VERSION ""

NS_ :

BS_:

BU_: SBZA_R_LS SBZA_L_LS VIS2_LS SDM_LS PEPS_LS UPA_LS PTM_LS MSM_LS HFP_LS EOCM_F_LS ECC_LS DCAC_LS CGM_LS BSM_LS BCM_LS AOS_LS

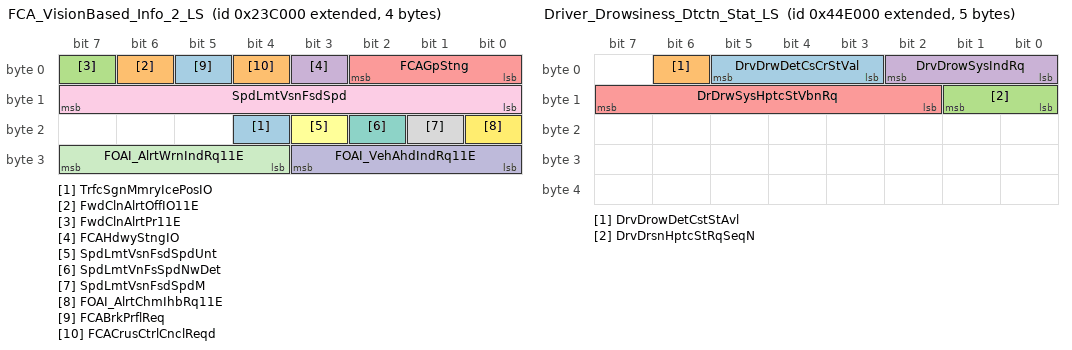
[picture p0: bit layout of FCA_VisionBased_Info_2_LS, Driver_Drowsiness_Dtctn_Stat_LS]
BO_ 2149826560 FCA_VisionBased_Info_2_LS: 4 VIS2_LS
 SG_ TrfcSgnMmryIcePosIO : 20|1@0+ (1,0) [0|1] ""  CGM_LS
 SG_ FwdClnAlrtOffIO11E : 6|1@0+ (1,0) [0|1] ""  CGM_LS
 SG_ FwdClnAlrtPr11E : 7|1@0+ (1,0) [0|1] ""  CGM_LS
 SG_ FCAHdwyStngIO : 3|1@0+ (1,0) [0|1] ""  CGM_LS
 SG_ FCAGpStng : 2|3@0+ (1,0) [0|7] ""  CGM_LS
 SG_ SpdLmtVsnFsdSpdUnt : 19|1@0+ (1,0) [0|1] ""  CGM_LS,BCM_LS
 SG_ SpdLmtVnFsSpdNwDet : 18|1@0+ (1,0) [0|1] ""  CGM_LS,BCM_LS
 SG_ SpdLmtVsnFsdSpdM : 17|1@0+ (1,0) [0|1] ""  CGM_LS,BCM_LS
 SG_ SpdLmtVsnFsdSpd : 15|8@0+ (1,0) [0|255] ""  CGM_LS,BCM_LS
 SG_ FOAI_VehAhdIndRq11E : 27|4@0+ (1,0) [0|15] ""  CGM_LS,BCM_LS
 SG_ FOAI_AlrtWrnIndRq11E : 31|4@0+ (1,0) [0|15] ""  CGM_LS,BCM_LS
 SG_ FOAI_AlrtChmIhbRq11E : 16|1@0+ (1,0) [0|1] ""  CGM_LS,BCM_LS
 SG_ FCABrkPrflReq : 5|1@0+ (1,0) [0|1] ""  CGM_LS,BCM_LS
 SG_ FCACrusCtrlCnclReqd : 4|1@0+ (1,0) [0|1] ""  CGM_LS,BCM_LS

BO_ 2151997440 Driver_Drowsiness_Dtctn_Stat_LS: 5 VIS2_LS
 SG_ DrvDrwDetCsCrStVal : 5|3@0+ (1,0) [0|7] ""  CGM_LS
 SG_ DrvDrowDetCstStAvl : 6|1@0+ (1,0) [0|1] ""  CGM_LS
 SG_ DrvDrsnHptcStRqSeqN : 9|2@0+ (1,0) [0|3] ""  MSM_LS,CGM_LS
 SG_ DrvDrowSysIndRq : 2|3@0+ (1,0) [0|7] ""  CGM_LS,BCM_LS
 SG_ DrDrwSysHptcStVbnRq : 15|6@0+ (1,0) [0|63] ""  MSM_LS,CGM_LS,BCM_LS

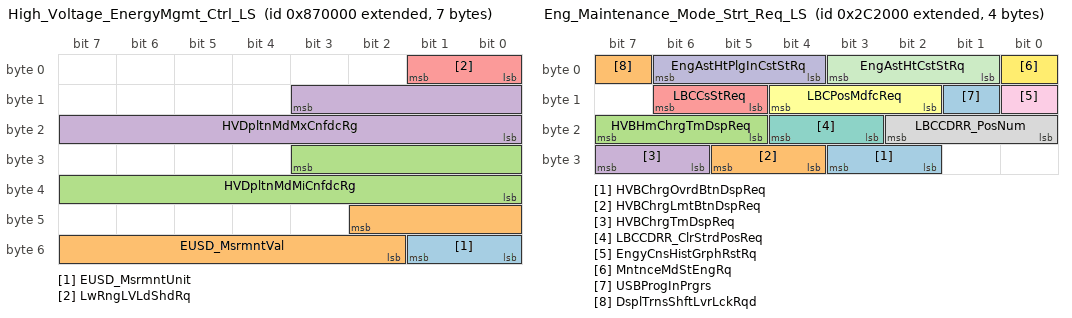
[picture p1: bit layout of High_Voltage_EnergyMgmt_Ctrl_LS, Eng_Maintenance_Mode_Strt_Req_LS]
BO_ 2156331008 High_Voltage_EnergyMgmt_Ctrl_LS: 7 BSM_LS
 SG_ EUSD_MsrmntUnit : 49|2@0+ (1,0) [0|3] ""  CGM_LS
 SG_ EUSD_MsrmntVal : 42|9@0+ (1,0) [0|511] ""  CGM_LS
 SG_ HVDpltnMdMiCnfdcRg : 27|12@0+ (0.1,0) [0|409.5] "km"  CGM_LS
 SG_ HVDpltnMdMxCnfdcRg : 11|12@0+ (0.1,0) [0|409.5] "km"  CGM_LS
 SG_ LwRngLVLdShdRq : 1|2@0+ (1,0) [0|3] ""  CGM_LS,BCM_LS

BO_ 2150375424 Eng_Maintenance_Mode_Strt_Req_LS: 4 CGM_LS
 SG_ HVBChrgOvrdBtnDspReq : 27|2@0+ (1,0) [0|3] "" Vector__XXX
 SG_ HVBChrgLmtBtnDspReq : 29|2@0+ (1,0) [0|3] "" Vector__XXX
 SG_ HVBHmChrgTmDspReq : 23|3@0+ (1,0) [0|7] "" Vector__XXX
 SG_ HVBChrgTmDspReq : 31|2@0+ (1,0) [0|3] "" Vector__XXX
 SG_ LBCCsStReq : 14|2@0+ (1,0) [0|3] ""  BSM_LS
 SG_ LBCPosMdfcReq : 12|3@0+ (1,0) [0|7] ""  BSM_LS
 SG_ LBCCDRR_ClrStrdPosReq : 20|2@0+ (1,0) [0|3] ""  BSM_LS
 SG_ LBCCDRR_PosNum : 18|3@0+ (1,0) [0|7] ""  BSM_LS
 SG_ EngyCnsHistGrphRstRq : 8|1@0+ (1,0) [0|1] ""  BSM_LS
 SG_ EngAstHtPlgInCstStRq : 6|3@0+ (1,0) [0|7] ""  BSM_LS
 SG_ EngAstHtCstStRq : 3|3@0+ (1,0) [0|7] ""  BSM_LS
 SG_ MntnceMdStEngRq : 0|1@0+ (1,0) [0|1] ""  BSM_LS
 SG_ USBProgInPrgrs : 9|1@0+ (1,0) [0|1] ""  BCM_LS
 SG_ DsplTrnsShftLvrLckRqd : 7|1@0+ (1,0) [0|1] ""  BCM_LS

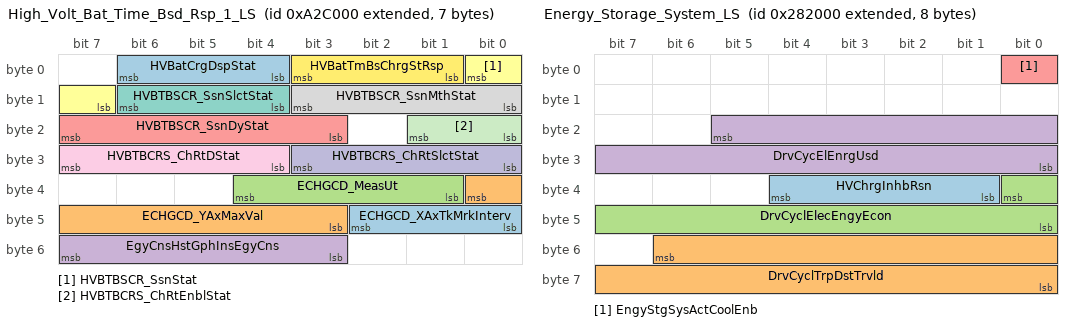
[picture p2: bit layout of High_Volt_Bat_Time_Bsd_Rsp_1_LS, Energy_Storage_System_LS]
BO_ 2158149632 High_Volt_Bat_Time_Bsd_Rsp_1_LS: 7 BSM_LS
 SG_ ECHGCD_XAxTkMrkInterv : 42|3@0+ (1,0) [0|7] ""  CGM_LS
 SG_ ECHGCD_YAxMaxVal : 32|6@0+ (4,0) [0|252] ""  CGM_LS
 SG_ ECHGCD_MeasUt : 36|4@0+ (1,0) [0|15] ""  CGM_LS
 SG_ EgyCnsHstGphInsEgyCns : 55|5@0+ (1,0) [0|31] ""  CGM_LS
 SG_ HVBTBSCR_SsnDyStat : 23|5@0+ (1,0) [0|31] "day"  CGM_LS
 SG_ HVBTBSCR_SsnStat : 0|2@0+ (1,0) [0|3] ""  CGM_LS
 SG_ HVBTBSCR_SsnSlctStat : 14|3@0+ (1,0) [0|7] ""  CGM_LS
 SG_ HVBTBSCR_SsnMthStat : 11|4@0+ (1,0) [0|15] ""  CGM_LS
 SG_ HVBTBCRS_ChRtDStat : 31|4@0+ (1,0) [0|15] ""  CGM_LS
 SG_ HVBTBCRS_ChRtSlctStat : 27|4@0+ (1,0) [0|15] ""  CGM_LS
 SG_ HVBTBCRS_ChRtEnblStat : 17|2@0+ (1,0) [0|3] ""  CGM_LS
 SG_ HVBatTmBsChrgStRsp : 3|3@0+ (1,0) [0|7] ""  CGM_LS,BCM_LS
 SG_ HVBatCrgDspStat : 6|3@0+ (1,0) [0|7] ""  CGM_LS,BCM_LS

BO_ 2150113280 Energy_Storage_System_LS: 8 BSM_LS
 SG_ HVChrgInhbRsn : 36|4@0+ (1,0) [0|15] ""  CGM_LS
 SG_ DrvCyclTrpDstTrvld : 54|15@0+ (0.1,0) [0|3276.7] "km"  CGM_LS
 SG_ DrvCyclElecEngyEcon : 32|9@0+ (0.1,0) [0|51.1] ""  CGM_LS
 SG_ DrvCycElEnrgUsd : 21|14@0+ (0.36,0) [0|5897.88] "MJ"  CGM_LS
 SG_ EngyStgSysActCoolEnb : 0|1@0+ (1,0) [0|1] ""  ECC_LS,CGM_LS,BCM_LS

BO_ 2150547456 HMI_Hybrid_Vehicle_Status_LS: 8 BSM_LS
 SG_ HVDpltnMdCnfdcTrndg : 47|8@0- (0.787402,0) [-100.787456|100.000054] "%"  CGM_LS
 SG_ OffBrdHVCVehPwrLvl : 55|2@0+ (1,0) [0|3] ""  CGM_LS
 SG_ OffBrdHVCVehPwrDrtd : 26|1@0+ (1,0) [0|1] ""  CGM_LS
 SG_ OffBrdHVCVehCplrLkd : 16|1@0+ (1,0) [0|1] ""  CGM_LS
 SG_ OffBrdHVBlkChrgCmp : 37|1@0+ (1,0) [0|1] ""  CGM_LS
 SG_ OBHVBCCT_MinofHr : 61|6@0+ (1,0) [0|63] ""  CGM_LS
 SG_ OBHVBCCT_HrofDay : 50|5@0+ (1,0) [0|31] ""  CGM_LS
 SG_ OBHVBCCT_DayofWk : 53|3@0+ (1,0) [0|7] ""  CGM_LS
 SG_ ElecPrplsnMtrOvrSpdIO : 38|1@0+ (1,0) [0|1] ""  CGM_LS
 SG_ HVBatOutOfEnrgyInd : 36|3@0+ (1,0) [0|7] ""  CGM_LS
 SG_ CntrsOpnUndrTmpIO : 7|1@0+ (1,0) [0|1] ""  CGM_LS
 SG_ HVBatCntctrsOpnIO : 39|1@0+ (1,0) [0|1] ""  CGM_LS
 SG_ GrnAudQueReq : 4|1@0+ (1,0) [0|1] ""  CGM_LS
 SG_ SvcHybChrgSysIO : 5|1@0+ (1,0) [0|1] ""  CGM_LS
 SG_ HVChrgrSysStat : 29|3@0+ (1,0) [0|7] ""  CGM_LS
 SG_ HVChrgrCplrStat : 31|2@0+ (1,0) [0|3] ""  ECC_LS,CGM_LS
 SG_ HVBatLimDTmpInd : 25|2@0+ (1,0) [0|3] ""  CGM_LS
 SG_ VehChrgMdSt : 3|3@0+ (1,0) [0|7] ""  CGM_LS
 SG_ HVBatChrgCrdConnIO : 6|1@0+ (1,0) [0|1] ""  CGM_LS,BCM_LS
 SG_ HVDpltnMdRng : 0|16@0+ (0.015625,0) [0|1023.984375] "km"  CGM_LS,BCM_LS
 SG_ ChgrSysAdblIndReq : 33|2@0+ (1,0) [0|3] ""  CGM_LS,BCM_LS

BO_ 2149728256 Charging_Sys_Trans_Shift_Lock_LS: 5 BSM_LS
 SG_ EngAstHtPlgInCsStAvl : 31|1@0+ (1,0) [0|1] ""  CGM_LS
 SG_ EngAstHtPlgInCsCrStVl : 30|3@0+ (1,0) [0|7] ""  CGM_LS
 SG_ EngAstHtCsStAvl : 27|1@0+ (1,0) [0|1] ""  CGM_LS
 SG_ EngAstHtCsCrStVal : 26|3@0+ (1,0) [0|7] ""  ECC_LS,CGM_LS
 SG_ HghVltgPropState : 7|3@0+ (1,0) [0|7] ""  CGM_LS
 SG_ ChrgPrtDrStat : 2|2@0+ (1,0) [0|3] ""  CGM_LS
 SG_ ChgCdTfAlCzStAvbl : 11|1@0+ (1,0) [0|1] ""  CGM_LS
 SG_ ChgCdTfAlCzCrStVal : 10|3@0+ (1,0) [0|7] ""  CGM_LS
 SG_ ChgPwLsAlCzStAvbl : 15|1@0+ (1,0) [0|1] ""  CGM_LS
 SG_ ChgPwLsAlCzCrStVal : 14|3@0+ (1,0) [0|7] ""  CGM_LS
 SG_ ChgSysAudInCsStAvl : 19|1@0+ (1,0) [0|1] ""  CGM_LS
 SG_ ChgSyAudInCsCrStVa : 18|3@0+ (1,0) [0|7] ""  CGM_LS
 SG_ PrtyChrgStPnt : 38|7@0+ (1,0) [0|127] ""  CGM_LS,BCM_LS
 SG_ PrtyChrgActIO : 3|1@0+ (1,0) [0|1] ""  CGM_LS,BCM_LS
 SG_ PrtyChrgAct : 4|1@0+ (1,0) [0|1] ""  CGM_LS,BCM_LS
 SG_ HVChrgPwrLvl : 22|3@0+ (1,0) [0|7] ""  CGM_LS,BCM_LS
 SG_ ChrgSysTrnsShftLckRq : 0|1@0+ (1,0) [0|1] ""  CGM_LS,BCM_LS

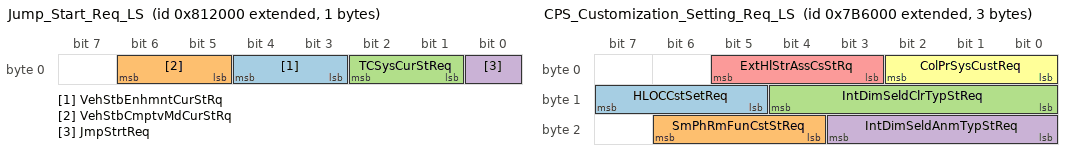
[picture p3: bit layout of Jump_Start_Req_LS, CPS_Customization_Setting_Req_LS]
BO_ 2155945984 Jump_Start_Req_LS: 1 CGM_LS
 SG_ VehStbEnhmntCurStRq : 4|2@0+ (1,0) [0|3] ""  BCM_LS
 SG_ VehStbCmptvMdCurStRq : 6|2@0+ (1,0) [0|3] ""  BCM_LS
 SG_ TCSysCurStReq : 2|2@0+ (1,0) [0|3] ""  BCM_LS
 SG_ JmpStrtReq : 0|1@0+ (1,0) [0|1] ""  BCM_LS

BO_ 2155585536 MSB_Customization_Setting_Req_LS: 1 CGM_LS
 SG_ StBltTgtCSRq : 2|3@0+ (1,0) [0|7] ""  BCM_LS

BO_ 2155569152 CPS_Customization_Setting_Req_LS: 3 CGM_LS
 SG_ HLOCCstSetReq : 15|3@0+ (1,0) [0|7] ""  PTM_LS
 SG_ SmPhRmFunCstStReq : 22|3@0+ (1,0) [0|7] ""  BCM_LS
 SG_ IntDimSeldClrTypStReq : 12|5@0+ (1,0) [0|31] ""  BCM_LS
 SG_ IntDimSeldAnmTypStReq : 19|4@0+ (1,0) [0|15] ""  BCM_LS
 SG_ ExtHlStrAssCsStRq : 5|3@0+ (1,0) [0|7] ""  BCM_LS
 SG_ ColPrSysCustReq : 2|3@0+ (1,0) [0|7] ""  BCM_LS

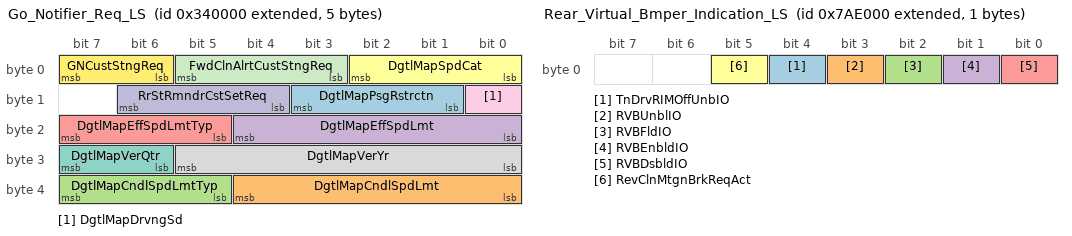
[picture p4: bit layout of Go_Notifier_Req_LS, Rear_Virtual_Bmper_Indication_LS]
BO_ 2150891520 Go_Notifier_Req_LS: 5 CGM_LS
 SG_ DgtlMapPsgRstrctn : 11|3@0+ (1,0) [0|7] ""  VIS2_LS
 SG_ DgtlMapCndlSpdLmt : 36|5@0+ (1,0) [0|31] ""  VIS2_LS
 SG_ DgtlMapCndlSpdLmtTyp : 39|3@0+ (1,0) [0|7] ""  VIS2_LS
 SG_ DgtlMapEffSpdLmt : 20|5@0+ (1,0) [0|31] ""  VIS2_LS
 SG_ DgtlMapEffSpdLmtTyp : 23|3@0+ (1,0) [0|7] ""  VIS2_LS
 SG_ DgtlMapSpdCat : 2|3@0+ (1,0) [0|7] ""  VIS2_LS
 SG_ DgtlMapVerQtr : 31|2@0+ (1,0) [0|3] ""  VIS2_LS
 SG_ DgtlMapVerYr : 29|6@0+ (1,0) [0|63] ""  VIS2_LS
 SG_ DgtlMapDrvngSd : 8|1@0+ (1,0) [0|1] ""  VIS2_LS
 SG_ RrStRmndrCstSetReq : 14|3@0+ (1,0) [0|7] ""  BCM_LS
 SG_ FwdClnAlrtCustStngReq : 5|3@0+ (1,0) [0|7] ""  BCM_LS
 SG_ GNCustStngReq : 7|2@0+ (1,0) [0|3] ""  BCM_LS

BO_ 2155536384 Rear_Virtual_Bmper_Indication_LS: 1 EOCM_F_LS
 SG_ TnDrvRIMOffUnbIO : 4|1@0+ (1,0) [0|1] ""  CGM_LS
 SG_ RVBUnblIO : 3|1@0+ (1,0) [0|1] ""  CGM_LS
 SG_ RVBFldIO : 2|1@0+ (1,0) [0|1] ""  CGM_LS
 SG_ RVBEnbldIO : 1|1@0+ (1,0) [0|1] ""  CGM_LS
 SG_ RVBDsbldIO : 0|1@0+ (1,0) [0|1] ""  SBZA_R_LS,SBZA_L_LS,CGM_LS
 SG_ RevClnMtgnBrkReqAct : 5|1@0+ (1,0) [0|1] ""  CGM_LS,BCM_LS

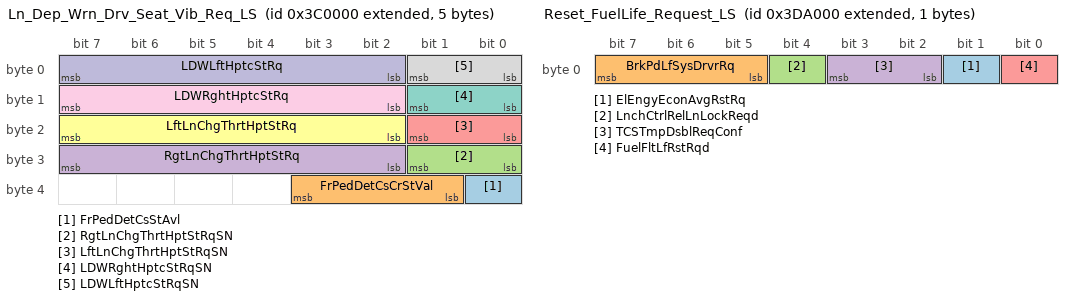
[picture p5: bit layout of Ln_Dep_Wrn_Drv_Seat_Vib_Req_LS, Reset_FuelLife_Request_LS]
BO_ 2151415808 Ln_Dep_Wrn_Drv_Seat_Vib_Req_LS: 5 EOCM_F_LS
 SG_ FrPedDetCsStAvl : 32|1@0+ (1,0) [0|1] ""  MSM_LS,CGM_LS
 SG_ FrPedDetCsCrStVal : 35|3@0+ (1,0) [0|7] ""  MSM_LS,CGM_LS
 SG_ RgtLnChgThrtHptStRqSN : 25|2@0+ (1,0) [0|3] ""  MSM_LS,CGM_LS
 SG_ RgtLnChgThrtHptStRq : 31|6@0+ (1,0) [0|63] "Pulse"  MSM_LS,CGM_LS
 SG_ LftLnChgThrtHptStRqSN : 17|2@0+ (1,0) [0|3] ""  MSM_LS,CGM_LS
 SG_ LftLnChgThrtHptStRq : 23|6@0+ (1,0) [0|63] "Pulse"  MSM_LS,CGM_LS
 SG_ LDWRghtHptcStRqSN : 9|2@0+ (1,0) [0|3] ""  MSM_LS,CGM_LS
 SG_ LDWLftHptcStRqSN : 1|2@0+ (1,0) [0|3] ""  MSM_LS,CGM_LS
 SG_ LDWRghtHptcStRq : 15|6@0+ (1,0) [0|63] ""  MSM_LS,CGM_LS,BCM_LS
 SG_ LDWLftHptcStRq : 7|6@0+ (1,0) [0|63] ""  MSM_LS,CGM_LS,BCM_LS

BO_ 2151522304 Reset_FuelLife_Request_LS: 1 CGM_LS
 SG_ ElEngyEconAvgRstRq : 1|1@0+ (1,0) [0|1] ""  BSM_LS
 SG_ BrkPdLfSysDrvrRq : 7|3@0+ (1,0) [0|7] ""  BCM_LS
 SG_ LnchCtrlRelLnLockReqd : 4|1@0+ (1,0) [0|1] ""  BCM_LS
 SG_ TCSTmpDsblReqConf : 3|2@0+ (1,0) [0|3] ""  BCM_LS
 SG_ FuelFltLfRstRqd : 0|1@0+ (1,0) [0|1] ""  BCM_LS

BO_ 2154979328 Front_Seat_Heat_Cool_Req_LS: 1 MSM_LS
 SG_ FrntStVoltBstModReq : 0|1@0+ (1,0) [0|1] ""  CGM_LS,BCM_LS

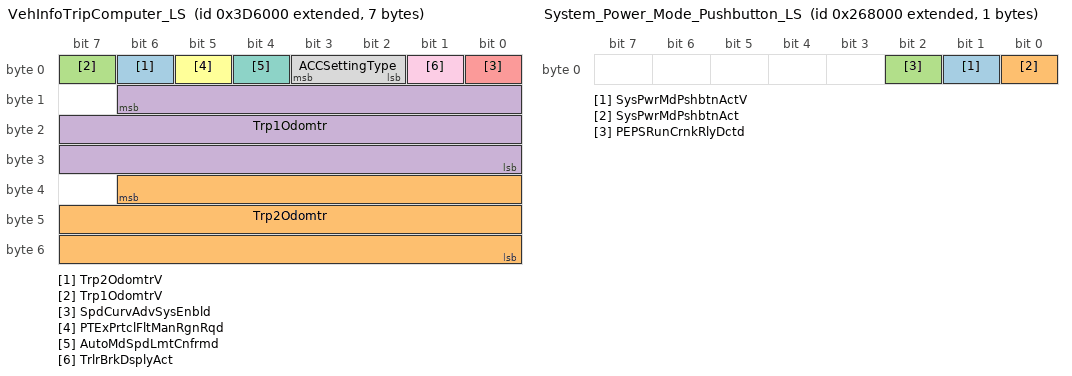
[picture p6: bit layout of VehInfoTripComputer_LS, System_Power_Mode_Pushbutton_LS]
BO_ 2151505920 VehInfoTripComputer_LS: 7 CGM_LS
 SG_ Trp2OdomtrV : 6|1@0+ (1,0) [0|1] "" Vector__XXX
 SG_ Trp2Odomtr : 38|23@0+ (0.015625,0) [0|131071.984375] "km" Vector__XXX
 SG_ Trp1OdomtrV : 7|1@0+ (1,0) [0|1] "" Vector__XXX
 SG_ Trp1Odomtr : 14|23@0+ (0.015625,0) [0|131071.984375] "km" Vector__XXX
 SG_ SpdCurvAdvSysEnbld : 0|1@0+ (1,0) [0|1] "" Vector__XXX
 SG_ PTExPrtclFltManRgnRqd : 5|1@0+ (1,0) [0|1] ""  BCM_LS
 SG_ AutoMdSpdLmtCnfrmd : 4|1@0+ (1,0) [0|1] ""  BCM_LS
 SG_ ACCSettingType : 3|2@0+ (1,0) [0|3] ""  VIS2_LS,BCM_LS
 SG_ TrlrBrkDsplyAct : 1|1@0+ (1,0) [0|1] ""  BCM_LS

BO_ 2155552768 Exterior_Lock_Switch_Req_LS: 1 PEPS_LS
 SG_ PsvEntCmftWndRq : 1|2@0+ (1,0) [0|3] ""  CGM_LS,BCM_LS

BO_ 2150006784 System_Power_Mode_Pushbutton_LS: 1 PEPS_LS
 SG_ SysPwrMdPshbtnActV : 1|1@0+ (1,0) [0|1] ""  CGM_LS,BCM_LS
 SG_ SysPwrMdPshbtnAct : 0|1@0+ (1,0) [0|1] ""  CGM_LS,BCM_LS
 SG_ PEPSRunCrnkRlyDctd : 2|1@0+ (1,0) [0|1] ""  CGM_LS,BCM_LS

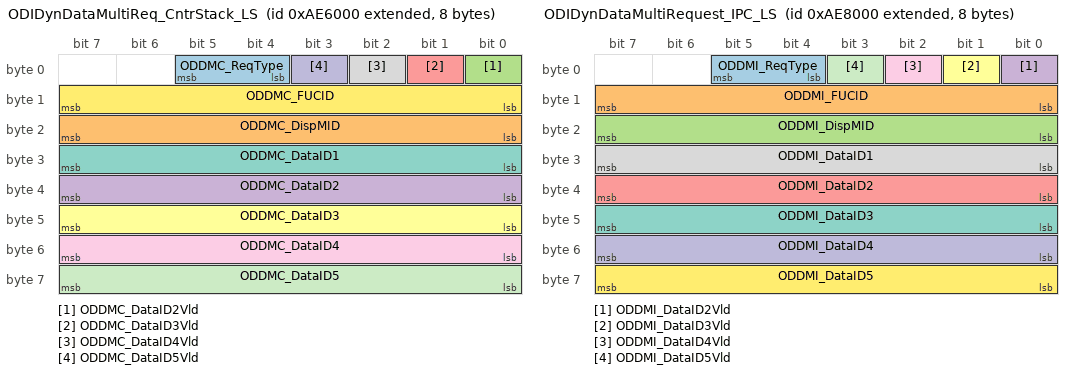
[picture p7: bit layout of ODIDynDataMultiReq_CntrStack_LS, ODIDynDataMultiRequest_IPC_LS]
BO_ 2158911488 ODIDynDataMultiReq_CntrStack_LS: 8 CGM_LS
 SG_ ODDMC_ReqType : 5|2@0+ (1,0) [0|3] ""  SBZA_L_LS,UPA_LS,VIS2_LS,MSM_LS,EOCM_F_LS,ECC_LS,BCM_LS
 SG_ ODDMC_DispMID : 23|8@0+ (1,0) [0|255] ""  SBZA_L_LS,UPA_LS,VIS2_LS,MSM_LS,EOCM_F_LS,ECC_LS,BCM_LS
 SG_ ODDMC_DataID2Vld : 0|1@0+ (1,0) [0|1] ""  SBZA_L_LS,UPA_LS,VIS2_LS,MSM_LS,EOCM_F_LS,ECC_LS,BCM_LS
 SG_ ODDMC_DataID2 : 39|8@0+ (1,0) [0|255] ""  SBZA_L_LS,UPA_LS,VIS2_LS,MSM_LS,EOCM_F_LS,ECC_LS,BCM_LS
 SG_ ODDMC_DataID3Vld : 1|1@0+ (1,0) [0|1] ""  SBZA_L_LS,UPA_LS,VIS2_LS,MSM_LS,EOCM_F_LS,ECC_LS,BCM_LS
 SG_ ODDMC_DataID3 : 47|8@0+ (1,0) [0|255] ""  SBZA_L_LS,UPA_LS,VIS2_LS,MSM_LS,EOCM_F_LS,ECC_LS,BCM_LS
 SG_ ODDMC_DataID1 : 31|8@0+ (1,0) [0|255] ""  SBZA_L_LS,UPA_LS,VIS2_LS,MSM_LS,EOCM_F_LS,ECC_LS,BCM_LS
 SG_ ODDMC_DataID4Vld : 2|1@0+ (1,0) [0|1] ""  SBZA_L_LS,UPA_LS,VIS2_LS,MSM_LS,EOCM_F_LS,ECC_LS,BCM_LS
 SG_ ODDMC_DataID4 : 55|8@0+ (1,0) [0|255] ""  SBZA_L_LS,UPA_LS,VIS2_LS,MSM_LS,EOCM_F_LS,ECC_LS,BCM_LS
 SG_ ODDMC_DataID5Vld : 3|1@0+ (1,0) [0|1] ""  SBZA_L_LS,UPA_LS,VIS2_LS,MSM_LS,EOCM_F_LS,ECC_LS,BCM_LS
 SG_ ODDMC_DataID5 : 63|8@0+ (1,0) [0|255] ""  SBZA_L_LS,UPA_LS,VIS2_LS,MSM_LS,EOCM_F_LS,ECC_LS,BCM_LS
 SG_ ODDMC_FUCID : 15|8@0+ (1,0) [0|255] ""  SBZA_L_LS,UPA_LS,VIS2_LS,MSM_LS,EOCM_F_LS,ECC_LS,BCM_LS

BO_ 2158919680 ODIDynDataMultiRequest_IPC_LS: 8 CGM_LS
 SG_ ODDMI_ReqType : 5|2@0+ (1,0) [0|3] ""  SBZA_L_LS,UPA_LS,VIS2_LS,MSM_LS,EOCM_F_LS,ECC_LS,BCM_LS
 SG_ ODDMI_FUCID : 15|8@0+ (1,0) [0|255] ""  SBZA_L_LS,UPA_LS,VIS2_LS,MSM_LS,EOCM_F_LS,ECC_LS,BCM_LS
 SG_ ODDMI_DispMID : 23|8@0+ (1,0) [0|255] ""  SBZA_L_LS,UPA_LS,VIS2_LS,MSM_LS,EOCM_F_LS,ECC_LS,BCM_LS
 SG_ ODDMI_DataID2Vld : 0|1@0+ (1,0) [0|1] ""  SBZA_L_LS,UPA_LS,VIS2_LS,MSM_LS,EOCM_F_LS,ECC_LS,BCM_LS
 SG_ ODDMI_DataID2 : 39|8@0+ (1,0) [0|255] ""  SBZA_L_LS,UPA_LS,VIS2_LS,MSM_LS,EOCM_F_LS,ECC_LS,BCM_LS
 SG_ ODDMI_DataID3Vld : 1|1@0+ (1,0) [0|1] ""  SBZA_L_LS,UPA_LS,VIS2_LS,MSM_LS,EOCM_F_LS,ECC_LS,BCM_LS
 SG_ ODDMI_DataID3 : 47|8@0+ (1,0) [0|255] ""  SBZA_L_LS,UPA_LS,VIS2_LS,MSM_LS,EOCM_F_LS,ECC_LS,BCM_LS
 SG_ ODDMI_DataID1 : 31|8@0+ (1,0) [0|255] ""  SBZA_L_LS,UPA_LS,VIS2_LS,MSM_LS,EOCM_F_LS,ECC_LS,BCM_LS
 SG_ ODDMI_DataID4Vld : 2|1@0+ (1,0) [0|1] ""  SBZA_L_LS,UPA_LS,VIS2_LS,MSM_LS,EOCM_F_LS,ECC_LS,BCM_LS
 SG_ ODDMI_DataID4 : 55|8@0+ (1,0) [0|255] ""  SBZA_L_LS,UPA_LS,VIS2_LS,MSM_LS,EOCM_F_LS,ECC_LS,BCM_LS
 SG_ ODDMI_DataID5Vld : 3|1@0+ (1,0) [0|1] ""  SBZA_L_LS,UPA_LS,VIS2_LS,MSM_LS,EOCM_F_LS,ECC_LS,BCM_LS
 SG_ ODDMI_DataID5 : 63|8@0+ (1,0) [0|255] ""  SBZA_L_LS,UPA_LS,VIS2_LS,MSM_LS,EOCM_F_LS,ECC_LS,BCM_LS

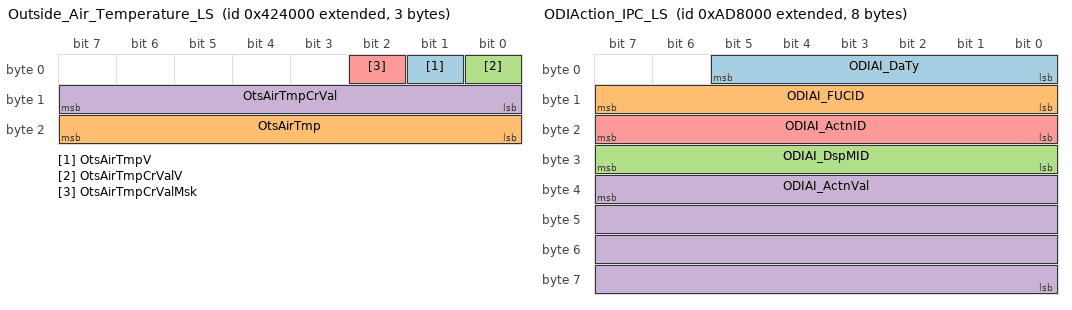
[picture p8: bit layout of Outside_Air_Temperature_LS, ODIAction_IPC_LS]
BO_ 2151825408 Outside_Air_Temperature_LS: 3 BCM_LS
 SG_ OtsAirTmpV : 1|1@0+ (1,0) [0|1] ""  UPA_LS,HFP_LS,EOCM_F_LS,ECC_LS,CGM_LS,BCM_LS
 SG_ OtsAirTmp : 23|8@0+ (0.5,-40) [-40|87.5] "deg C"  UPA_LS,HFP_LS,EOCM_F_LS,ECC_LS,CGM_LS,BCM_LS
 SG_ OtsAirTmpCrValV : 0|1@0+ (1,0) [0|1] ""  UPA_LS,PTM_LS,VIS2_LS,SDM_LS,EOCM_F_LS,ECC_LS,CGM_LS,BCM_LS
 SG_ OtsAirTmpCrVal : 15|8@0+ (0.5,-40) [-40|87.5] "deg C"  UPA_LS,PTM_LS,VIS2_LS,SDM_LS,EOCM_F_LS,ECC_LS,CGM_LS,BCM_LS
 SG_ OtsAirTmpCrValMsk : 2|1@0+ (1,0) [0|1] ""  UPA_LS,PTM_LS,VIS2_LS,SDM_LS,EOCM_F_LS,ECC_LS,CGM_LS,BCM_LS

BO_ 2149711872 ACC_YawRate_Information_LS: 8 BCM_LS
 SG_ SetSpdLmtRchd : 54|2@0+ (1,0) [0|3] ""  CGM_LS
 SG_ FOAI_VehAhdIndRq : 63|4@0+ (1,0) [0|15] ""  CGM_LS
 SG_ FOAI_AlrtWrnIndRq : 59|4@0+ (1,0) [0|15] ""  CGM_LS
 SG_ FOAI_AlrtChmIhbRq : 48|1@0+ (1,0) [0|1] ""  CGM_LS
 SG_ FwdClnAlrtOffIO : 39|1@0+ (1,0) [0|1] ""  CGM_LS
 SG_ FwdClnAlrtPr : 23|1@0+ (1,0) [0|1] ""  CGM_LS
 SG_ ACCHdwyStg : 22|3@0+ (1,0) [0|7] ""  CGM_LS
 SG_ ACCDrvrSeltdSpd : 3|12@0+ (0.0625,0) [0|255.9375] "km / h"  CGM_LS
 SG_ AdapCrsCntVDA : 4|1@0+ (1,0) [0|1] ""  CGM_LS
 SG_ SpdLmtrSpdWrngEnbld : 37|1@0+ (1,0) [0|1] ""  CGM_LS
 SG_ CrsCntlDrSelSpdAct : 7|1@0+ (1,0) [0|1] ""  CGM_LS
 SG_ SpdLmtrSpdWrngAct : 38|1@0+ (1,0) [0|1] ""  CGM_LS
 SG_ CrsSpdLmtrDrvSelSpd : 19|12@0+ (0.0625,0) [0|255.9375] "km / h"  CGM_LS
 SG_ AutoMdSpdLmtStat : 50|2@0+ (1,0) [0|3] ""  VIS2_LS,CGM_LS
 SG_ ACCAutoSetSpdStat : 52|2@0+ (1,0) [0|3] ""  VIS2_LS,CGM_LS
 SG_ VehDynYawRateV : 36|1@0+ (1,0) [0|1] ""  SBZA_R_LS,SBZA_L_LS,UPA_LS,CGM_LS
 SG_ VehDynYawRate : 35|12@0- (0.0625,0) [-128|127.9375] "deg/sec"  SBZA_R_LS,SBZA_L_LS,UPA_LS,CGM_LS
 SG_ ACCAct370 : 6|1@0+ (1,0) [0|1] ""  VIS2_LS,CGM_LS

BO_ 2162982912 VIN_Digits_10_to_17: 8 BCM_LS
 SG_ VehIdNmDig10_17 : 7|64@0+ (1,0) [0|1] ""  SBZA_R_LS,SBZA_L_LS,UPA_LS,VIS2_LS,SDM_LS,EOCM_F_LS,ECC_LS,CGM_LS

BO_ 2162966528 VIN_Digits_2_to_9: 8 BCM_LS
 SG_ VehIdNmDig2_9 : 7|64@0+ (1,0) [0|1] ""  SBZA_R_LS,SBZA_L_LS,UPA_LS,VIS2_LS,SDM_LS,EOCM_F_LS,ECC_LS,CGM_LS

BO_ 601 USDT_Req_to_UPA_APA_LS: 8 CGM_LS
 SG_ DgnInf : 7|64@0+ (1,0) [0|1.84467440737096E+019] ""  UPA_LS

BO_ 2158854144 ODIAction_IPC_LS: 8 CGM_LS
 SG_ ODIAI_DaTy : 5|6@0+ (1,0) [0|63] ""  UPA_LS,VIS2_LS,MSM_LS,EOCM_F_LS,SBZA_L_LS,ECC_LS,BCM_LS
 SG_ ODIAI_FUCID : 15|8@0+ (1,0) [0|255] ""  UPA_LS,VIS2_LS,MSM_LS,EOCM_F_LS,ECC_LS,SBZA_L_LS,BCM_LS
 SG_ ODIAI_DspMID : 31|8@0+ (1,0) [0|255] ""  UPA_LS,VIS2_LS,MSM_LS,EOCM_F_LS,ECC_LS,SBZA_L_LS,BCM_LS
 SG_ ODIAI_ActnVal : 39|32@0+ (1,0) [0|4294967295] ""  UPA_LS,VIS2_LS,MSM_LS,EOCM_F_LS,ECC_LS,SBZA_L_LS,BCM_LS
 SG_ ODIAI_ActnID : 23|8@0+ (1,0) [0|255] ""  UPA_LS,VIS2_LS,MSM_LS,EOCM_F_LS,ECC_LS,SBZA_L_LS,BCM_LS

BO_ 2149629952 Lighting_Status_LS: 5 BCM_LS
 SG_ RtTrnLmpOn : 34|1@0+ (1,0) [0|1] ""  CGM_LS
 SG_ LftTrnLmpOn : 35|1@0+ (1,0) [0|1] ""  CGM_LS
 SG_ FrFogLmpsAct : 7|1@0+ (1,0) [0|1] ""  VIS2_LS,EOCM_F_LS,CGM_LS
 SG_ HiBmReqd : 20|1@0+ (1,0) [0|1] ""  VIS2_LS,EOCM_F_LS,CGM_LS
 SG_ PrkLtRightOn : 22|1@0+ (1,0) [0|1] ""  CGM_LS
 SG_ PrkLtLeftOn : 8|1@0+ (1,0) [0|1] ""  CGM_LS
 SG_ PrkLtRightIO : 4|1@0+ (1,0) [0|1] ""  CGM_LS
 SG_ MainLghtSw : 31|2@0+ (1,0) [0|3] "N/A"  EOCM_F_LS,CGM_LS,VIS2_LS
 SG_ PrkLtLeftIO : 3|1@0+ (1,0) [0|1] ""  CGM_LS
 SG_ HiBmIO : 13|1@0+ (1,0) [0|1] ""  CGM_LS,VIS2_LS
 SG_ FrFgLtIO : 9|1@0+ (1,0) [0|1] ""  CGM_LS,VIS2_LS
 SG_ AutoLtsInactIO : 10|1@0+ (1,0) [0|1] ""  CGM_LS
 SG_ AutoLtsActIO : 11|1@0+ (1,0) [0|1] ""  CGM_LS
 SG_ RevLmpAtv : 17|1@0+ (1,0) [0|1] "N/A"  CGM_LS,VIS2_LS
 SG_ HdlmpBmSelectStat : 33|2@0+ (1,0) [0|3] ""  EOCM_F_LS,CGM_LS,VIS2_LS
 SG_ SrvlnceMdAct : 23|1@0+ (1,0) [0|1] ""  EOCM_F_LS,CGM_LS,VIS2_LS
 SG_ RrFgLtIO : 12|1@0+ (1,0) [0|1] ""  CGM_LS
 SG_ PrkLtIO : 14|1@0+ (1,0) [0|1] ""  CGM_LS
 SG_ RrFogLmpsAct : 19|1@0+ (1,0) [0|1] ""  EOCM_F_LS,CGM_LS,VIS2_LS
 SG_ PrkngLtsAct : 18|1@0+ (1,0) [0|1] ""  CGM_LS
 SG_ BrkLtsAtv : 15|1@0+ (1,0) [0|1] ""  CGM_LS
 SG_ AutoBmSlctAllwd : 21|1@0+ (1,0) [0|1] ""  EOCM_F_LS,CGM_LS,VIS2_LS
 SG_ FlToPsSwAtv : 16|1@0+ (1,0) [0|1] ""  EOCM_F_LS,CGM_LS,VIS2_LS
 SG_ DRLAct : 1|1@0+ (1,0) [0|1] ""  CGM_LS
 SG_ TrnSwAct : 6|2@0+ (1,0) [0|3] ""  SBZA_R_LS,UPA_LS,VIS2_LS,CGM_LS,SBZA_L_LS
 SG_ HazSwAtv : 2|1@0+ (1,0) [0|1] ""  CGM_LS
 SG_ LftTrnLmpAtv : 29|2@0+ (1,0) [0|3] ""  SBZA_R_LS,UPA_LS,EOCM_F_LS,CGM_LS,SBZA_L_LS
 SG_ RtTrnLmpAtv : 25|2@0+ (1,0) [0|3] ""  SBZA_R_LS,UPA_LS,EOCM_F_LS,CGM_LS,SBZA_L_LS
 SG_ OtsdAmbtLtLvlStatV : 0|1@0+ (1,0) [0|1] ""  SBZA_R_LS,UPA_LS,EOCM_F_LS,CGM_LS,SBZA_L_LS,VIS2_LS
 SG_ OtsdAmbtLtLvlStat : 27|2@0+ (1,0) [0|3] ""  SBZA_R_LS,UPA_LS,EOCM_F_LS,CGM_LS,SBZA_L_LS,VIS2_LS

BO_ 2155028480 Lane_Change_Threat_LS: 2 UPA_LS
 SG_ RtLnChngThrtAprchSpd : 15|8@0- (1,0) [-128|127] "km/h"  CGM_LS,BCM_LS
 SG_ RgtLnChgThrt : 0|1@0+ (1,0) [0|1] ""  VIS2_LS,EOCM_F_LS,CGM_LS,BCM_LS

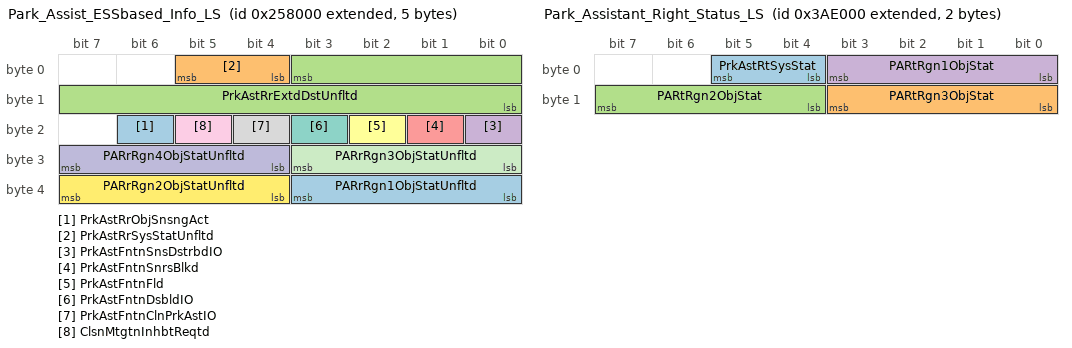
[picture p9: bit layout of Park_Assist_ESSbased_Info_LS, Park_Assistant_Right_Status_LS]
BO_ 2149941248 Park_Assist_ESSbased_Info_LS: 5 UPA_LS
 SG_ PrkAstRrObjSnsngAct : 22|1@0+ (1,0) [0|1] ""  EOCM_F_LS,CGM_LS
 SG_ PrkAstRrSysStatUnfltd : 5|2@0+ (1,0) [0|3] ""  EOCM_F_LS,CGM_LS
 SG_ PrkAstRrExtdDstUnfltd : 3|12@0+ (0.01,0) [0|40.95] "m"  EOCM_F_LS,CGM_LS
 SG_ PrkAstFntnSnsDstrbdIO : 16|1@0+ (1,0) [0|1] ""  SBZA_R_LS,SBZA_L_LS,EOCM_F_LS,CGM_LS
 SG_ PrkAstFntnSnrsBlkd : 17|1@0+ (1,0) [0|1] ""  SBZA_R_LS,SBZA_L_LS,EOCM_F_LS,CGM_LS
 SG_ PrkAstFntnFld : 18|1@0+ (1,0) [0|1] ""  SBZA_R_LS,SBZA_L_LS,EOCM_F_LS,CGM_LS
 SG_ PrkAstFntnDsbldIO : 19|1@0+ (1,0) [0|1] ""  SBZA_R_LS,SBZA_L_LS,EOCM_F_LS,CGM_LS
 SG_ PrkAstFntnClnPrkAstIO : 20|1@0+ (1,0) [0|1] ""  SBZA_R_LS,SBZA_L_LS,EOCM_F_LS,CGM_LS
 SG_ ClsnMtgtnInhbtReqtd : 21|1@0+ (1,0) [0|1] ""  EOCM_F_LS,CGM_LS
 SG_ PARrRgn4ObjStatUnfltd : 31|4@0+ (1,0) [0|15] ""  EOCM_F_LS,CGM_LS
 SG_ PARrRgn3ObjStatUnfltd : 27|4@0+ (1,0) [0|15] ""  EOCM_F_LS,CGM_LS
 SG_ PARrRgn2ObjStatUnfltd : 39|4@0+ (1,0) [0|15] ""  EOCM_F_LS,CGM_LS
 SG_ PARrRgn1ObjStatUnfltd : 35|4@0+ (1,0) [0|15] ""  EOCM_F_LS,CGM_LS

BO_ 2151342080 Park_Assistant_Right_Status_LS: 2 UPA_LS
 SG_ PrkAstRtSysStat : 5|2@0+ (1,0) [0|3] ""  CGM_LS
 SG_ PARtRgn3ObjStat : 11|4@0+ (1,0) [0|15] ""  CGM_LS
 SG_ PARtRgn2ObjStat : 15|4@0+ (1,0) [0|15] ""  CGM_LS
 SG_ PARtRgn1ObjStat : 3|4@0+ (1,0) [0|15] ""  CGM_LS

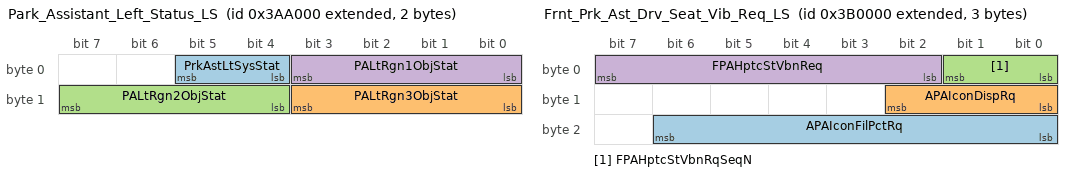
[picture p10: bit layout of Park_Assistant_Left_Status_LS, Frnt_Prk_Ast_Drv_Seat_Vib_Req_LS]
BO_ 2151325696 Park_Assistant_Left_Status_LS: 2 UPA_LS
 SG_ PrkAstLtSysStat : 5|2@0+ (1,0) [0|3] ""  CGM_LS
 SG_ PALtRgn3ObjStat : 11|4@0+ (1,0) [0|15] ""  CGM_LS
 SG_ PALtRgn2ObjStat : 15|4@0+ (1,0) [0|15] ""  CGM_LS
 SG_ PALtRgn1ObjStat : 3|4@0+ (1,0) [0|15] ""  CGM_LS

BO_ 2151350272 Frnt_Prk_Ast_Drv_Seat_Vib_Req_LS: 3 UPA_LS
 SG_ APAIconFilPctRq : 22|7@0+ (1,0) [0|127] ""  CGM_LS
 SG_ APAIconDispRq : 10|3@0+ (1,0) [0|7] ""  CGM_LS
 SG_ FPAHptcStVbnRqSeqN : 1|2@0+ (1,0) [0|3] ""  MSM_LS,CGM_LS
 SG_ FPAHptcStVbnReq : 7|6@0+ (1,0) [0|63] ""  MSM_LS,CGM_LS

BO_ 2151333888 Rear_Prk_Ast_Drv_Seat_Vib_Req_LS: 1 EOCM_F_LS
 SG_ RPAHptcStVbRqSeqN : 1|2@0+ (1,0) [0|3] ""  MSM_LS,CGM_LS
 SG_ RPAHptcStVbnReq : 7|6@0+ (1,0) [0|63] ""  MSM_LS,CGM_LS

BO_ 2158796800 ODIIndication_LS: 8 BCM_LS
 SG_ ODII_ODIInd55 : 57|1@0+ (1,0) [0|1] ""  CGM_LS
 SG_ ODII_ODIInd54 : 58|1@0+ (1,0) [0|1] ""  CGM_LS
 SG_ ODII_ODIInd53 : 59|1@0+ (1,0) [0|1] ""  CGM_LS
 SG_ ODII_ODIInd52 : 60|1@0+ (1,0) [0|1] ""  CGM_LS
 SG_ ODII_ODIInd51 : 61|1@0+ (1,0) [0|1] ""  CGM_LS
 SG_ ODII_ODIInd50 : 62|1@0+ (1,0) [0|1] ""  CGM_LS
 SG_ ODII_ODIInd27 : 37|1@0+ (1,0) [0|1] ""  CGM_LS
 SG_ ODII_ODIInd26 : 38|1@0+ (1,0) [0|1] ""  CGM_LS
 SG_ ODII_ODIInd25 : 39|1@0+ (1,0) [0|1] ""  CGM_LS
 SG_ ODII_ODIInd24 : 24|1@0+ (1,0) [0|1] ""  CGM_LS
 SG_ ODII_ODIInd23 : 25|1@0+ (1,0) [0|1] ""  CGM_LS
 SG_ ODII_ODIInd22 : 26|1@0+ (1,0) [0|1] ""  CGM_LS
 SG_ ODII_ODIInd21 : 27|1@0+ (1,0) [0|1] ""  CGM_LS
 SG_ ODII_ODIInd20 : 28|1@0+ (1,0) [0|1] ""  CGM_LS
 SG_ ODII_ODIInd19 : 29|1@0+ (1,0) [0|1] ""  CGM_LS
 SG_ ODII_ODIInd18 : 30|1@0+ (1,0) [0|1] ""  CGM_LS
 SG_ ODII_ODIInd17 : 31|1@0+ (1,0) [0|1] ""  CGM_LS
 SG_ ODII_ODIInd16 : 16|1@0+ (1,0) [0|1] ""  CGM_LS
 SG_ ODII_ODIInd15 : 17|1@0+ (1,0) [0|1] ""  CGM_LS
 SG_ ODII_ODIInd14 : 18|1@0+ (1,0) [0|1] ""  CGM_LS
 SG_ ODII_ODIInd13 : 19|1@0+ (1,0) [0|1] ""  CGM_LS
 SG_ ODII_ODIInd12 : 20|1@0+ (1,0) [0|1] ""  CGM_LS
 SG_ ODII_ODIInd11 : 21|1@0+ (1,0) [0|1] ""  CGM_LS
 SG_ ODII_ODIInd10 : 22|1@0+ (1,0) [0|1] ""  CGM_LS
 SG_ ODII_ODIInd9 : 23|1@0+ (1,0) [0|1] ""  CGM_LS
 SG_ ODII_ODIInd8 : 8|1@0+ (1,0) [0|1] ""  CGM_LS
 SG_ ODII_ODIInd7 : 9|1@0+ (1,0) [0|1] ""  CGM_LS
 SG_ ODII_ODIInd6 : 10|1@0+ (1,0) [0|1] ""  CGM_LS
 SG_ ODII_ODIInd5 : 11|1@0+ (1,0) [0|1] ""  CGM_LS
 SG_ ODII_ODIInd4 : 12|1@0+ (1,0) [0|1] ""  CGM_LS
 SG_ ODII_ODIInd3 : 13|1@0+ (1,0) [0|1] ""  CGM_LS
 SG_ ODII_ODIInd2 : 14|1@0+ (1,0) [0|1] ""  CGM_LS
 SG_ ODII_ODIInd1 : 15|1@0+ (1,0) [0|1] ""  CGM_LS
 SG_ ODII_ODIInd56 : 56|1@0+ (1,0) [0|1] ""  CGM_LS
 SG_ ODII_ODIInd49 : 63|1@0+ (1,0) [0|1] ""  CGM_LS
 SG_ ODII_ODIInd48 : 48|1@0+ (1,0) [0|1] ""  CGM_LS
 SG_ ODII_ODIInd47 : 49|1@0+ (1,0) [0|1] ""  CGM_LS
 SG_ ODII_ODIInd46 : 50|1@0+ (1,0) [0|1] ""  CGM_LS
 SG_ ODII_ODIInd45 : 51|1@0+ (1,0) [0|1] ""  CGM_LS
 SG_ ODII_ODIInd44 : 52|1@0+ (1,0) [0|1] ""  CGM_LS
 SG_ ODII_ODIInd43 : 53|1@0+ (1,0) [0|1] ""  CGM_LS
 SG_ ODII_ODIInd42 : 54|1@0+ (1,0) [0|1] ""  CGM_LS
 SG_ ODII_ODIInd41 : 55|1@0+ (1,0) [0|1] ""  CGM_LS
 SG_ ODII_ODIInd40 : 40|1@0+ (1,0) [0|1] ""  CGM_LS
 SG_ ODII_ODIInd39 : 41|1@0+ (1,0) [0|1] ""  CGM_LS
 SG_ ODII_ODIInd38 : 42|1@0+ (1,0) [0|1] ""  CGM_LS
 SG_ ODII_ODIInd37 : 43|1@0+ (1,0) [0|1] ""  CGM_LS
 SG_ ODII_ODIInd36 : 44|1@0+ (1,0) [0|1] ""  CGM_LS
 SG_ ODII_ODIInd35 : 45|1@0+ (1,0) [0|1] ""  CGM_LS
 SG_ ODII_ODIInd34 : 46|1@0+ (1,0) [0|1] ""  CGM_LS
 SG_ ODII_ODIInd33 : 47|1@0+ (1,0) [0|1] ""  CGM_LS
 SG_ ODII_ODIInd32 : 32|1@0+ (1,0) [0|1] ""  CGM_LS
 SG_ ODII_ODIInd31 : 33|1@0+ (1,0) [0|1] ""  CGM_LS
 SG_ ODII_ODIInd30 : 34|1@0+ (1,0) [0|1] ""  CGM_LS
 SG_ ODII_ODIInd29 : 35|1@0+ (1,0) [0|1] ""  CGM_LS
 SG_ ODII_ODIInd28 : 36|1@0+ (1,0) [0|1] ""  CGM_LS
 SG_ ODII_FUCID : 7|8@0+ (1,0) [0|255] ""  CGM_LS

BO_TX_BU_ 2151825408 : CGM_LS,BCM_LS;
BO_TX_BU_ 2155028480 : SBZA_R_LS,SBZA_L_LS,UPA_LS;
BO_TX_BU_ 2151333888 : UPA_LS,EOCM_F_LS;
BO_TX_BU_ 2158796800 : SBZA_L_LS,UPA_LS,VIS2_LS,MSM_LS,EOCM_F_LS,ECC_LS,BCM_LS;
CM_ SG_ 2158911488 ODDMC_ReqType "ODI - Type of Request";
CM_ SG_ 2158911488 ODDMC_DispMID "ODI - ID that identifies the display requesting the data.  See detailed requirements in ODI GMLAN Protocol.";
CM_ SG_ 2158911488 ODDMC_DataID2Vld "ODI -DataIDTwo is being requested as a valid ID.";
CM_ SG_ 2158911488 ODDMC_DataID2 "ODI - ID for the second requested data parameter as defined in the FUDatabase";
CM_ SG_ 2158911488 ODDMC_DataID3Vld "ODI -DataIDThree is being requested as a valid ID.";
CM_ SG_ 2158911488 ODDMC_DataID3 "ODI - ID for the third requested data parameter as defined in the FUDatabase";
CM_ SG_ 2158911488 ODDMC_DataID1 "ODI - ID for the first requested data parameter as defined in the FUDatabase";
CM_ SG_ 2158911488 ODDMC_DataID4Vld "ODI -DataIDFour is being requested as a valid ID.";
CM_ SG_ 2158911488 ODDMC_DataID4 "ODI - ID for the fourth requested data parameter as defined in the FUDatabase";
CM_ SG_ 2158911488 ODDMC_DataID5Vld "ODI -DataIDFive is being requested as a valid ID.";
CM_ SG_ 2158911488 ODDMC_DataID5 "ODI - ID for the fifth requested data parameter as defined in the FUDatabase";
CM_ SG_ 2158911488 ODDMC_FUCID "ODI - Primary ID of Functional Unit in FU Database";
CM_ SG_ 2158919680 ODDMI_ReqType "ODI - Type of Request";
CM_ SG_ 2158919680 ODDMI_FUCID "ODI - Primary ID of Functional Unit in FU Database";
CM_ SG_ 2158919680 ODDMI_DispMID "ODI - ID that identifies the display requesting the data.  See detailed requirements in ODI GMLAN Protocol.";
CM_ SG_ 2158919680 ODDMI_DataID2Vld "ODI -DataIDTwo is being requested as a valid ID.";
CM_ SG_ 2158919680 ODDMI_DataID2 "ODI - ID for the second requested data parameter as defined in the FUDatabase";
CM_ SG_ 2158919680 ODDMI_DataID3Vld "ODI -DataIDThree is being requested as a valid ID.";
CM_ SG_ 2158919680 ODDMI_DataID3 "ODI - ID for the third requested data parameter as defined in the FUDatabase";
CM_ SG_ 2158919680 ODDMI_DataID1 "ODI - ID for the first requested data parameter as defined in the FUDatabase";
CM_ SG_ 2158919680 ODDMI_DataID4Vld "ODI -DataIDFour is being requested as a valid ID.";
CM_ SG_ 2158919680 ODDMI_DataID4 "ODI - ID for the fourth requested data parameter as defined in the FUDatabase";
CM_ SG_ 2158919680 ODDMI_DataID5Vld "ODI -DataIDFive is being requested as a valid ID.";
CM_ SG_ 2158919680 ODDMI_DataID5 "ODI - ID for the fifth requested data parameter as defined in the FUDatabase";
CM_ SG_ 2149711872 ACCHdwyStg "Headway is the  time which results from dividing the following distance (or gap) between vehicles by the vehicle speed.  This setting allows the driver to choose a Headway Setting without actually knowing the value of this time.";
CM_ SG_ 2162982912 VehIdNmDig10_17 "Desc: 8 ASCII Characters";
CM_ SG_ 2162966528 VehIdNmDig2_9 "Desc: 8 ASCII Characters";
CM_ SG_ 2158854144 ODIAI_FUCID "ODI - Primary ID of Functional Unit in FU Database";
CM_ SG_ 2158854144 ODIAI_DspMID "ODI - ID that identifies the display requesting the data.  See detailed requirements in ODI GMLAN Protocol.";
CM_ SG_ 2158854144 ODIAI_ActnVal "ODI-Integer value for Actions with values.
FUDatabase definition of Action includes ActionDataType that defines whether or not Action has a value. 
For Actions without a value, this field is always sent as 0.";
CM_ SG_ 2158854144 ODIAI_ActnID "ODI-ActionId within the FUClass";
CM_ SG_ 2149629952 MainLghtSw "Operator selection for the main lighting switch";
CM_ SG_ 2149629952 RevLmpAtv "Indicates if backup lamps are active - Changed name to Reversing Lamps Active";
CM_ SG_ 2158796800 ODII_FUCID "ODI - Primary ID of Functional Unit in FU Database";
BA_DEF_ SG_  "VNSigDiagnostic" ENUM  "No","Yes","DLCLS","DLCHS","DLCCE","DLCFO";
BA_DEF_ SG_  "VNSigUnused_4" ENUM  "No","Yes","DLCLS","DLCHS","DLCCE","DLCFO";
BA_DEF_ SG_  "VNSigIntermediate" ENUM  "No","Yes","DLCLS","DLCHS","DLCCE","DLCFO";
BA_DEF_ SG_  "VNSigParkedVehicle" ENUM  "No","Yes","DLCLS","DLCHS","DLCCE","DLCFO";
BA_DEF_ SG_  "VNSigRemoteDiagnostics" ENUM  "No","Yes","DLCLS","DLCHS","DLCCE","DLCFO";
BA_DEF_ SG_  "GenSigSendOnInit" ENUM  "Not Initialized","Application","Handler","DLCLS","DLCHS","DLCCE","DLCFO";
BA_DEF_ SG_  "GenSigSendType" ENUM  "not used","not used","not used","not used","not used","not used","not used","NoSigSendType","not used","not used","OnAnyChange","OnChangeIfActive","OnDelta","DLCLS","DLCHS","DLCCE","DLCFO";
BA_DEF_ SG_  "GenSigInactiveValue" INT 0 0;
BA_DEF_ SG_  "GenSigDeltaValue" INT 0 0;
BA_DEF_ SG_  "VNSigAllNodes" ENUM  "No","Yes","DLCLS","DLCHS","DLCCE","DLCFO";
BA_DEF_ SG_  "SignalType" STRING ;
BA_DEF_ SG_  "PacketOrder" INT 0 65535;
BA_DEF_ SG_  "SignalLongName" STRING ;
BA_DEF_ SG_  "GenSigStartValue" INT 0 65535;
BA_DEF_ SG_  "TxSignalSendOnInit" ENUM  "Not Initialized","Application","Handler";
BA_DEF_ BO_  "GenMsgILSupport" ENUM  "No","Yes","DLCLS","DLCHS","DLCCE","DLCFO";
BA_DEF_ BO_  "TpApplType" STRING ;
BA_DEF_ BO_  "Prio" INT 0 7;
BA_DEF_ BO_  "MessageSubnet" ENUM  "LS","MS","HS","CE","PE","HV","FO","S1","HE","LE","HE2","DLCLS","DLCHS","DLCCE","DLCFO","vector_leerstring";
BA_DEF_ BO_  "DiagState" ENUM  "No","Yes";
BA_DEF_ BO_  "GenMsgIlSupport" ENUM  "No","Yes";
BA_DEF_ BO_  "GenMsgStartDelayTime" INT 0 100000;
BA_DEF_ BO_  "GenMsgDelayTime" INT 0 100000;
BA_DEF_ BO_  "GenMsgCycleTime" INT 0 100000;
BA_DEF_ BO_  "GenMsgSendType" ENUM  "cyclicX","spontanX","cyclicIfActiveX","spontanWithDelay","cyclicAndSpontanX","cyclicAndSpontanWithDelay","spontanWithRepitition","cyclicIfActiveAndSpontanWD";
BA_DEF_ BO_  "DiagResponse" ENUM  "No","Yes";
BA_DEF_ BO_  "DiagRequest" ENUM  "No","Yes";
BA_DEF_ BO_  "NmMessage" ENUM  "No","Yes";
BA_DEF_REL_ BU_SG_REL_  "GenSigSuprvResp" ENUM  "None","Notify App","Substitute Default","DLCLS","DLCHS","DLCCE","DLCFO";
BA_DEF_REL_ BU_SG_REL_  "GenSigSuprvRespSubValue" INT 0 65535;
BA_DEF_REL_ BU_SG_REL_  "GenSigRxStartValue" STRING ;
BA_DEF_REL_ BU_SG_REL_  "GenSigVDAFailResp" ENUM  "No","Yes","DLCLS","DLCHS","DLCCE","DLCFO";
BA_DEF_REL_ BU_SG_REL_  "GenSigVDAFailComment" STRING ;
BA_DEF_REL_ BU_SG_REL_  "GenSigVBitRespComment" STRING ;
BA_DEF_REL_ BU_SG_REL_  "GenSigVBitResp" ENUM  "No","Yes","DLCLS","DLCHS","DLCCE","DLCFO";
BA_DEF_REL_ BU_SG_REL_  "GenSigSuprvRespComment" STRING ;
BA_DEF_REL_ BU_SG_REL_  "GenSigTimeoutTime" INT 0 5000;
BA_DEF_DEF_  "VNSigDiagnostic" "No";
BA_DEF_DEF_  "VNSigUnused_4" "No";
BA_DEF_DEF_  "VNSigIntermediate" "No";
BA_DEF_DEF_  "VNSigParkedVehicle" "No";
BA_DEF_DEF_  "VNSigRemoteDiagnostics" "No";
BA_DEF_DEF_  "GenSigSendOnInit" "Not Initialized";
BA_DEF_DEF_  "GenSigSendType" "NoSigSendType";
BA_DEF_DEF_  "GenSigInactiveValue" 0;
BA_DEF_DEF_  "GenSigDeltaValue" 0;
BA_DEF_DEF_  "VNSigAllNodes" "No";
BA_DEF_DEF_  "SignalType" "";
BA_DEF_DEF_  "PacketOrder" 0;
BA_DEF_DEF_  "SignalLongName" "";
BA_DEF_DEF_  "GenSigStartValue" 0;
BA_DEF_DEF_  "TxSignalSendOnInit" "Not Initialized";
BA_DEF_DEF_  "GenMsgILSupport" "Yes";
BA_DEF_DEF_  "TpApplType" "";
BA_DEF_DEF_  "Prio" 0;
BA_DEF_DEF_  "MessageSubnet" "LS";
BA_DEF_DEF_  "DiagState" "No";
BA_DEF_DEF_  "GenMsgIlSupport" "Yes";
BA_DEF_DEF_  "GenMsgStartDelayTime" 0;
BA_DEF_DEF_  "GenMsgDelayTime" 0;
BA_DEF_DEF_  "GenMsgCycleTime" 0;
BA_DEF_DEF_  "GenMsgSendType" "spontanX";
BA_DEF_DEF_  "DiagResponse" "No";
BA_DEF_DEF_  "DiagRequest" "No";
BA_DEF_DEF_  "NmMessage" "No";
BA_DEF_DEF_REL_ "GenSigSuprvResp" "None";
BA_DEF_DEF_REL_ "GenSigSuprvRespSubValue" 0;
BA_DEF_DEF_REL_ "GenSigRxStartValue" "";
BA_DEF_DEF_REL_ "GenSigVDAFailResp" "No";
BA_DEF_DEF_REL_ "GenSigVDAFailComment" "";
BA_DEF_DEF_REL_ "GenSigVBitRespComment" "";
BA_DEF_DEF_REL_ "GenSigVBitResp" "No";
BA_DEF_DEF_REL_ "GenSigSuprvRespComment" "";
BA_DEF_DEF_REL_ "GenSigTimeoutTime" 0;
BA_ "Prio" BO_ 2149826560 4;
BA_ "GenMsgDelayTime" BO_ 2149826560 100;
BA_ "Prio" BO_ 2151997440 4;
BA_ "GenMsgDelayTime" BO_ 2151997440 100;
BA_ "Prio" BO_ 2156331008 4;
BA_ "GenMsgDelayTime" BO_ 2156331008 100;
BA_ "Prio" BO_ 2150375424 4;
BA_ "GenMsgDelayTime" BO_ 2150375424 100;
BA_ "Prio" BO_ 2158149632 4;
BA_ "GenMsgDelayTime" BO_ 2158149632 100;
BA_ "Prio" BO_ 2150113280 4;
BA_ "GenMsgDelayTime" BO_ 2150113280 100;
BA_ "Prio" BO_ 2150547456 4;
BA_ "GenMsgDelayTime" BO_ 2150547456 100;
BA_ "Prio" BO_ 2149728256 4;
BA_ "GenMsgDelayTime" BO_ 2149728256 100;
BA_ "Prio" BO_ 2155945984 4;
BA_ "GenMsgDelayTime" BO_ 2155945984 100;
BA_ "Prio" BO_ 2155585536 4;
BA_ "GenMsgDelayTime" BO_ 2155585536 100;
BA_ "Prio" BO_ 2155569152 4;
BA_ "GenMsgDelayTime" BO_ 2155569152 100;
BA_ "Prio" BO_ 2150891520 4;
BA_ "GenMsgDelayTime" BO_ 2150891520 100;
BA_ "Prio" BO_ 2155536384 4;
BA_ "GenMsgDelayTime" BO_ 2155536384 100;
BA_ "Prio" BO_ 2151415808 4;
BA_ "GenMsgDelayTime" BO_ 2151415808 100;
BA_ "Prio" BO_ 2151522304 4;
BA_ "GenMsgDelayTime" BO_ 2151522304 100;
BA_ "Prio" BO_ 2154979328 4;
BA_ "GenMsgDelayTime" BO_ 2154979328 100;
BA_ "Prio" BO_ 2151505920 4;
BA_ "GenMsgDelayTime" BO_ 2151505920 100;
BA_ "GenMsgCycleTime" BO_ 2151505920 1000;
BA_ "GenMsgSendType" BO_ 2151505920 0;
BA_ "Prio" BO_ 2155552768 4;
BA_ "GenMsgDelayTime" BO_ 2155552768 100;
BA_ "Prio" BO_ 2150006784 4;
BA_ "GenMsgDelayTime" BO_ 2150006784 100;
BA_ "Prio" BO_ 2158911488 4;
BA_ "GenMsgDelayTime" BO_ 2158911488 20;
BA_ "Prio" BO_ 2158919680 4;
BA_ "GenMsgDelayTime" BO_ 2158919680 20;
BA_ "Prio" BO_ 2151825408 4;
BA_ "GenMsgDelayTime" BO_ 2151825408 100;
BA_ "Prio" BO_ 2149711872 4;
BA_ "GenMsgStartDelayTime" BO_ 2149711872 120;
BA_ "GenMsgCycleTime" BO_ 2149711872 100;
BA_ "GenMsgSendType" BO_ 2149711872 0;
BA_ "Prio" BO_ 2162982912 4;
BA_ "GenMsgStartDelayTime" BO_ 2162982912 200;
BA_ "GenMsgCycleTime" BO_ 2162982912 5000;
BA_ "GenMsgSendType" BO_ 2162982912 0;
BA_ "Prio" BO_ 2162966528 4;
BA_ "GenMsgStartDelayTime" BO_ 2162966528 190;
BA_ "GenMsgCycleTime" BO_ 2162966528 5000;
BA_ "GenMsgSendType" BO_ 2162966528 0;
BA_ "DiagRequest" BO_ 601 1;
BA_ "Prio" BO_ 2158854144 4;
BA_ "GenMsgDelayTime" BO_ 2158854144 20;
BA_ "Prio" BO_ 2149629952 4;
BA_ "GenMsgDelayTime" BO_ 2149629952 30;
BA_ "Prio" BO_ 2155028480 4;
BA_ "GenMsgDelayTime" BO_ 2155028480 100;
BA_ "Prio" BO_ 2149941248 4;
BA_ "GenMsgDelayTime" BO_ 2149941248 30;
BA_ "Prio" BO_ 2151342080 4;
BA_ "GenMsgDelayTime" BO_ 2151342080 100;
BA_ "Prio" BO_ 2151325696 4;
BA_ "GenMsgDelayTime" BO_ 2151325696 100;
BA_ "Prio" BO_ 2151350272 4;
BA_ "GenMsgDelayTime" BO_ 2151350272 100;
BA_ "Prio" BO_ 2151333888 4;
BA_ "GenMsgDelayTime" BO_ 2151333888 100;
BA_ "Prio" BO_ 2158796800 4;
BA_ "GenMsgDelayTime" BO_ 2158796800 100;
BA_ "GenSigSendType" SG_ 2149826560 TrfcSgnMmryIcePosIO 10;
BA_ "VNSigAllNodes" SG_ 2149826560 TrfcSgnMmryIcePosIO 1;
BA_ "SignalType" SG_ 2149826560 TrfcSgnMmryIcePosIO "BLN";
BA_ "SignalLongName" SG_ 2149826560 TrfcSgnMmryIcePosIO "Traffic Sign Memory Ice Possible Indication On";
BA_ "GenSigSendType" SG_ 2149826560 FwdClnAlrtOffIO11E 10;
BA_ "VNSigAllNodes" SG_ 2149826560 FwdClnAlrtOffIO11E 1;
BA_ "SignalType" SG_ 2149826560 FwdClnAlrtOffIO11E "BLN";
BA_ "SignalLongName" SG_ 2149826560 FwdClnAlrtOffIO11E "Forward Collision Alert Off Indication On";
BA_ "GenSigSendOnInit" SG_ 2149826560 FwdClnAlrtPr11E 1;
BA_ "GenSigSendType" SG_ 2149826560 FwdClnAlrtPr11E 10;
BA_ "VNSigAllNodes" SG_ 2149826560 FwdClnAlrtPr11E 1;
BA_ "SignalType" SG_ 2149826560 FwdClnAlrtPr11E "BLN";
BA_ "SignalLongName" SG_ 2149826560 FwdClnAlrtPr11E "Forward Collision Alert Present";
BA_ "GenSigSendType" SG_ 2149826560 FCAHdwyStngIO 10;
BA_ "VNSigAllNodes" SG_ 2149826560 FCAHdwyStngIO 1;
BA_ "SignalType" SG_ 2149826560 FCAHdwyStngIO "BLN";
BA_ "SignalLongName" SG_ 2149826560 FCAHdwyStngIO "Forward Collision Alert Headway Setting Indication On";
BA_ "GenSigSendType" SG_ 2149826560 FCAGpStng 10;
BA_ "VNSigAllNodes" SG_ 2149826560 FCAGpStng 1;
BA_ "SignalType" SG_ 2149826560 FCAGpStng "ENM";
BA_ "SignalLongName" SG_ 2149826560 FCAGpStng "Forward Collision Alert Gap Setting";
BA_ "GenSigSendType" SG_ 2149826560 SpdLmtVsnFsdSpdUnt 10;
BA_ "VNSigAllNodes" SG_ 2149826560 SpdLmtVsnFsdSpdUnt 1;
BA_ "SignalType" SG_ 2149826560 SpdLmtVsnFsdSpdUnt "ENM";
BA_ "SignalLongName" SG_ 2149826560 SpdLmtVsnFsdSpdUnt "Speed Limit Vision Fused Speed Unit";
BA_ "GenSigSendType" SG_ 2149826560 SpdLmtVnFsSpdNwDet 10;
BA_ "VNSigAllNodes" SG_ 2149826560 SpdLmtVnFsSpdNwDet 1;
BA_ "SignalType" SG_ 2149826560 SpdLmtVnFsSpdNwDet "BLN";
BA_ "SignalLongName" SG_ 2149826560 SpdLmtVnFsSpdNwDet "Speed Limit Vision Fused Speed New Detected";
BA_ "GenSigSendType" SG_ 2149826560 SpdLmtVsnFsdSpdM 10;
BA_ "VNSigAllNodes" SG_ 2149826560 SpdLmtVsnFsdSpdM 1;
BA_ "SignalType" SG_ 2149826560 SpdLmtVsnFsdSpdM "ENM";
BA_ "SignalLongName" SG_ 2149826560 SpdLmtVsnFsdSpdM "Speed Limit Vision Fused Speed Mask";
BA_ "GenSigSendType" SG_ 2149826560 SpdLmtVsnFsdSpd 12;
BA_ "GenSigDeltaValue" SG_ 2149826560 SpdLmtVsnFsdSpd 1;
BA_ "VNSigAllNodes" SG_ 2149826560 SpdLmtVsnFsdSpd 1;
BA_ "SignalType" SG_ 2149826560 SpdLmtVsnFsdSpd "UNM";
BA_ "SignalLongName" SG_ 2149826560 SpdLmtVsnFsdSpd "Speed Limit Vision Fused Speed";
BA_ "GenSigSendType" SG_ 2149826560 FOAI_VehAhdIndRq11E 10;
BA_ "VNSigAllNodes" SG_ 2149826560 FOAI_VehAhdIndRq11E 1;
BA_ "SignalType" SG_ 2149826560 FOAI_VehAhdIndRq11E "ENM";
BA_ "PacketOrder" SG_ 2149826560 FOAI_VehAhdIndRq11E 3;
BA_ "SignalLongName" SG_ 2149826560 FOAI_VehAhdIndRq11E "Forward Object Alert Indications : Vehicle Ahead Indication Request";
BA_ "GenSigSendType" SG_ 2149826560 FOAI_AlrtWrnIndRq11E 10;
BA_ "VNSigAllNodes" SG_ 2149826560 FOAI_AlrtWrnIndRq11E 1;
BA_ "SignalType" SG_ 2149826560 FOAI_AlrtWrnIndRq11E "ENM";
BA_ "PacketOrder" SG_ 2149826560 FOAI_AlrtWrnIndRq11E 2;
BA_ "SignalLongName" SG_ 2149826560 FOAI_AlrtWrnIndRq11E "Forward Object Alert Indications : Alert Warning Indication Request";
BA_ "GenSigSendType" SG_ 2149826560 FOAI_AlrtChmIhbRq11E 10;
BA_ "VNSigAllNodes" SG_ 2149826560 FOAI_AlrtChmIhbRq11E 1;
BA_ "SignalType" SG_ 2149826560 FOAI_AlrtChmIhbRq11E "ENM";
BA_ "PacketOrder" SG_ 2149826560 FOAI_AlrtChmIhbRq11E 1;
BA_ "SignalLongName" SG_ 2149826560 FOAI_AlrtChmIhbRq11E "Forward Object Alert Indications : Alert Warning Chime Inhibit Request";
BA_ "GenSigSendType" SG_ 2149826560 FCABrkPrflReq 10;
BA_ "VNSigAllNodes" SG_ 2149826560 FCABrkPrflReq 1;
BA_ "SignalType" SG_ 2149826560 FCABrkPrflReq "BLN";
BA_ "SignalLongName" SG_ 2149826560 FCABrkPrflReq "Forward Collision Alert Brake Prefill Request";
BA_ "GenSigSendType" SG_ 2149826560 FCACrusCtrlCnclReqd 10;
BA_ "VNSigAllNodes" SG_ 2149826560 FCACrusCtrlCnclReqd 1;
BA_ "SignalType" SG_ 2149826560 FCACrusCtrlCnclReqd "BLN";
BA_ "SignalLongName" SG_ 2149826560 FCACrusCtrlCnclReqd "Forward Collision Alert Cruise Control Cancel Requested";
BA_ "GenSigSendOnInit" SG_ 2151997440 DrvDrwDetCsCrStVal 2;
BA_ "GenSigSendType" SG_ 2151997440 DrvDrwDetCsCrStVal 10;
BA_ "VNSigAllNodes" SG_ 2151997440 DrvDrwDetCsCrStVal 1;
BA_ "SignalType" SG_ 2151997440 DrvDrwDetCsCrStVal "ENM";
BA_ "SignalLongName" SG_ 2151997440 DrvDrwDetCsCrStVal "Driver Drowsiness Detection Customization Current Setting Value";
BA_ "GenSigSendOnInit" SG_ 2151997440 DrvDrowDetCstStAvl 2;
BA_ "GenSigSendType" SG_ 2151997440 DrvDrowDetCstStAvl 10;
BA_ "VNSigAllNodes" SG_ 2151997440 DrvDrowDetCstStAvl 1;
BA_ "SignalType" SG_ 2151997440 DrvDrowDetCstStAvl "BLN";
BA_ "SignalLongName" SG_ 2151997440 DrvDrowDetCstStAvl "Driver Drowsiness Detection Customization Setting Available";
BA_ "GenSigSendType" SG_ 2151997440 DrvDrsnHptcStRqSeqN 12;
BA_ "GenSigDeltaValue" SG_ 2151997440 DrvDrsnHptcStRqSeqN 1;
BA_ "VNSigAllNodes" SG_ 2151997440 DrvDrsnHptcStRqSeqN 1;
BA_ "SignalType" SG_ 2151997440 DrvDrsnHptcStRqSeqN "UNM";
BA_ "SignalLongName" SG_ 2151997440 DrvDrsnHptcStRqSeqN "Driver Drowsiness System Haptic Seat Vibration Request Sequence Number";
BA_ "GenSigSendType" SG_ 2151997440 DrvDrowSysIndRq 10;
BA_ "VNSigAllNodes" SG_ 2151997440 DrvDrowSysIndRq 1;
BA_ "SignalType" SG_ 2151997440 DrvDrowSysIndRq "ENM";
BA_ "SignalLongName" SG_ 2151997440 DrvDrowSysIndRq "Driver Drowsiness System Indication Request";
BA_ "GenSigSendType" SG_ 2151997440 DrDrwSysHptcStVbnRq 12;
BA_ "GenSigDeltaValue" SG_ 2151997440 DrDrwSysHptcStVbnRq 1;
BA_ "VNSigAllNodes" SG_ 2151997440 DrDrwSysHptcStVbnRq 1;
BA_ "SignalType" SG_ 2151997440 DrDrwSysHptcStVbnRq "UNM";
BA_ "SignalLongName" SG_ 2151997440 DrDrwSysHptcStVbnRq "Driver Drowsiness System Haptic Seat Vibration Request";
BA_ "GenSigSendOnInit" SG_ 2156331008 EUSD_MsrmntUnit 1;
BA_ "GenSigSendType" SG_ 2156331008 EUSD_MsrmntUnit 10;
BA_ "VNSigAllNodes" SG_ 2156331008 EUSD_MsrmntUnit 1;
BA_ "SignalType" SG_ 2156331008 EUSD_MsrmntUnit "ENM";
BA_ "PacketOrder" SG_ 2156331008 EUSD_MsrmntUnit 2;
BA_ "SignalLongName" SG_ 2156331008 EUSD_MsrmntUnit "Energy Usage Score Display : Measurement Unit";
BA_ "GenSigSendOnInit" SG_ 2156331008 EUSD_MsrmntVal 1;
BA_ "GenSigSendType" SG_ 2156331008 EUSD_MsrmntVal 12;
BA_ "GenSigDeltaValue" SG_ 2156331008 EUSD_MsrmntVal 1;
BA_ "VNSigAllNodes" SG_ 2156331008 EUSD_MsrmntVal 1;
BA_ "SignalType" SG_ 2156331008 EUSD_MsrmntVal "UNM";
BA_ "PacketOrder" SG_ 2156331008 EUSD_MsrmntVal 1;
BA_ "SignalLongName" SG_ 2156331008 EUSD_MsrmntVal "Energy Usage Score Display : Measurement Value";
BA_ "GenSigSendOnInit" SG_ 2156331008 HVDpltnMdMiCnfdcRg 1;
BA_ "GenSigSendType" SG_ 2156331008 HVDpltnMdMiCnfdcRg 12;
BA_ "GenSigDeltaValue" SG_ 2156331008 HVDpltnMdMiCnfdcRg 1;
BA_ "VNSigAllNodes" SG_ 2156331008 HVDpltnMdMiCnfdcRg 1;
BA_ "SignalType" SG_ 2156331008 HVDpltnMdMiCnfdcRg "UNM";
BA_ "SignalLongName" SG_ 2156331008 HVDpltnMdMiCnfdcRg "High Voltage Depletion Mode Minimum Confidence Range";
BA_ "GenSigSendOnInit" SG_ 2156331008 HVDpltnMdMxCnfdcRg 1;
BA_ "GenSigSendType" SG_ 2156331008 HVDpltnMdMxCnfdcRg 12;
BA_ "GenSigDeltaValue" SG_ 2156331008 HVDpltnMdMxCnfdcRg 1;
BA_ "VNSigAllNodes" SG_ 2156331008 HVDpltnMdMxCnfdcRg 1;
BA_ "SignalType" SG_ 2156331008 HVDpltnMdMxCnfdcRg "UNM";
BA_ "SignalLongName" SG_ 2156331008 HVDpltnMdMxCnfdcRg "High Voltage Depletion Mode Maximum Confidence Range";
BA_ "GenSigSendType" SG_ 2156331008 LwRngLVLdShdRq 10;
BA_ "VNSigAllNodes" SG_ 2156331008 LwRngLVLdShdRq 1;
BA_ "SignalType" SG_ 2156331008 LwRngLVLdShdRq "ENM";
BA_ "SignalLongName" SG_ 2156331008 LwRngLVLdShdRq "Low Range Low Voltage Load Shedding Request";
BA_ "GenSigSendType" SG_ 2150375424 HVBChrgOvrdBtnDspReq 10;
BA_ "VNSigAllNodes" SG_ 2150375424 HVBChrgOvrdBtnDspReq 1;
BA_ "SignalType" SG_ 2150375424 HVBChrgOvrdBtnDspReq "ENM";
BA_ "SignalLongName" SG_ 2150375424 HVBChrgOvrdBtnDspReq "High Voltage Battery Charge Override Button Display Request";
BA_ "GenSigSendType" SG_ 2150375424 HVBChrgLmtBtnDspReq 10;
BA_ "VNSigAllNodes" SG_ 2150375424 HVBChrgLmtBtnDspReq 1;
BA_ "SignalType" SG_ 2150375424 HVBChrgLmtBtnDspReq "ENM";
BA_ "SignalLongName" SG_ 2150375424 HVBChrgLmtBtnDspReq "High Voltage Battery Charge Limit Button Display Request";
BA_ "GenSigSendType" SG_ 2150375424 HVBHmChrgTmDspReq 10;
BA_ "VNSigAllNodes" SG_ 2150375424 HVBHmChrgTmDspReq 1;
BA_ "SignalType" SG_ 2150375424 HVBHmChrgTmDspReq "ENM";
BA_ "SignalLongName" SG_ 2150375424 HVBHmChrgTmDspReq "High Voltage Battery Home Charge Time Display Request";
BA_ "GenSigSendType" SG_ 2150375424 HVBChrgTmDspReq 10;
BA_ "VNSigAllNodes" SG_ 2150375424 HVBChrgTmDspReq 1;
BA_ "SignalType" SG_ 2150375424 HVBChrgTmDspReq "ENM";
BA_ "SignalLongName" SG_ 2150375424 HVBChrgTmDspReq "High Voltage Battery Charge Time Display Request";
BA_ "GenSigSendType" SG_ 2150375424 LBCCsStReq 10;
BA_ "VNSigAllNodes" SG_ 2150375424 LBCCsStReq 1;
BA_ "SignalType" SG_ 2150375424 LBCCsStReq "ENM";
BA_ "SignalLongName" SG_ 2150375424 LBCCsStReq "Location Based Charging Customization Setting Request";
BA_ "GenSigSendType" SG_ 2150375424 LBCPosMdfcReq 10;
BA_ "VNSigAllNodes" SG_ 2150375424 LBCPosMdfcReq 1;
BA_ "SignalType" SG_ 2150375424 LBCPosMdfcReq "ENM";
BA_ "SignalLongName" SG_ 2150375424 LBCPosMdfcReq "Location Based Charging Position Modification Request";
BA_ "GenSigSendType" SG_ 2150375424 LBCCDRR_ClrStrdPosReq 10;
BA_ "VNSigAllNodes" SG_ 2150375424 LBCCDRR_ClrStrdPosReq 1;
BA_ "SignalType" SG_ 2150375424 LBCCDRR_ClrStrdPosReq "ENM";
BA_ "PacketOrder" SG_ 2150375424 LBCCDRR_ClrStrdPosReq 1;
BA_ "SignalLongName" SG_ 2150375424 LBCCDRR_ClrStrdPosReq "Location Based Charging Customer Data Reset Request : Clear Stored Position Request";
BA_ "GenSigSendType" SG_ 2150375424 LBCCDRR_PosNum 10;
BA_ "VNSigAllNodes" SG_ 2150375424 LBCCDRR_PosNum 1;
BA_ "SignalType" SG_ 2150375424 LBCCDRR_PosNum "ENM";
BA_ "PacketOrder" SG_ 2150375424 LBCCDRR_PosNum 2;
BA_ "SignalLongName" SG_ 2150375424 LBCCDRR_PosNum "Location Based Charging Customer Data Reset Request : Position Number";
BA_ "GenSigSendType" SG_ 2150375424 EngyCnsHistGrphRstRq 10;
BA_ "VNSigAllNodes" SG_ 2150375424 EngyCnsHistGrphRstRq 1;
BA_ "SignalType" SG_ 2150375424 EngyCnsHistGrphRstRq "BLN";
BA_ "SignalLongName" SG_ 2150375424 EngyCnsHistGrphRstRq "Energy Consumption History Graph Reset Requested";
BA_ "GenSigSendType" SG_ 2150375424 EngAstHtPlgInCstStRq 10;
BA_ "VNSigAllNodes" SG_ 2150375424 EngAstHtPlgInCstStRq 1;
BA_ "SignalType" SG_ 2150375424 EngAstHtPlgInCstStRq "ENM";
BA_ "SignalLongName" SG_ 2150375424 EngAstHtPlgInCstStRq "Engine Assisted Heating Plugged-In Customization Setting Request";
BA_ "GenSigSendType" SG_ 2150375424 EngAstHtCstStRq 10;
BA_ "VNSigAllNodes" SG_ 2150375424 EngAstHtCstStRq 1;
BA_ "SignalType" SG_ 2150375424 EngAstHtCstStRq "ENM";
BA_ "SignalLongName" SG_ 2150375424 EngAstHtCstStRq "Engine Assisted Heating Customization Setting Request";
BA_ "GenSigSendOnInit" SG_ 2150375424 MntnceMdStEngRq 2;
BA_ "GenSigSendType" SG_ 2150375424 MntnceMdStEngRq 10;
BA_ "VNSigAllNodes" SG_ 2150375424 MntnceMdStEngRq 1;
BA_ "SignalType" SG_ 2150375424 MntnceMdStEngRq "BLN";
BA_ "SignalLongName" SG_ 2150375424 MntnceMdStEngRq "Maintenance Mode Start Engine Request";
BA_ "GenSigSendType" SG_ 2150375424 USBProgInPrgrs 10;
BA_ "VNSigAllNodes" SG_ 2150375424 USBProgInPrgrs 1;
BA_ "SignalType" SG_ 2150375424 USBProgInPrgrs "BLN";
BA_ "SignalLongName" SG_ 2150375424 USBProgInPrgrs "USB Programming In Progress";
BA_ "GenSigSendType" SG_ 2150375424 DsplTrnsShftLvrLckRqd 10;
BA_ "VNSigAllNodes" SG_ 2150375424 DsplTrnsShftLvrLckRqd 1;
BA_ "SignalType" SG_ 2150375424 DsplTrnsShftLvrLckRqd "BLN";
BA_ "SignalLongName" SG_ 2150375424 DsplTrnsShftLvrLckRqd "Displays Transmission Shift Lever Lock Requested";
BA_ "GenSigSendOnInit" SG_ 2158149632 ECHGCD_XAxTkMrkInterv 1;
BA_ "GenSigSendType" SG_ 2158149632 ECHGCD_XAxTkMrkInterv 10;
BA_ "VNSigAllNodes" SG_ 2158149632 ECHGCD_XAxTkMrkInterv 1;
BA_ "SignalType" SG_ 2158149632 ECHGCD_XAxTkMrkInterv "ENM";
BA_ "PacketOrder" SG_ 2158149632 ECHGCD_XAxTkMrkInterv 3;
BA_ "SignalLongName" SG_ 2158149632 ECHGCD_XAxTkMrkInterv "Energy Consumption History Graph Configuration Data : X Axis Tick Mark Interval";
BA_ "GenSigSendOnInit" SG_ 2158149632 ECHGCD_YAxMaxVal 1;
BA_ "GenSigSendType" SG_ 2158149632 ECHGCD_YAxMaxVal 12;
BA_ "GenSigDeltaValue" SG_ 2158149632 ECHGCD_YAxMaxVal 1;
BA_ "VNSigAllNodes" SG_ 2158149632 ECHGCD_YAxMaxVal 1;
BA_ "SignalType" SG_ 2158149632 ECHGCD_YAxMaxVal "UNM";
BA_ "PacketOrder" SG_ 2158149632 ECHGCD_YAxMaxVal 2;
BA_ "SignalLongName" SG_ 2158149632 ECHGCD_YAxMaxVal "Energy Consumption History Graph Configuration Data : Y Axis Maximum Value";
BA_ "GenSigSendOnInit" SG_ 2158149632 ECHGCD_MeasUt 1;
BA_ "GenSigSendType" SG_ 2158149632 ECHGCD_MeasUt 10;
BA_ "VNSigAllNodes" SG_ 2158149632 ECHGCD_MeasUt 1;
BA_ "SignalType" SG_ 2158149632 ECHGCD_MeasUt "ENM";
BA_ "PacketOrder" SG_ 2158149632 ECHGCD_MeasUt 1;
BA_ "SignalLongName" SG_ 2158149632 ECHGCD_MeasUt "Energy Consumption History Graph Configuration Data : Measurement Unit";
BA_ "GenSigSendOnInit" SG_ 2158149632 EgyCnsHstGphInsEgyCns 1;
BA_ "GenSigSendType" SG_ 2158149632 EgyCnsHstGphInsEgyCns 12;
BA_ "GenSigDeltaValue" SG_ 2158149632 EgyCnsHstGphInsEgyCns 1;
BA_ "VNSigAllNodes" SG_ 2158149632 EgyCnsHstGphInsEgyCns 1;
BA_ "SignalType" SG_ 2158149632 EgyCnsHstGphInsEgyCns "UNM";
BA_ "SignalLongName" SG_ 2158149632 EgyCnsHstGphInsEgyCns "Energy Consumption History Graph Instantaneous Energy Consumption";
BA_ "GenSigSendOnInit" SG_ 2158149632 HVBTBSCR_SsnDyStat 1;
BA_ "GenSigSendType" SG_ 2158149632 HVBTBSCR_SsnDyStat 12;
BA_ "GenSigDeltaValue" SG_ 2158149632 HVBTBSCR_SsnDyStat 1;
BA_ "VNSigAllNodes" SG_ 2158149632 HVBTBSCR_SsnDyStat 1;
BA_ "SignalType" SG_ 2158149632 HVBTBSCR_SsnDyStat "UNM";
BA_ "PacketOrder" SG_ 2158149632 HVBTBSCR_SsnDyStat 4;
BA_ "SignalLongName" SG_ 2158149632 HVBTBSCR_SsnDyStat "High Voltage Battery Time Based Season Charging Response : Season Day Status";
BA_ "GenSigSendOnInit" SG_ 2158149632 HVBTBSCR_SsnStat 1;
BA_ "GenSigSendType" SG_ 2158149632 HVBTBSCR_SsnStat 10;
BA_ "VNSigAllNodes" SG_ 2158149632 HVBTBSCR_SsnStat 1;
BA_ "SignalType" SG_ 2158149632 HVBTBSCR_SsnStat "ENM";
BA_ "PacketOrder" SG_ 2158149632 HVBTBSCR_SsnStat 1;
BA_ "SignalLongName" SG_ 2158149632 HVBTBSCR_SsnStat "High Voltage Battery Time Based Season Charging Response : Season Status";
BA_ "GenSigSendOnInit" SG_ 2158149632 HVBTBSCR_SsnSlctStat 1;
BA_ "GenSigSendType" SG_ 2158149632 HVBTBSCR_SsnSlctStat 10;
BA_ "VNSigAllNodes" SG_ 2158149632 HVBTBSCR_SsnSlctStat 1;
BA_ "SignalType" SG_ 2158149632 HVBTBSCR_SsnSlctStat "ENM";
BA_ "PacketOrder" SG_ 2158149632 HVBTBSCR_SsnSlctStat 2;
BA_ "SignalLongName" SG_ 2158149632 HVBTBSCR_SsnSlctStat "High Voltage Battery Time Based Season Charging Response : Season Selected Status";
BA_ "GenSigSendOnInit" SG_ 2158149632 HVBTBSCR_SsnMthStat 1;
BA_ "GenSigSendType" SG_ 2158149632 HVBTBSCR_SsnMthStat 10;
BA_ "VNSigAllNodes" SG_ 2158149632 HVBTBSCR_SsnMthStat 1;
BA_ "SignalType" SG_ 2158149632 HVBTBSCR_SsnMthStat "ENM";
BA_ "PacketOrder" SG_ 2158149632 HVBTBSCR_SsnMthStat 3;
BA_ "SignalLongName" SG_ 2158149632 HVBTBSCR_SsnMthStat "High Voltage Battery Time Based Season Charging Response : Season Month Status";
BA_ "GenSigSendOnInit" SG_ 2158149632 HVBTBCRS_ChRtDStat 1;
BA_ "GenSigSendType" SG_ 2158149632 HVBTBCRS_ChRtDStat 10;
BA_ "VNSigAllNodes" SG_ 2158149632 HVBTBCRS_ChRtDStat 1;
BA_ "SignalType" SG_ 2158149632 HVBTBCRS_ChRtDStat "ENM";
BA_ "PacketOrder" SG_ 2158149632 HVBTBCRS_ChRtDStat 2;
BA_ "SignalLongName" SG_ 2158149632 HVBTBCRS_ChRtDStat "High Voltage Battery Time Based Charge Rate Response : Charge Rate Day Status";
BA_ "GenSigSendOnInit" SG_ 2158149632 HVBTBCRS_ChRtSlctStat 1;
BA_ "GenSigSendType" SG_ 2158149632 HVBTBCRS_ChRtSlctStat 10;
BA_ "VNSigAllNodes" SG_ 2158149632 HVBTBCRS_ChRtSlctStat 1;
BA_ "SignalType" SG_ 2158149632 HVBTBCRS_ChRtSlctStat "ENM";
BA_ "PacketOrder" SG_ 2158149632 HVBTBCRS_ChRtSlctStat 3;
BA_ "SignalLongName" SG_ 2158149632 HVBTBCRS_ChRtSlctStat "High Voltage Battery Time Based Charge Rate Response : Charge Rate Selected Status";
BA_ "GenSigSendOnInit" SG_ 2158149632 HVBTBCRS_ChRtEnblStat 1;
BA_ "GenSigSendType" SG_ 2158149632 HVBTBCRS_ChRtEnblStat 10;
BA_ "VNSigAllNodes" SG_ 2158149632 HVBTBCRS_ChRtEnblStat 1;
BA_ "SignalType" SG_ 2158149632 HVBTBCRS_ChRtEnblStat "ENM";
BA_ "PacketOrder" SG_ 2158149632 HVBTBCRS_ChRtEnblStat 1;
BA_ "SignalLongName" SG_ 2158149632 HVBTBCRS_ChRtEnblStat "High Voltage Battery Time Based Charge Rate Response : Charge Rate Enable Status";
BA_ "GenSigSendOnInit" SG_ 2158149632 HVBatTmBsChrgStRsp 1;
BA_ "GenSigSendType" SG_ 2158149632 HVBatTmBsChrgStRsp 10;
BA_ "VNSigAllNodes" SG_ 2158149632 HVBatTmBsChrgStRsp 1;
BA_ "SignalType" SG_ 2158149632 HVBatTmBsChrgStRsp "ENM";
BA_ "SignalLongName" SG_ 2158149632 HVBatTmBsChrgStRsp "High Voltage Battery Time Based Charging Status Response";
BA_ "GenSigSendType" SG_ 2158149632 HVBatCrgDspStat 10;
BA_ "VNSigAllNodes" SG_ 2158149632 HVBatCrgDspStat 1;
BA_ "SignalType" SG_ 2158149632 HVBatCrgDspStat "ENM";
BA_ "SignalLongName" SG_ 2158149632 HVBatCrgDspStat "High Voltage Battery Charge Display Status";
BA_ "GenSigSendType" SG_ 2150113280 HVChrgInhbRsn 10;
BA_ "VNSigAllNodes" SG_ 2150113280 HVChrgInhbRsn 1;
BA_ "SignalType" SG_ 2150113280 HVChrgInhbRsn "ENM";
BA_ "SignalLongName" SG_ 2150113280 HVChrgInhbRsn "High Voltage Charging Inhibit Reason";
BA_ "GenSigSendType" SG_ 2150113280 DrvCyclTrpDstTrvld 12;
BA_ "GenSigDeltaValue" SG_ 2150113280 DrvCyclTrpDstTrvld 1;
BA_ "VNSigAllNodes" SG_ 2150113280 DrvCyclTrpDstTrvld 1;
BA_ "SignalType" SG_ 2150113280 DrvCyclTrpDstTrvld "UNM";
BA_ "SignalLongName" SG_ 2150113280 DrvCyclTrpDstTrvld "Drive Cycle Trip Distance Traveled";
BA_ "GenSigSendType" SG_ 2150113280 DrvCyclElecEngyEcon 12;
BA_ "GenSigDeltaValue" SG_ 2150113280 DrvCyclElecEngyEcon 1;
BA_ "VNSigAllNodes" SG_ 2150113280 DrvCyclElecEngyEcon 1;
BA_ "SignalType" SG_ 2150113280 DrvCyclElecEngyEcon "UNM";
BA_ "SignalLongName" SG_ 2150113280 DrvCyclElecEngyEcon "Drive Cycle Electrical Energy Economy";
BA_ "GenSigSendOnInit" SG_ 2150113280 DrvCycElEnrgUsd 1;
BA_ "GenSigSendType" SG_ 2150113280 DrvCycElEnrgUsd 12;
BA_ "GenSigDeltaValue" SG_ 2150113280 DrvCycElEnrgUsd 1;
BA_ "VNSigAllNodes" SG_ 2150113280 DrvCycElEnrgUsd 1;
BA_ "SignalType" SG_ 2150113280 DrvCycElEnrgUsd "UNM";
BA_ "SignalLongName" SG_ 2150113280 DrvCycElEnrgUsd "Drive Cycle Electrical Energy Used";
BA_ "GenSigSendOnInit" SG_ 2150113280 EngyStgSysActCoolEnb 1;
BA_ "GenSigSendType" SG_ 2150113280 EngyStgSysActCoolEnb 10;
BA_ "VNSigAllNodes" SG_ 2150113280 EngyStgSysActCoolEnb 1;
BA_ "SignalType" SG_ 2150113280 EngyStgSysActCoolEnb "BLN";
BA_ "SignalLongName" SG_ 2150113280 EngyStgSysActCoolEnb "Energy Storage System Active Cooling Enabled";
BA_ "GenSigSendType" SG_ 2150547456 HVDpltnMdCnfdcTrndg 12;
BA_ "GenSigDeltaValue" SG_ 2150547456 HVDpltnMdCnfdcTrndg 1;
BA_ "VNSigAllNodes" SG_ 2150547456 HVDpltnMdCnfdcTrndg 1;
BA_ "SignalType" SG_ 2150547456 HVDpltnMdCnfdcTrndg "SNM";
BA_ "SignalLongName" SG_ 2150547456 HVDpltnMdCnfdcTrndg "High Voltage Depletion Mode Confidence Trending";
BA_ "GenSigSendOnInit" SG_ 2150547456 OffBrdHVCVehPwrLvl 1;
BA_ "GenSigSendType" SG_ 2150547456 OffBrdHVCVehPwrLvl 10;
BA_ "VNSigAllNodes" SG_ 2150547456 OffBrdHVCVehPwrLvl 1;
BA_ "SignalType" SG_ 2150547456 OffBrdHVCVehPwrLvl "ENM";
BA_ "SignalLongName" SG_ 2150547456 OffBrdHVCVehPwrLvl "Off Board High Voltage Charging Vehicle Power Level";
BA_ "GenSigSendOnInit" SG_ 2150547456 OffBrdHVCVehPwrDrtd 1;
BA_ "GenSigSendType" SG_ 2150547456 OffBrdHVCVehPwrDrtd 10;
BA_ "VNSigAllNodes" SG_ 2150547456 OffBrdHVCVehPwrDrtd 1;
BA_ "SignalType" SG_ 2150547456 OffBrdHVCVehPwrDrtd "BLN";
BA_ "SignalLongName" SG_ 2150547456 OffBrdHVCVehPwrDrtd "Off Board High Voltage Charging Vehicle Power Derated";
BA_ "GenSigSendOnInit" SG_ 2150547456 OffBrdHVCVehCplrLkd 1;
BA_ "GenSigSendType" SG_ 2150547456 OffBrdHVCVehCplrLkd 10;
BA_ "VNSigAllNodes" SG_ 2150547456 OffBrdHVCVehCplrLkd 1;
BA_ "SignalType" SG_ 2150547456 OffBrdHVCVehCplrLkd "BLN";
BA_ "SignalLongName" SG_ 2150547456 OffBrdHVCVehCplrLkd "Off Board High Voltage Charging Vehicle Coupler Locked";
BA_ "GenSigSendType" SG_ 2150547456 OffBrdHVBlkChrgCmp 10;
BA_ "VNSigAllNodes" SG_ 2150547456 OffBrdHVBlkChrgCmp 1;
BA_ "SignalType" SG_ 2150547456 OffBrdHVBlkChrgCmp "BLN";
BA_ "SignalLongName" SG_ 2150547456 OffBrdHVBlkChrgCmp "Off Board High Voltage Bulk Charging Complete";
BA_ "GenSigSendOnInit" SG_ 2150547456 OBHVBCCT_MinofHr 1;
BA_ "GenSigSendType" SG_ 2150547456 OBHVBCCT_MinofHr 12;
BA_ "GenSigDeltaValue" SG_ 2150547456 OBHVBCCT_MinofHr 1;
BA_ "VNSigAllNodes" SG_ 2150547456 OBHVBCCT_MinofHr 1;
BA_ "SignalType" SG_ 2150547456 OBHVBCCT_MinofHr "UNM";
BA_ "PacketOrder" SG_ 2150547456 OBHVBCCT_MinofHr 3;
BA_ "SignalLongName" SG_ 2150547456 OBHVBCCT_MinofHr "Off Board High Voltage Bulk Charging Complete Time : Minute of Hour";
BA_ "GenSigSendOnInit" SG_ 2150547456 OBHVBCCT_HrofDay 1;
BA_ "GenSigSendType" SG_ 2150547456 OBHVBCCT_HrofDay 12;
BA_ "GenSigDeltaValue" SG_ 2150547456 OBHVBCCT_HrofDay 1;
BA_ "VNSigAllNodes" SG_ 2150547456 OBHVBCCT_HrofDay 1;
BA_ "SignalType" SG_ 2150547456 OBHVBCCT_HrofDay "UNM";
BA_ "PacketOrder" SG_ 2150547456 OBHVBCCT_HrofDay 2;
BA_ "SignalLongName" SG_ 2150547456 OBHVBCCT_HrofDay "Off Board High Voltage Bulk Charging Complete Time : Hour of Day";
BA_ "GenSigSendOnInit" SG_ 2150547456 OBHVBCCT_DayofWk 1;
BA_ "GenSigSendType" SG_ 2150547456 OBHVBCCT_DayofWk 12;
BA_ "GenSigDeltaValue" SG_ 2150547456 OBHVBCCT_DayofWk 1;
BA_ "VNSigAllNodes" SG_ 2150547456 OBHVBCCT_DayofWk 1;
BA_ "SignalType" SG_ 2150547456 OBHVBCCT_DayofWk "UNM";
BA_ "PacketOrder" SG_ 2150547456 OBHVBCCT_DayofWk 1;
BA_ "SignalLongName" SG_ 2150547456 OBHVBCCT_DayofWk "Off Board High Voltage Bulk Charging Complete Time : Day of Week";
BA_ "GenSigSendType" SG_ 2150547456 ElecPrplsnMtrOvrSpdIO 10;
BA_ "VNSigAllNodes" SG_ 2150547456 ElecPrplsnMtrOvrSpdIO 1;
BA_ "SignalType" SG_ 2150547456 ElecPrplsnMtrOvrSpdIO "BLN";
BA_ "SignalLongName" SG_ 2150547456 ElecPrplsnMtrOvrSpdIO "Electric Propulsion Motor Over Speed Indication On";
BA_ "GenSigSendType" SG_ 2150547456 HVBatOutOfEnrgyInd 10;
BA_ "VNSigAllNodes" SG_ 2150547456 HVBatOutOfEnrgyInd 1;
BA_ "SignalType" SG_ 2150547456 HVBatOutOfEnrgyInd "ENM";
BA_ "SignalLongName" SG_ 2150547456 HVBatOutOfEnrgyInd "High Voltage Battery Out of Energy Indication";
BA_ "GenSigSendType" SG_ 2150547456 CntrsOpnUndrTmpIO 10;
BA_ "VNSigAllNodes" SG_ 2150547456 CntrsOpnUndrTmpIO 1;
BA_ "SignalType" SG_ 2150547456 CntrsOpnUndrTmpIO "BLN";
BA_ "SignalLongName" SG_ 2150547456 CntrsOpnUndrTmpIO "Contactors Open Under Temperature Indication On";
BA_ "GenSigSendType" SG_ 2150547456 HVBatCntctrsOpnIO 10;
BA_ "VNSigAllNodes" SG_ 2150547456 HVBatCntctrsOpnIO 1;
BA_ "SignalType" SG_ 2150547456 HVBatCntctrsOpnIO "BLN";
BA_ "SignalLongName" SG_ 2150547456 HVBatCntctrsOpnIO "High Voltage Battery Contactors Open Indication On";
BA_ "GenSigSendType" SG_ 2150547456 GrnAudQueReq 10;
BA_ "VNSigAllNodes" SG_ 2150547456 GrnAudQueReq 1;
BA_ "SignalType" SG_ 2150547456 GrnAudQueReq "BLN";
BA_ "SignalLongName" SG_ 2150547456 GrnAudQueReq "Green Audio Queue Request";
BA_ "GenSigSendType" SG_ 2150547456 SvcHybChrgSysIO 10;
BA_ "VNSigAllNodes" SG_ 2150547456 SvcHybChrgSysIO 1;
BA_ "SignalType" SG_ 2150547456 SvcHybChrgSysIO "BLN";
BA_ "SignalLongName" SG_ 2150547456 SvcHybChrgSysIO "Service Hybrid Charging System Indication On";
BA_ "GenSigSendOnInit" SG_ 2150547456 HVChrgrSysStat 1;
BA_ "GenSigSendType" SG_ 2150547456 HVChrgrSysStat 10;
BA_ "VNSigAllNodes" SG_ 2150547456 HVChrgrSysStat 1;
BA_ "SignalType" SG_ 2150547456 HVChrgrSysStat "ENM";
BA_ "SignalLongName" SG_ 2150547456 HVChrgrSysStat "High Voltage Charger System Status";
BA_ "GenSigSendOnInit" SG_ 2150547456 HVChrgrCplrStat 1;
BA_ "GenSigSendType" SG_ 2150547456 HVChrgrCplrStat 10;
BA_ "VNSigAllNodes" SG_ 2150547456 HVChrgrCplrStat 1;
BA_ "SignalType" SG_ 2150547456 HVChrgrCplrStat "ENM";
BA_ "SignalLongName" SG_ 2150547456 HVChrgrCplrStat "High Voltage Charger Coupler Status";
BA_ "GenSigSendOnInit" SG_ 2150547456 HVBatLimDTmpInd 2;
BA_ "GenSigSendType" SG_ 2150547456 HVBatLimDTmpInd 10;
BA_ "VNSigAllNodes" SG_ 2150547456 HVBatLimDTmpInd 1;
BA_ "SignalType" SG_ 2150547456 HVBatLimDTmpInd "ENM";
BA_ "SignalLongName" SG_ 2150547456 HVBatLimDTmpInd "High Voltage Battery Limitation Due to Temperature Indication";
BA_ "GenSigSendOnInit" SG_ 2150547456 VehChrgMdSt 2;
BA_ "GenSigSendType" SG_ 2150547456 VehChrgMdSt 10;
BA_ "VNSigAllNodes" SG_ 2150547456 VehChrgMdSt 1;
BA_ "SignalType" SG_ 2150547456 VehChrgMdSt "ENM";
BA_ "SignalLongName" SG_ 2150547456 VehChrgMdSt "Vehicle Charge Mode State";
BA_ "GenSigSendOnInit" SG_ 2150547456 HVBatChrgCrdConnIO 2;
BA_ "GenSigSendType" SG_ 2150547456 HVBatChrgCrdConnIO 10;
BA_ "VNSigAllNodes" SG_ 2150547456 HVBatChrgCrdConnIO 1;
BA_ "SignalType" SG_ 2150547456 HVBatChrgCrdConnIO "BLN";
BA_ "SignalLongName" SG_ 2150547456 HVBatChrgCrdConnIO "High Voltage Battery Charge Cord Connected Indication On";
BA_ "GenSigSendOnInit" SG_ 2150547456 HVDpltnMdRng 1;
BA_ "GenSigSendType" SG_ 2150547456 HVDpltnMdRng 12;
BA_ "GenSigDeltaValue" SG_ 2150547456 HVDpltnMdRng 1;
BA_ "VNSigAllNodes" SG_ 2150547456 HVDpltnMdRng 1;
BA_ "SignalType" SG_ 2150547456 HVDpltnMdRng "UNM";
BA_ "SignalLongName" SG_ 2150547456 HVDpltnMdRng "High Voltage Depletion Mode Range";
BA_ "GenSigSendType" SG_ 2150547456 ChgrSysAdblIndReq 10;
BA_ "VNSigAllNodes" SG_ 2150547456 ChgrSysAdblIndReq 1;
BA_ "SignalType" SG_ 2150547456 ChgrSysAdblIndReq "ENM";
BA_ "SignalLongName" SG_ 2150547456 ChgrSysAdblIndReq "Charger System Audible Indication Request";
BA_ "GenSigSendOnInit" SG_ 2149728256 EngAstHtPlgInCsStAvl 1;
BA_ "GenSigSendType" SG_ 2149728256 EngAstHtPlgInCsStAvl 10;
BA_ "VNSigAllNodes" SG_ 2149728256 EngAstHtPlgInCsStAvl 1;
BA_ "SignalType" SG_ 2149728256 EngAstHtPlgInCsStAvl "BLN";
BA_ "SignalLongName" SG_ 2149728256 EngAstHtPlgInCsStAvl "Engine Assisted Heating Plugged-In Customization Setting Available";
BA_ "GenSigSendOnInit" SG_ 2149728256 EngAstHtPlgInCsCrStVl 1;
BA_ "GenSigSendType" SG_ 2149728256 EngAstHtPlgInCsCrStVl 10;
BA_ "VNSigAllNodes" SG_ 2149728256 EngAstHtPlgInCsCrStVl 1;
BA_ "SignalType" SG_ 2149728256 EngAstHtPlgInCsCrStVl "ENM";
BA_ "SignalLongName" SG_ 2149728256 EngAstHtPlgInCsCrStVl "Engine Assisted Heating Plugged-In Customization Current Setting Value";
BA_ "GenSigSendOnInit" SG_ 2149728256 EngAstHtCsStAvl 1;
BA_ "GenSigSendType" SG_ 2149728256 EngAstHtCsStAvl 10;
BA_ "VNSigAllNodes" SG_ 2149728256 EngAstHtCsStAvl 1;
BA_ "SignalType" SG_ 2149728256 EngAstHtCsStAvl "BLN";
BA_ "SignalLongName" SG_ 2149728256 EngAstHtCsStAvl "Engine Assisted Heating Customization Setting Available";
BA_ "GenSigSendOnInit" SG_ 2149728256 EngAstHtCsCrStVal 1;
BA_ "GenSigSendType" SG_ 2149728256 EngAstHtCsCrStVal 10;
BA_ "VNSigAllNodes" SG_ 2149728256 EngAstHtCsCrStVal 1;
BA_ "SignalType" SG_ 2149728256 EngAstHtCsCrStVal "ENM";
BA_ "SignalLongName" SG_ 2149728256 EngAstHtCsCrStVal "Engine Assisted Heating Customization Current Setting Value";
BA_ "GenSigSendType" SG_ 2149728256 HghVltgPropState 10;
BA_ "VNSigAllNodes" SG_ 2149728256 HghVltgPropState 1;
BA_ "SignalType" SG_ 2149728256 HghVltgPropState "ENM";
BA_ "SignalLongName" SG_ 2149728256 HghVltgPropState "High Voltage Propulsion State";
BA_ "GenSigSendOnInit" SG_ 2149728256 ChrgPrtDrStat 1;
BA_ "GenSigSendType" SG_ 2149728256 ChrgPrtDrStat 10;
BA_ "VNSigAllNodes" SG_ 2149728256 ChrgPrtDrStat 1;
BA_ "SignalType" SG_ 2149728256 ChrgPrtDrStat "ENM";
BA_ "SignalLongName" SG_ 2149728256 ChrgPrtDrStat "Charge Port Door Status";
BA_ "GenSigSendOnInit" SG_ 2149728256 ChgCdTfAlCzStAvbl 1;
BA_ "GenSigSendType" SG_ 2149728256 ChgCdTfAlCzStAvbl 10;
BA_ "VNSigAllNodes" SG_ 2149728256 ChgCdTfAlCzStAvbl 1;
BA_ "SignalType" SG_ 2149728256 ChgCdTfAlCzStAvbl "BLN";
BA_ "SignalLongName" SG_ 2149728256 ChgCdTfAlCzStAvbl "Charge Cord Theft Alert Customization Setting Available";
BA_ "GenSigSendOnInit" SG_ 2149728256 ChgCdTfAlCzCrStVal 1;
BA_ "GenSigSendType" SG_ 2149728256 ChgCdTfAlCzCrStVal 10;
BA_ "VNSigAllNodes" SG_ 2149728256 ChgCdTfAlCzCrStVal 1;
BA_ "SignalType" SG_ 2149728256 ChgCdTfAlCzCrStVal "ENM";
BA_ "SignalLongName" SG_ 2149728256 ChgCdTfAlCzCrStVal "Charge Cord Theft Alert Customization Current Setting Value";
BA_ "GenSigSendOnInit" SG_ 2149728256 ChgPwLsAlCzStAvbl 1;
BA_ "GenSigSendType" SG_ 2149728256 ChgPwLsAlCzStAvbl 10;
BA_ "VNSigAllNodes" SG_ 2149728256 ChgPwLsAlCzStAvbl 1;
BA_ "SignalType" SG_ 2149728256 ChgPwLsAlCzStAvbl "BLN";
BA_ "SignalLongName" SG_ 2149728256 ChgPwLsAlCzStAvbl "Charge Power Loss Alert Customization Setting Available";
BA_ "GenSigSendOnInit" SG_ 2149728256 ChgPwLsAlCzCrStVal 1;
BA_ "GenSigSendType" SG_ 2149728256 ChgPwLsAlCzCrStVal 10;
BA_ "VNSigAllNodes" SG_ 2149728256 ChgPwLsAlCzCrStVal 1;
BA_ "SignalType" SG_ 2149728256 ChgPwLsAlCzCrStVal "ENM";
BA_ "SignalLongName" SG_ 2149728256 ChgPwLsAlCzCrStVal "Charge Power Loss Alert Customization Current Setting Value";
BA_ "GenSigSendOnInit" SG_ 2149728256 ChgSysAudInCsStAvl 1;
BA_ "GenSigSendType" SG_ 2149728256 ChgSysAudInCsStAvl 10;
BA_ "VNSigAllNodes" SG_ 2149728256 ChgSysAudInCsStAvl 1;
BA_ "SignalType" SG_ 2149728256 ChgSysAudInCsStAvl "BLN";
BA_ "SignalLongName" SG_ 2149728256 ChgSysAudInCsStAvl "Charger System Audible Indication Customization Setting Available";
BA_ "GenSigSendOnInit" SG_ 2149728256 ChgSyAudInCsCrStVa 1;
BA_ "GenSigSendType" SG_ 2149728256 ChgSyAudInCsCrStVa 10;
BA_ "VNSigAllNodes" SG_ 2149728256 ChgSyAudInCsCrStVa 1;
BA_ "SignalType" SG_ 2149728256 ChgSyAudInCsCrStVa "ENM";
BA_ "SignalLongName" SG_ 2149728256 ChgSyAudInCsCrStVa "Charger System Audible Indication Customization Current Setting Value";
BA_ "GenSigSendOnInit" SG_ 2149728256 PrtyChrgStPnt 1;
BA_ "GenSigSendType" SG_ 2149728256 PrtyChrgStPnt 12;
BA_ "GenSigDeltaValue" SG_ 2149728256 PrtyChrgStPnt 1;
BA_ "VNSigAllNodes" SG_ 2149728256 PrtyChrgStPnt 1;
BA_ "SignalType" SG_ 2149728256 PrtyChrgStPnt "UNM";
BA_ "SignalLongName" SG_ 2149728256 PrtyChrgStPnt "Priority Charging Set Point";
BA_ "GenSigSendType" SG_ 2149728256 PrtyChrgActIO 10;
BA_ "VNSigAllNodes" SG_ 2149728256 PrtyChrgActIO 1;
BA_ "SignalType" SG_ 2149728256 PrtyChrgActIO "BLN";
BA_ "SignalLongName" SG_ 2149728256 PrtyChrgActIO "Priority Charging Active Indication On";
BA_ "GenSigSendOnInit" SG_ 2149728256 PrtyChrgAct 1;
BA_ "GenSigSendType" SG_ 2149728256 PrtyChrgAct 10;
BA_ "VNSigAllNodes" SG_ 2149728256 PrtyChrgAct 1;
BA_ "SignalType" SG_ 2149728256 PrtyChrgAct "BLN";
BA_ "SignalLongName" SG_ 2149728256 PrtyChrgAct "Priority Charging Active";
BA_ "GenSigSendOnInit" SG_ 2149728256 HVChrgPwrLvl 1;
BA_ "GenSigSendType" SG_ 2149728256 HVChrgPwrLvl 10;
BA_ "VNSigAllNodes" SG_ 2149728256 HVChrgPwrLvl 1;
BA_ "SignalType" SG_ 2149728256 HVChrgPwrLvl "ENM";
BA_ "SignalLongName" SG_ 2149728256 HVChrgPwrLvl "High Voltage Charger Power Level";
BA_ "GenSigSendType" SG_ 2149728256 ChrgSysTrnsShftLckRq 10;
BA_ "VNSigAllNodes" SG_ 2149728256 ChrgSysTrnsShftLckRq 1;
BA_ "SignalType" SG_ 2149728256 ChrgSysTrnsShftLckRq "BLN";
BA_ "SignalLongName" SG_ 2149728256 ChrgSysTrnsShftLckRq "Charging System Transmission Shift Lock Requested";
BA_ "GenSigSendType" SG_ 2155945984 VehStbEnhmntCurStRq 10;
BA_ "VNSigAllNodes" SG_ 2155945984 VehStbEnhmntCurStRq 1;
BA_ "SignalType" SG_ 2155945984 VehStbEnhmntCurStRq "ENM";
BA_ "SignalLongName" SG_ 2155945984 VehStbEnhmntCurStRq "Vehicle Stability Enhancement Current State Request";
BA_ "GenSigSendType" SG_ 2155945984 VehStbCmptvMdCurStRq 10;
BA_ "VNSigAllNodes" SG_ 2155945984 VehStbCmptvMdCurStRq 1;
BA_ "SignalType" SG_ 2155945984 VehStbCmptvMdCurStRq "ENM";
BA_ "SignalLongName" SG_ 2155945984 VehStbCmptvMdCurStRq "Vehicle Stability Competitive Mode Current State Request";
BA_ "GenSigSendType" SG_ 2155945984 TCSysCurStReq 10;
BA_ "VNSigAllNodes" SG_ 2155945984 TCSysCurStReq 1;
BA_ "SignalType" SG_ 2155945984 TCSysCurStReq "ENM";
BA_ "SignalLongName" SG_ 2155945984 TCSysCurStReq "Traction Control System Current State Request";
BA_ "GenSigSendOnInit" SG_ 2155945984 JmpStrtReq 1;
BA_ "GenSigSendType" SG_ 2155945984 JmpStrtReq 10;
BA_ "VNSigAllNodes" SG_ 2155945984 JmpStrtReq 1;
BA_ "SignalType" SG_ 2155945984 JmpStrtReq "BLN";
BA_ "SignalLongName" SG_ 2155945984 JmpStrtReq "Jump Start Requested";
BA_ "GenSigSendOnInit" SG_ 2155585536 StBltTgtCSRq 1;
BA_ "GenSigSendType" SG_ 2155585536 StBltTgtCSRq 10;
BA_ "VNSigAllNodes" SG_ 2155585536 StBltTgtCSRq 1;
BA_ "SignalType" SG_ 2155585536 StBltTgtCSRq "ENM";
BA_ "SignalLongName" SG_ 2155585536 StBltTgtCSRq "Seat Belt Tightening Customize Setting Request";
BA_ "GenSigSendType" SG_ 2155569152 HLOCCstSetReq 10;
BA_ "VNSigAllNodes" SG_ 2155569152 HLOCCstSetReq 1;
BA_ "SignalType" SG_ 2155569152 HLOCCstSetReq "ENM";
BA_ "SignalLongName" SG_ 2155569152 HLOCCstSetReq "Handsfree Liftgate Open Close Customization Setting Request";
BA_ "GenSigSendType" SG_ 2155569152 SmPhRmFunCstStReq 10;
BA_ "VNSigAllNodes" SG_ 2155569152 SmPhRmFunCstStReq 1;
BA_ "SignalType" SG_ 2155569152 SmPhRmFunCstStReq "ENM";
BA_ "SignalLongName" SG_ 2155569152 SmPhRmFunCstStReq "Smart Phone Remote Function Customization Setting Request";
BA_ "GenSigSendType" SG_ 2155569152 IntDimSeldClrTypStReq 10;
BA_ "VNSigAllNodes" SG_ 2155569152 IntDimSeldClrTypStReq 1;
BA_ "SignalType" SG_ 2155569152 IntDimSeldClrTypStReq "ENM";
BA_ "SignalLongName" SG_ 2155569152 IntDimSeldClrTypStReq "Interior Dimming Selected Color Type Setting Request";
BA_ "GenSigSendType" SG_ 2155569152 IntDimSeldAnmTypStReq 10;
BA_ "VNSigAllNodes" SG_ 2155569152 IntDimSeldAnmTypStReq 1;
BA_ "SignalType" SG_ 2155569152 IntDimSeldAnmTypStReq "ENM";
BA_ "SignalLongName" SG_ 2155569152 IntDimSeldAnmTypStReq "Interior Dimming Selected Animation Type Setting Request";
BA_ "GenSigSendOnInit" SG_ 2155569152 ExtHlStrAssCsStRq 1;
BA_ "GenSigSendType" SG_ 2155569152 ExtHlStrAssCsStRq 10;
BA_ "VNSigAllNodes" SG_ 2155569152 ExtHlStrAssCsStRq 1;
BA_ "SignalType" SG_ 2155569152 ExtHlStrAssCsStRq "ENM";
BA_ "SignalLongName" SG_ 2155569152 ExtHlStrAssCsStRq "Extended Hill Start Assist Customization Setting Request";
BA_ "GenSigSendOnInit" SG_ 2155569152 ColPrSysCustReq 1;
BA_ "GenSigSendType" SG_ 2155569152 ColPrSysCustReq 10;
BA_ "VNSigAllNodes" SG_ 2155569152 ColPrSysCustReq 1;
BA_ "SignalType" SG_ 2155569152 ColPrSysCustReq "ENM";
BA_ "SignalLongName" SG_ 2155569152 ColPrSysCustReq "Collision Preparation System Customization Setting Request";
BA_ "GenSigSendType" SG_ 2150891520 DgtlMapPsgRstrctn 10;
BA_ "VNSigAllNodes" SG_ 2150891520 DgtlMapPsgRstrctn 1;
BA_ "SignalType" SG_ 2150891520 DgtlMapPsgRstrctn "ENM";
BA_ "SignalLongName" SG_ 2150891520 DgtlMapPsgRstrctn "Digital Map Passing Restriction";
BA_ "GenSigSendType" SG_ 2150891520 DgtlMapCndlSpdLmt 10;
BA_ "VNSigAllNodes" SG_ 2150891520 DgtlMapCndlSpdLmt 1;
BA_ "SignalType" SG_ 2150891520 DgtlMapCndlSpdLmt "ENM";
BA_ "SignalLongName" SG_ 2150891520 DgtlMapCndlSpdLmt "Digital Map Conditional Speed Limit";
BA_ "GenSigSendType" SG_ 2150891520 DgtlMapCndlSpdLmtTyp 10;
BA_ "VNSigAllNodes" SG_ 2150891520 DgtlMapCndlSpdLmtTyp 1;
BA_ "SignalType" SG_ 2150891520 DgtlMapCndlSpdLmtTyp "ENM";
BA_ "SignalLongName" SG_ 2150891520 DgtlMapCndlSpdLmtTyp "Digital Map Conditional Speed Limit Type";
BA_ "GenSigSendType" SG_ 2150891520 DgtlMapEffSpdLmt 10;
BA_ "VNSigAllNodes" SG_ 2150891520 DgtlMapEffSpdLmt 1;
BA_ "SignalType" SG_ 2150891520 DgtlMapEffSpdLmt "ENM";
BA_ "SignalLongName" SG_ 2150891520 DgtlMapEffSpdLmt "Digital Map Effective Speed Limit";
BA_ "GenSigSendType" SG_ 2150891520 DgtlMapEffSpdLmtTyp 10;
BA_ "VNSigAllNodes" SG_ 2150891520 DgtlMapEffSpdLmtTyp 1;
BA_ "SignalType" SG_ 2150891520 DgtlMapEffSpdLmtTyp "ENM";
BA_ "SignalLongName" SG_ 2150891520 DgtlMapEffSpdLmtTyp "Digital Map Effective Speed Limit Type";
BA_ "GenSigSendType" SG_ 2150891520 DgtlMapSpdCat 10;
BA_ "VNSigAllNodes" SG_ 2150891520 DgtlMapSpdCat 1;
BA_ "SignalType" SG_ 2150891520 DgtlMapSpdCat "ENM";
BA_ "SignalLongName" SG_ 2150891520 DgtlMapSpdCat "Digital Map Speed Category";
BA_ "GenSigSendType" SG_ 2150891520 DgtlMapVerQtr 10;
BA_ "VNSigAllNodes" SG_ 2150891520 DgtlMapVerQtr 1;
BA_ "SignalType" SG_ 2150891520 DgtlMapVerQtr "ENM";
BA_ "SignalLongName" SG_ 2150891520 DgtlMapVerQtr "Digital Map Version Quarter";
BA_ "GenSigSendType" SG_ 2150891520 DgtlMapVerYr 10;
BA_ "VNSigAllNodes" SG_ 2150891520 DgtlMapVerYr 1;
BA_ "SignalType" SG_ 2150891520 DgtlMapVerYr "ENM";
BA_ "SignalLongName" SG_ 2150891520 DgtlMapVerYr "Digital Map Version Year";
BA_ "GenSigSendType" SG_ 2150891520 DgtlMapDrvngSd 10;
BA_ "VNSigAllNodes" SG_ 2150891520 DgtlMapDrvngSd 1;
BA_ "SignalType" SG_ 2150891520 DgtlMapDrvngSd "ENM";
BA_ "SignalLongName" SG_ 2150891520 DgtlMapDrvngSd "Digital Map Driving Side";
BA_ "GenSigSendType" SG_ 2150891520 RrStRmndrCstSetReq 10;
BA_ "VNSigAllNodes" SG_ 2150891520 RrStRmndrCstSetReq 1;
BA_ "SignalType" SG_ 2150891520 RrStRmndrCstSetReq "ENM";
BA_ "SignalLongName" SG_ 2150891520 RrStRmndrCstSetReq "Rear Seat Reminder Customization Setting Request";
BA_ "GenSigSendOnInit" SG_ 2150891520 FwdClnAlrtCustStngReq 1;
BA_ "GenSigSendType" SG_ 2150891520 FwdClnAlrtCustStngReq 10;
BA_ "VNSigAllNodes" SG_ 2150891520 FwdClnAlrtCustStngReq 1;
BA_ "SignalType" SG_ 2150891520 FwdClnAlrtCustStngReq "ENM";
BA_ "SignalLongName" SG_ 2150891520 FwdClnAlrtCustStngReq "Forward Collision Alert Customization Setting Request";
BA_ "GenSigSendOnInit" SG_ 2150891520 GNCustStngReq 1;
BA_ "GenSigSendType" SG_ 2150891520 GNCustStngReq 10;
BA_ "VNSigAllNodes" SG_ 2150891520 GNCustStngReq 1;
BA_ "SignalType" SG_ 2150891520 GNCustStngReq "ENM";
BA_ "SignalLongName" SG_ 2150891520 GNCustStngReq "Go Notifier Customization Setting Request";
BA_ "GenSigSendType" SG_ 2155536384 TnDrvRIMOffUnbIO 10;
BA_ "VNSigAllNodes" SG_ 2155536384 TnDrvRIMOffUnbIO 1;
BA_ "SignalType" SG_ 2155536384 TnDrvRIMOffUnbIO "BLN";
BA_ "SignalLongName" SG_ 2155536384 TnDrvRIMOffUnbIO "Teen Driver Reverse Impact Mitigation Off Unavailable Indication On";
BA_ "GenSigSendOnInit" SG_ 2155536384 RVBUnblIO 2;
BA_ "GenSigSendType" SG_ 2155536384 RVBUnblIO 10;
BA_ "VNSigAllNodes" SG_ 2155536384 RVBUnblIO 1;
BA_ "SignalType" SG_ 2155536384 RVBUnblIO "BLN";
BA_ "SignalLongName" SG_ 2155536384 RVBUnblIO "Rear Virtual Bumper Unavailable Indication On";
BA_ "GenSigSendType" SG_ 2155536384 RVBFldIO 10;
BA_ "VNSigAllNodes" SG_ 2155536384 RVBFldIO 1;
BA_ "SignalType" SG_ 2155536384 RVBFldIO "BLN";
BA_ "SignalLongName" SG_ 2155536384 RVBFldIO "Rear Virtual Bumper Failed Indication On";
BA_ "GenSigSendType" SG_ 2155536384 RVBEnbldIO 10;
BA_ "VNSigAllNodes" SG_ 2155536384 RVBEnbldIO 1;
BA_ "SignalType" SG_ 2155536384 RVBEnbldIO "BLN";
BA_ "SignalLongName" SG_ 2155536384 RVBEnbldIO "Rear Virtual Bumper Enabled Indication On";
BA_ "GenSigSendType" SG_ 2155536384 RVBDsbldIO 10;
BA_ "VNSigAllNodes" SG_ 2155536384 RVBDsbldIO 1;
BA_ "SignalType" SG_ 2155536384 RVBDsbldIO "BLN";
BA_ "SignalLongName" SG_ 2155536384 RVBDsbldIO "Rear Virtual Bumper Disabled Indication On";
BA_ "GenSigSendType" SG_ 2155536384 RevClnMtgnBrkReqAct 10;
BA_ "VNSigAllNodes" SG_ 2155536384 RevClnMtgnBrkReqAct 1;
BA_ "SignalType" SG_ 2155536384 RevClnMtgnBrkReqAct "BLN";
BA_ "SignalLongName" SG_ 2155536384 RevClnMtgnBrkReqAct "Reverse Collision Mitigation Braking Request Active";
BA_ "GenSigSendOnInit" SG_ 2151415808 FrPedDetCsStAvl 2;
BA_ "GenSigSendType" SG_ 2151415808 FrPedDetCsStAvl 10;
BA_ "VNSigAllNodes" SG_ 2151415808 FrPedDetCsStAvl 1;
BA_ "SignalType" SG_ 2151415808 FrPedDetCsStAvl "BLN";
BA_ "SignalLongName" SG_ 2151415808 FrPedDetCsStAvl "Front Pedestrian Detection Customization Setting Available";
BA_ "GenSigSendOnInit" SG_ 2151415808 FrPedDetCsCrStVal 2;
BA_ "GenSigSendType" SG_ 2151415808 FrPedDetCsCrStVal 10;
BA_ "VNSigAllNodes" SG_ 2151415808 FrPedDetCsCrStVal 1;
BA_ "SignalType" SG_ 2151415808 FrPedDetCsCrStVal "ENM";
BA_ "SignalLongName" SG_ 2151415808 FrPedDetCsCrStVal "Front Pedestrian Detection Customization Current Setting Value";
BA_ "GenSigSendType" SG_ 2151415808 RgtLnChgThrtHptStRqSN 12;
BA_ "GenSigDeltaValue" SG_ 2151415808 RgtLnChgThrtHptStRqSN 1;
BA_ "VNSigAllNodes" SG_ 2151415808 RgtLnChgThrtHptStRqSN 1;
BA_ "SignalType" SG_ 2151415808 RgtLnChgThrtHptStRqSN "UNM";
BA_ "SignalLongName" SG_ 2151415808 RgtLnChgThrtHptStRqSN "Right Lane Change Threat Haptic Seat Request Sequence Number";
BA_ "GenSigSendType" SG_ 2151415808 RgtLnChgThrtHptStRq 12;
BA_ "GenSigDeltaValue" SG_ 2151415808 RgtLnChgThrtHptStRq 1;
BA_ "VNSigAllNodes" SG_ 2151415808 RgtLnChgThrtHptStRq 1;
BA_ "SignalType" SG_ 2151415808 RgtLnChgThrtHptStRq "UNM";
BA_ "SignalLongName" SG_ 2151415808 RgtLnChgThrtHptStRq "Right Lane Change Threat Haptic Seat Request";
BA_ "GenSigSendType" SG_ 2151415808 LftLnChgThrtHptStRqSN 12;
BA_ "GenSigDeltaValue" SG_ 2151415808 LftLnChgThrtHptStRqSN 1;
BA_ "VNSigAllNodes" SG_ 2151415808 LftLnChgThrtHptStRqSN 1;
BA_ "SignalType" SG_ 2151415808 LftLnChgThrtHptStRqSN "UNM";
BA_ "SignalLongName" SG_ 2151415808 LftLnChgThrtHptStRqSN "Left Lane Change Threat Haptic Seat Request Sequence Number";
BA_ "GenSigSendType" SG_ 2151415808 LftLnChgThrtHptStRq 12;
BA_ "GenSigDeltaValue" SG_ 2151415808 LftLnChgThrtHptStRq 1;
BA_ "VNSigAllNodes" SG_ 2151415808 LftLnChgThrtHptStRq 1;
BA_ "SignalType" SG_ 2151415808 LftLnChgThrtHptStRq "UNM";
BA_ "SignalLongName" SG_ 2151415808 LftLnChgThrtHptStRq "Left Lane Change Threat Haptic Seat Request";
BA_ "GenSigSendType" SG_ 2151415808 LDWRghtHptcStRqSN 12;
BA_ "GenSigDeltaValue" SG_ 2151415808 LDWRghtHptcStRqSN 1;
BA_ "VNSigAllNodes" SG_ 2151415808 LDWRghtHptcStRqSN 1;
BA_ "SignalType" SG_ 2151415808 LDWRghtHptcStRqSN "UNM";
BA_ "SignalLongName" SG_ 2151415808 LDWRghtHptcStRqSN "Lane Departure Warning Right Haptic Seat Request Sequence Number";
BA_ "GenSigSendType" SG_ 2151415808 LDWLftHptcStRqSN 12;
BA_ "GenSigDeltaValue" SG_ 2151415808 LDWLftHptcStRqSN 1;
BA_ "VNSigAllNodes" SG_ 2151415808 LDWLftHptcStRqSN 1;
BA_ "SignalType" SG_ 2151415808 LDWLftHptcStRqSN "UNM";
BA_ "SignalLongName" SG_ 2151415808 LDWLftHptcStRqSN "Lane Departure Warning Left Haptic Seat Request Sequence Number";
BA_ "GenSigSendType" SG_ 2151415808 LDWRghtHptcStRq 12;
BA_ "GenSigDeltaValue" SG_ 2151415808 LDWRghtHptcStRq 1;
BA_ "VNSigAllNodes" SG_ 2151415808 LDWRghtHptcStRq 1;
BA_ "SignalType" SG_ 2151415808 LDWRghtHptcStRq "UNM";
BA_ "SignalLongName" SG_ 2151415808 LDWRghtHptcStRq "Lane Departure Warning Right Haptic Seat Request";
BA_ "GenSigSendType" SG_ 2151415808 LDWLftHptcStRq 12;
BA_ "GenSigDeltaValue" SG_ 2151415808 LDWLftHptcStRq 1;
BA_ "VNSigAllNodes" SG_ 2151415808 LDWLftHptcStRq 1;
BA_ "SignalType" SG_ 2151415808 LDWLftHptcStRq "UNM";
BA_ "SignalLongName" SG_ 2151415808 LDWLftHptcStRq "Lane Departure Warning Left Haptic Seat Request";
BA_ "GenSigSendType" SG_ 2151522304 ElEngyEconAvgRstRq 10;
BA_ "VNSigAllNodes" SG_ 2151522304 ElEngyEconAvgRstRq 1;
BA_ "SignalType" SG_ 2151522304 ElEngyEconAvgRstRq "BLN";
BA_ "SignalLongName" SG_ 2151522304 ElEngyEconAvgRstRq "Electrical Energy Economy Average Reset Requested";
BA_ "GenSigSendOnInit" SG_ 2151522304 BrkPdLfSysDrvrRq 1;
BA_ "GenSigSendType" SG_ 2151522304 BrkPdLfSysDrvrRq 10;
BA_ "VNSigAllNodes" SG_ 2151522304 BrkPdLfSysDrvrRq 1;
BA_ "SignalType" SG_ 2151522304 BrkPdLfSysDrvrRq "ENM";
BA_ "SignalLongName" SG_ 2151522304 BrkPdLfSysDrvrRq "Brake Pad Life System Driver Request";
BA_ "GenSigSendType" SG_ 2151522304 LnchCtrlRelLnLockReqd 10;
BA_ "VNSigAllNodes" SG_ 2151522304 LnchCtrlRelLnLockReqd 1;
BA_ "SignalType" SG_ 2151522304 LnchCtrlRelLnLockReqd "BLN";
BA_ "SignalLongName" SG_ 2151522304 LnchCtrlRelLnLockReqd "Launch Control Release Line Lock Requested";
BA_ "GenSigSendType" SG_ 2151522304 TCSTmpDsblReqConf 10;
BA_ "VNSigAllNodes" SG_ 2151522304 TCSTmpDsblReqConf 1;
BA_ "SignalType" SG_ 2151522304 TCSTmpDsblReqConf "ENM";
BA_ "SignalLongName" SG_ 2151522304 TCSTmpDsblReqConf "Traction Control System Temporary Disable Request Confirmation";
BA_ "GenSigSendOnInit" SG_ 2151522304 FuelFltLfRstRqd 1;
BA_ "GenSigSendType" SG_ 2151522304 FuelFltLfRstRqd 10;
BA_ "VNSigAllNodes" SG_ 2151522304 FuelFltLfRstRqd 1;
BA_ "SignalType" SG_ 2151522304 FuelFltLfRstRqd "BLN";
BA_ "SignalLongName" SG_ 2151522304 FuelFltLfRstRqd "Fuel Filter Life Reset Requested";
BA_ "GenSigSendType" SG_ 2154979328 FrntStVoltBstModReq 10;
BA_ "VNSigAllNodes" SG_ 2154979328 FrntStVoltBstModReq 1;
BA_ "SignalType" SG_ 2154979328 FrntStVoltBstModReq "BLN";
BA_ "SignalLongName" SG_ 2154979328 FrntStVoltBstModReq "Front Seat Voltage Boost Mode Requested";
BA_ "VNSigAllNodes" SG_ 2151505920 Trp2OdomtrV 1;
BA_ "SignalType" SG_ 2151505920 Trp2OdomtrV "ENM";
BA_ "SignalLongName" SG_ 2151505920 Trp2OdomtrV "Trip 2 Odometer Validity";
BA_ "GenSigDeltaValue" SG_ 2151505920 Trp2Odomtr 1;
BA_ "VNSigAllNodes" SG_ 2151505920 Trp2Odomtr 1;
BA_ "SignalType" SG_ 2151505920 Trp2Odomtr "UNM";
BA_ "SignalLongName" SG_ 2151505920 Trp2Odomtr "Trip 2 Odometer";
BA_ "VNSigAllNodes" SG_ 2151505920 Trp1OdomtrV 1;
BA_ "SignalType" SG_ 2151505920 Trp1OdomtrV "ENM";
BA_ "SignalLongName" SG_ 2151505920 Trp1OdomtrV "Trip 1 Odometer Validity";
BA_ "GenSigDeltaValue" SG_ 2151505920 Trp1Odomtr 1;
BA_ "VNSigAllNodes" SG_ 2151505920 Trp1Odomtr 1;
BA_ "SignalType" SG_ 2151505920 Trp1Odomtr "UNM";
BA_ "SignalLongName" SG_ 2151505920 Trp1Odomtr "Trip 1 Odometer";
BA_ "GenSigSendType" SG_ 2151505920 SpdCurvAdvSysEnbld 10;
BA_ "VNSigAllNodes" SG_ 2151505920 SpdCurvAdvSysEnbld 1;
BA_ "SignalType" SG_ 2151505920 SpdCurvAdvSysEnbld "BLN";
BA_ "SignalLongName" SG_ 2151505920 SpdCurvAdvSysEnbld "Speed and Curve Advisory System Enabled";
BA_ "GenSigSendType" SG_ 2151505920 PTExPrtclFltManRgnRqd 10;
BA_ "VNSigAllNodes" SG_ 2151505920 PTExPrtclFltManRgnRqd 1;
BA_ "SignalType" SG_ 2151505920 PTExPrtclFltManRgnRqd "BLN";
BA_ "SignalLongName" SG_ 2151505920 PTExPrtclFltManRgnRqd "Powertrain Exhaust Particle Filter Manual Regeneration Requested";
BA_ "GenSigSendType" SG_ 2151505920 AutoMdSpdLmtCnfrmd 10;
BA_ "VNSigAllNodes" SG_ 2151505920 AutoMdSpdLmtCnfrmd 1;
BA_ "SignalType" SG_ 2151505920 AutoMdSpdLmtCnfrmd "BLN";
BA_ "SignalLongName" SG_ 2151505920 AutoMdSpdLmtCnfrmd "Auto Mode Speed Limit Confirmed";
BA_ "GenSigSendType" SG_ 2151505920 ACCSettingType 10;
BA_ "VNSigAllNodes" SG_ 2151505920 ACCSettingType 1;
BA_ "SignalType" SG_ 2151505920 ACCSettingType "ENM";
BA_ "SignalLongName" SG_ 2151505920 ACCSettingType "Adaptive Cruise Control Setting Type";
BA_ "GenSigSendOnInit" SG_ 2151505920 TrlrBrkDsplyAct 1;
BA_ "GenSigSendType" SG_ 2151505920 TrlrBrkDsplyAct 10;
BA_ "VNSigAllNodes" SG_ 2151505920 TrlrBrkDsplyAct 1;
BA_ "SignalType" SG_ 2151505920 TrlrBrkDsplyAct "BLN";
BA_ "SignalLongName" SG_ 2151505920 TrlrBrkDsplyAct "Trailer Brake Display Active";
BA_ "GenSigSendType" SG_ 2155552768 PsvEntCmftWndRq 10;
BA_ "VNSigAllNodes" SG_ 2155552768 PsvEntCmftWndRq 1;
BA_ "SignalType" SG_ 2155552768 PsvEntCmftWndRq "ENM";
BA_ "SignalLongName" SG_ 2155552768 PsvEntCmftWndRq "Passive Entry Comfort Window Request";
BA_ "GenSigSendOnInit" SG_ 2150006784 SysPwrMdPshbtnActV 1;
BA_ "GenSigSendType" SG_ 2150006784 SysPwrMdPshbtnActV 10;
BA_ "VNSigAllNodes" SG_ 2150006784 SysPwrMdPshbtnActV 1;
BA_ "SignalType" SG_ 2150006784 SysPwrMdPshbtnActV "ENM";
BA_ "SignalLongName" SG_ 2150006784 SysPwrMdPshbtnActV "System Power Mode Pushbutton Active Validity";
BA_ "GenSigSendOnInit" SG_ 2150006784 SysPwrMdPshbtnAct 1;
BA_ "GenSigSendType" SG_ 2150006784 SysPwrMdPshbtnAct 10;
BA_ "VNSigAllNodes" SG_ 2150006784 SysPwrMdPshbtnAct 1;
BA_ "SignalType" SG_ 2150006784 SysPwrMdPshbtnAct "BLN";
BA_ "SignalLongName" SG_ 2150006784 SysPwrMdPshbtnAct "System Power Mode Pushbutton Active";
BA_ "GenSigSendType" SG_ 2150006784 PEPSRunCrnkRlyDctd 10;
BA_ "VNSigAllNodes" SG_ 2150006784 PEPSRunCrnkRlyDctd 1;
BA_ "SignalType" SG_ 2150006784 PEPSRunCrnkRlyDctd "BLN";
BA_ "SignalLongName" SG_ 2150006784 PEPSRunCrnkRlyDctd "PEPS Run Crank Relay Deactivated";
BA_ "GenSigSendType" SG_ 2158911488 ODDMC_ReqType 10;
BA_ "VNSigAllNodes" SG_ 2158911488 ODDMC_ReqType 1;
BA_ "SignalType" SG_ 2158911488 ODDMC_ReqType "ENM";
BA_ "PacketOrder" SG_ 2158911488 ODDMC_ReqType 1;
BA_ "SignalLongName" SG_ 2158911488 ODDMC_ReqType "Open Display Interface Dynamic Data Multi Request CenterStack : Request Type";
BA_ "GenSigSendType" SG_ 2158911488 ODDMC_DispMID 10;
BA_ "VNSigAllNodes" SG_ 2158911488 ODDMC_DispMID 1;
BA_ "SignalType" SG_ 2158911488 ODDMC_DispMID "ENM";
BA_ "PacketOrder" SG_ 2158911488 ODDMC_DispMID 7;
BA_ "SignalLongName" SG_ 2158911488 ODDMC_DispMID "Open Display Interface Dynamic Data Multi Request CenterStack : Display Mask Id";
BA_ "GenSigSendType" SG_ 2158911488 ODDMC_DataID2Vld 10;
BA_ "VNSigAllNodes" SG_ 2158911488 ODDMC_DataID2Vld 1;
BA_ "SignalType" SG_ 2158911488 ODDMC_DataID2Vld "BLN";
BA_ "PacketOrder" SG_ 2158911488 ODDMC_DataID2Vld 5;
BA_ "SignalLongName" SG_ 2158911488 ODDMC_DataID2Vld "Open Display Interface Dynamic Data Multi Request CenterStack : Data ID Two Valid";
BA_ "GenSigSendType" SG_ 2158911488 ODDMC_DataID2 12;
BA_ "GenSigDeltaValue" SG_ 2158911488 ODDMC_DataID2 1;
BA_ "VNSigAllNodes" SG_ 2158911488 ODDMC_DataID2 1;
BA_ "SignalType" SG_ 2158911488 ODDMC_DataID2 "UNM";
BA_ "PacketOrder" SG_ 2158911488 ODDMC_DataID2 9;
BA_ "SignalLongName" SG_ 2158911488 ODDMC_DataID2 "Open Display Interface Dynamic Data Multi Request CenterStack : Data ID Two";
BA_ "GenSigSendType" SG_ 2158911488 ODDMC_DataID3Vld 10;
BA_ "VNSigAllNodes" SG_ 2158911488 ODDMC_DataID3Vld 1;
BA_ "SignalType" SG_ 2158911488 ODDMC_DataID3Vld "BLN";
BA_ "PacketOrder" SG_ 2158911488 ODDMC_DataID3Vld 4;
BA_ "SignalLongName" SG_ 2158911488 ODDMC_DataID3Vld "Open Display Interface Dynamic Data Multi Request CenterStack : Data ID Three Valid";
BA_ "GenSigSendType" SG_ 2158911488 ODDMC_DataID3 12;
BA_ "GenSigDeltaValue" SG_ 2158911488 ODDMC_DataID3 1;
BA_ "VNSigAllNodes" SG_ 2158911488 ODDMC_DataID3 1;
BA_ "SignalType" SG_ 2158911488 ODDMC_DataID3 "UNM";
BA_ "PacketOrder" SG_ 2158911488 ODDMC_DataID3 10;
BA_ "SignalLongName" SG_ 2158911488 ODDMC_DataID3 "Open Display Interface Dynamic Data Multi Request CenterStack : Data ID Three";
BA_ "GenSigSendType" SG_ 2158911488 ODDMC_DataID1 12;
BA_ "GenSigDeltaValue" SG_ 2158911488 ODDMC_DataID1 1;
BA_ "VNSigAllNodes" SG_ 2158911488 ODDMC_DataID1 1;
BA_ "SignalType" SG_ 2158911488 ODDMC_DataID1 "UNM";
BA_ "PacketOrder" SG_ 2158911488 ODDMC_DataID1 8;
BA_ "SignalLongName" SG_ 2158911488 ODDMC_DataID1 "Open Display Interface Dynamic Data Multi Request CenterStack : Data ID One";
BA_ "GenSigSendType" SG_ 2158911488 ODDMC_DataID4Vld 10;
BA_ "VNSigAllNodes" SG_ 2158911488 ODDMC_DataID4Vld 1;
BA_ "SignalType" SG_ 2158911488 ODDMC_DataID4Vld "BLN";
BA_ "PacketOrder" SG_ 2158911488 ODDMC_DataID4Vld 3;
BA_ "SignalLongName" SG_ 2158911488 ODDMC_DataID4Vld "Open Display Interface Dynamic Data Multi Request CenterStack : Data ID Four Valid";
BA_ "GenSigSendType" SG_ 2158911488 ODDMC_DataID4 12;
BA_ "GenSigDeltaValue" SG_ 2158911488 ODDMC_DataID4 1;
BA_ "VNSigAllNodes" SG_ 2158911488 ODDMC_DataID4 1;
BA_ "SignalType" SG_ 2158911488 ODDMC_DataID4 "UNM";
BA_ "PacketOrder" SG_ 2158911488 ODDMC_DataID4 11;
BA_ "SignalLongName" SG_ 2158911488 ODDMC_DataID4 "Open Display Interface Dynamic Data Multi Request CenterStack : Data ID Four";
BA_ "GenSigSendType" SG_ 2158911488 ODDMC_DataID5Vld 10;
BA_ "VNSigAllNodes" SG_ 2158911488 ODDMC_DataID5Vld 1;
BA_ "SignalType" SG_ 2158911488 ODDMC_DataID5Vld "BLN";
BA_ "PacketOrder" SG_ 2158911488 ODDMC_DataID5Vld 2;
BA_ "SignalLongName" SG_ 2158911488 ODDMC_DataID5Vld "Open Display Interface Dynamic Data Multi Request CenterStack : Data ID Five Valid";
BA_ "GenSigSendType" SG_ 2158911488 ODDMC_DataID5 12;
BA_ "GenSigDeltaValue" SG_ 2158911488 ODDMC_DataID5 1;
BA_ "VNSigAllNodes" SG_ 2158911488 ODDMC_DataID5 1;
BA_ "SignalType" SG_ 2158911488 ODDMC_DataID5 "UNM";
BA_ "PacketOrder" SG_ 2158911488 ODDMC_DataID5 12;
BA_ "SignalLongName" SG_ 2158911488 ODDMC_DataID5 "Open Display Interface Dynamic Data Multi Request CenterStack : Data ID Five";
BA_ "GenSigSendType" SG_ 2158911488 ODDMC_FUCID 12;
BA_ "GenSigDeltaValue" SG_ 2158911488 ODDMC_FUCID 1;
BA_ "VNSigAllNodes" SG_ 2158911488 ODDMC_FUCID 1;
BA_ "SignalType" SG_ 2158911488 ODDMC_FUCID "UNM";
BA_ "PacketOrder" SG_ 2158911488 ODDMC_FUCID 6;
BA_ "SignalLongName" SG_ 2158911488 ODDMC_FUCID "Open Display Interface Dynamic Data Multi Request Center Stack : Functional Unit Class ID";
BA_ "GenSigSendType" SG_ 2158919680 ODDMI_ReqType 10;
BA_ "VNSigAllNodes" SG_ 2158919680 ODDMI_ReqType 1;
BA_ "SignalType" SG_ 2158919680 ODDMI_ReqType "ENM";
BA_ "PacketOrder" SG_ 2158919680 ODDMI_ReqType 1;
BA_ "SignalLongName" SG_ 2158919680 ODDMI_ReqType "Open Display Interface Dynamic Data Multi Request IPC : Request Type";
BA_ "GenSigSendType" SG_ 2158919680 ODDMI_FUCID 12;
BA_ "GenSigDeltaValue" SG_ 2158919680 ODDMI_FUCID 1;
BA_ "VNSigAllNodes" SG_ 2158919680 ODDMI_FUCID 1;
BA_ "SignalType" SG_ 2158919680 ODDMI_FUCID "UNM";
BA_ "PacketOrder" SG_ 2158919680 ODDMI_FUCID 6;
BA_ "SignalLongName" SG_ 2158919680 ODDMI_FUCID "Open Display Interface Dynamic Data Multi Request IPC : Functional Unit Class ID";
BA_ "GenSigSendType" SG_ 2158919680 ODDMI_DispMID 10;
BA_ "VNSigAllNodes" SG_ 2158919680 ODDMI_DispMID 1;
BA_ "SignalType" SG_ 2158919680 ODDMI_DispMID "ENM";
BA_ "PacketOrder" SG_ 2158919680 ODDMI_DispMID 7;
BA_ "SignalLongName" SG_ 2158919680 ODDMI_DispMID "Open Display Interface Dynamic Data Multi Request IPC : Display Mask Id";
BA_ "GenSigSendType" SG_ 2158919680 ODDMI_DataID2Vld 10;
BA_ "VNSigAllNodes" SG_ 2158919680 ODDMI_DataID2Vld 1;
BA_ "SignalType" SG_ 2158919680 ODDMI_DataID2Vld "BLN";
BA_ "PacketOrder" SG_ 2158919680 ODDMI_DataID2Vld 5;
BA_ "SignalLongName" SG_ 2158919680 ODDMI_DataID2Vld "Open Display Interface Dynamic Data Multi Request IPC : Data ID Two Valid";
BA_ "GenSigSendType" SG_ 2158919680 ODDMI_DataID2 12;
BA_ "GenSigDeltaValue" SG_ 2158919680 ODDMI_DataID2 1;
BA_ "VNSigAllNodes" SG_ 2158919680 ODDMI_DataID2 1;
BA_ "SignalType" SG_ 2158919680 ODDMI_DataID2 "UNM";
BA_ "PacketOrder" SG_ 2158919680 ODDMI_DataID2 9;
BA_ "SignalLongName" SG_ 2158919680 ODDMI_DataID2 "Open Display Interface Dynamic Data Multi Request IPC : Data ID Two";
BA_ "GenSigSendType" SG_ 2158919680 ODDMI_DataID3Vld 10;
BA_ "VNSigAllNodes" SG_ 2158919680 ODDMI_DataID3Vld 1;
BA_ "SignalType" SG_ 2158919680 ODDMI_DataID3Vld "BLN";
BA_ "PacketOrder" SG_ 2158919680 ODDMI_DataID3Vld 4;
BA_ "SignalLongName" SG_ 2158919680 ODDMI_DataID3Vld "Open Display Interface Dynamic Data Multi Request IPC : Data ID Three Valid";
BA_ "GenSigSendType" SG_ 2158919680 ODDMI_DataID3 12;
BA_ "GenSigDeltaValue" SG_ 2158919680 ODDMI_DataID3 1;
BA_ "VNSigAllNodes" SG_ 2158919680 ODDMI_DataID3 1;
BA_ "SignalType" SG_ 2158919680 ODDMI_DataID3 "UNM";
BA_ "PacketOrder" SG_ 2158919680 ODDMI_DataID3 10;
BA_ "SignalLongName" SG_ 2158919680 ODDMI_DataID3 "Open Display Interface Dynamic Data Multi Request IPC : Data ID Three";
BA_ "GenSigSendType" SG_ 2158919680 ODDMI_DataID1 12;
BA_ "GenSigDeltaValue" SG_ 2158919680 ODDMI_DataID1 1;
BA_ "VNSigAllNodes" SG_ 2158919680 ODDMI_DataID1 1;
BA_ "SignalType" SG_ 2158919680 ODDMI_DataID1 "UNM";
BA_ "PacketOrder" SG_ 2158919680 ODDMI_DataID1 8;
BA_ "SignalLongName" SG_ 2158919680 ODDMI_DataID1 "Open Display Interface Dynamic Data Multi Request IPC : Data ID One";
BA_ "GenSigSendType" SG_ 2158919680 ODDMI_DataID4Vld 10;
BA_ "VNSigAllNodes" SG_ 2158919680 ODDMI_DataID4Vld 1;
BA_ "SignalType" SG_ 2158919680 ODDMI_DataID4Vld "BLN";
BA_ "PacketOrder" SG_ 2158919680 ODDMI_DataID4Vld 3;
BA_ "SignalLongName" SG_ 2158919680 ODDMI_DataID4Vld "Open Display Interface Dynamic Data Multi Request IPC : Data ID Four Valid";
BA_ "GenSigSendType" SG_ 2158919680 ODDMI_DataID4 12;
BA_ "GenSigDeltaValue" SG_ 2158919680 ODDMI_DataID4 1;
BA_ "VNSigAllNodes" SG_ 2158919680 ODDMI_DataID4 1;
BA_ "SignalType" SG_ 2158919680 ODDMI_DataID4 "UNM";
BA_ "PacketOrder" SG_ 2158919680 ODDMI_DataID4 11;
BA_ "SignalLongName" SG_ 2158919680 ODDMI_DataID4 "Open Display Interface Dynamic Data Multi Request IPC : Data ID Four";
BA_ "GenSigSendType" SG_ 2158919680 ODDMI_DataID5Vld 10;
BA_ "VNSigAllNodes" SG_ 2158919680 ODDMI_DataID5Vld 1;
BA_ "SignalType" SG_ 2158919680 ODDMI_DataID5Vld "BLN";
BA_ "PacketOrder" SG_ 2158919680 ODDMI_DataID5Vld 2;
BA_ "SignalLongName" SG_ 2158919680 ODDMI_DataID5Vld "Open Display Interface Dynamic Data Multi Request IPC : Data ID Five Valid";
BA_ "GenSigSendType" SG_ 2158919680 ODDMI_DataID5 12;
BA_ "GenSigDeltaValue" SG_ 2158919680 ODDMI_DataID5 1;
BA_ "VNSigAllNodes" SG_ 2158919680 ODDMI_DataID5 1;
BA_ "SignalType" SG_ 2158919680 ODDMI_DataID5 "UNM";
BA_ "PacketOrder" SG_ 2158919680 ODDMI_DataID5 12;
BA_ "SignalLongName" SG_ 2158919680 ODDMI_DataID5 "Open Display Interface Dynamic Data Multi Request IPC : Data ID Five";
BA_ "GenSigSendType" SG_ 2151825408 OtsAirTmpV 10;
BA_ "VNSigAllNodes" SG_ 2151825408 OtsAirTmpV 1;
BA_ "SignalType" SG_ 2151825408 OtsAirTmpV "ENM";
BA_ "SignalLongName" SG_ 2151825408 OtsAirTmpV "Outside Air Temperature Validity";
BA_ "GenSigSendOnInit" SG_ 2151825408 OtsAirTmp 1;
BA_ "GenSigSendType" SG_ 2151825408 OtsAirTmp 12;
BA_ "GenSigDeltaValue" SG_ 2151825408 OtsAirTmp 1;
BA_ "VNSigAllNodes" SG_ 2151825408 OtsAirTmp 1;
BA_ "SignalType" SG_ 2151825408 OtsAirTmp "UNM";
BA_ "SignalLongName" SG_ 2151825408 OtsAirTmp "Outside Air Temperature";
BA_ "GenSigSendType" SG_ 2151825408 OtsAirTmpCrValV 10;
BA_ "VNSigAllNodes" SG_ 2151825408 OtsAirTmpCrValV 1;
BA_ "SignalType" SG_ 2151825408 OtsAirTmpCrValV "ENM";
BA_ "SignalLongName" SG_ 2151825408 OtsAirTmpCrValV "Outside Air Temperature Corrected Value Validity";
BA_ "GenSigSendOnInit" SG_ 2151825408 OtsAirTmpCrVal 1;
BA_ "GenSigSendType" SG_ 2151825408 OtsAirTmpCrVal 12;
BA_ "GenSigDeltaValue" SG_ 2151825408 OtsAirTmpCrVal 1;
BA_ "VNSigAllNodes" SG_ 2151825408 OtsAirTmpCrVal 1;
BA_ "SignalType" SG_ 2151825408 OtsAirTmpCrVal "UNM";
BA_ "SignalLongName" SG_ 2151825408 OtsAirTmpCrVal "Outside Air Temperature Corrected Value";
BA_ "GenSigSendType" SG_ 2151825408 OtsAirTmpCrValMsk 10;
BA_ "VNSigAllNodes" SG_ 2151825408 OtsAirTmpCrValMsk 1;
BA_ "SignalType" SG_ 2151825408 OtsAirTmpCrValMsk "ENM";
BA_ "SignalLongName" SG_ 2151825408 OtsAirTmpCrValMsk "Outside Air Temperature Corrected Value Mask";
BA_ "VNSigAllNodes" SG_ 2149711872 SetSpdLmtRchd 1;
BA_ "SignalType" SG_ 2149711872 SetSpdLmtRchd "ENM";
BA_ "SignalLongName" SG_ 2149711872 SetSpdLmtRchd "Set Speed Limit Reached";
BA_ "VNSigAllNodes" SG_ 2149711872 FOAI_VehAhdIndRq 1;
BA_ "SignalType" SG_ 2149711872 FOAI_VehAhdIndRq "ENM";
BA_ "PacketOrder" SG_ 2149711872 FOAI_VehAhdIndRq 2;
BA_ "SignalLongName" SG_ 2149711872 FOAI_VehAhdIndRq "Forward Object Alert Indications : Vehicle Ahead Indication Request";
BA_ "VNSigAllNodes" SG_ 2149711872 FOAI_AlrtWrnIndRq 1;
BA_ "SignalType" SG_ 2149711872 FOAI_AlrtWrnIndRq "ENM";
BA_ "PacketOrder" SG_ 2149711872 FOAI_AlrtWrnIndRq 3;
BA_ "SignalLongName" SG_ 2149711872 FOAI_AlrtWrnIndRq "Forward Object Alert Indications : Alert Warning Indication Request";
BA_ "VNSigAllNodes" SG_ 2149711872 FOAI_AlrtChmIhbRq 1;
BA_ "SignalType" SG_ 2149711872 FOAI_AlrtChmIhbRq "ENM";
BA_ "PacketOrder" SG_ 2149711872 FOAI_AlrtChmIhbRq 1;
BA_ "SignalLongName" SG_ 2149711872 FOAI_AlrtChmIhbRq "Forward Object Alert Indications : Alert Warning Chime Inhibit Request";
BA_ "VNSigAllNodes" SG_ 2149711872 FwdClnAlrtOffIO 1;
BA_ "SignalType" SG_ 2149711872 FwdClnAlrtOffIO "BLN";
BA_ "SignalLongName" SG_ 2149711872 FwdClnAlrtOffIO "Forward Collision Alert Off Indication On";
BA_ "VNSigAllNodes" SG_ 2149711872 FwdClnAlrtPr 1;
BA_ "SignalType" SG_ 2149711872 FwdClnAlrtPr "BLN";
BA_ "SignalLongName" SG_ 2149711872 FwdClnAlrtPr "Forward Collision Alert Present";
BA_ "VNSigAllNodes" SG_ 2149711872 ACCHdwyStg 1;
BA_ "SignalType" SG_ 2149711872 ACCHdwyStg "ENM";
BA_ "SignalLongName" SG_ 2149711872 ACCHdwyStg "Adaptive Cruise Control Headway Setting";
BA_ "VNSigAllNodes" SG_ 2149711872 ACCDrvrSeltdSpd 1;
BA_ "SignalType" SG_ 2149711872 ACCDrvrSeltdSpd "UNM";
BA_ "SignalLongName" SG_ 2149711872 ACCDrvrSeltdSpd "Adaptive Cruise Control Driver Selected Speed";
BA_ "VNSigAllNodes" SG_ 2149711872 AdapCrsCntVDA 1;
BA_ "SignalType" SG_ 2149711872 AdapCrsCntVDA "ENM";
BA_ "SignalLongName" SG_ 2149711872 AdapCrsCntVDA "Adaptive Cruise Control Virtual Device Availability";
BA_ "GenSigStartValue" SG_ 2149711872 AdapCrsCntVDA 1;
BA_ "VNSigAllNodes" SG_ 2149711872 SpdLmtrSpdWrngEnbld 1;
BA_ "SignalType" SG_ 2149711872 SpdLmtrSpdWrngEnbld "BLN";
BA_ "SignalLongName" SG_ 2149711872 SpdLmtrSpdWrngEnbld "Speed Limiter/Speed Warning Enabled";
BA_ "VNSigAllNodes" SG_ 2149711872 CrsCntlDrSelSpdAct 1;
BA_ "SignalType" SG_ 2149711872 CrsCntlDrSelSpdAct "BLN";
BA_ "SignalLongName" SG_ 2149711872 CrsCntlDrSelSpdAct "Cruise Control Driver Selected Speed Active";
BA_ "VNSigAllNodes" SG_ 2149711872 SpdLmtrSpdWrngAct 1;
BA_ "SignalType" SG_ 2149711872 SpdLmtrSpdWrngAct "BLN";
BA_ "SignalLongName" SG_ 2149711872 SpdLmtrSpdWrngAct "Speed Limiter/Speed Warning Active";
BA_ "VNSigAllNodes" SG_ 2149711872 CrsSpdLmtrDrvSelSpd 1;
BA_ "SignalType" SG_ 2149711872 CrsSpdLmtrDrvSelSpd "UNM";
BA_ "SignalLongName" SG_ 2149711872 CrsSpdLmtrDrvSelSpd "Cruise and Speed Limiter Driver Selected Speed";
BA_ "VNSigAllNodes" SG_ 2149711872 AutoMdSpdLmtStat 1;
BA_ "SignalType" SG_ 2149711872 AutoMdSpdLmtStat "ENM";
BA_ "SignalLongName" SG_ 2149711872 AutoMdSpdLmtStat "Auto Mode Speed Limit Status";
BA_ "VNSigAllNodes" SG_ 2149711872 ACCAutoSetSpdStat 1;
BA_ "SignalType" SG_ 2149711872 ACCAutoSetSpdStat "ENM";
BA_ "SignalLongName" SG_ 2149711872 ACCAutoSetSpdStat "Adaptive Cruise Control Auto Set Speed Status";
BA_ "VNSigAllNodes" SG_ 2149711872 VehDynYawRateV 1;
BA_ "SignalType" SG_ 2149711872 VehDynYawRateV "ENM";
BA_ "SignalLongName" SG_ 2149711872 VehDynYawRateV "Vehicle Dynamics Yaw Rate Validity";
BA_ "VNSigAllNodes" SG_ 2149711872 VehDynYawRate 1;
BA_ "SignalType" SG_ 2149711872 VehDynYawRate "SNM";
BA_ "SignalLongName" SG_ 2149711872 VehDynYawRate "Vehicle Dynamics Yaw Rate";
BA_ "VNSigAllNodes" SG_ 2149711872 ACCAct370 1;
BA_ "SignalType" SG_ 2149711872 ACCAct370 "BLN";
BA_ "SignalLongName" SG_ 2149711872 ACCAct370 "Adaptive Cruise Control Active";
BA_ "GenSigSendOnInit" SG_ 2162982912 VehIdNmDig10_17 2;
BA_ "VNSigAllNodes" SG_ 2162982912 VehIdNmDig10_17 1;
BA_ "SignalType" SG_ 2162982912 VehIdNmDig10_17 "ASC";
BA_ "SignalLongName" SG_ 2162982912 VehIdNmDig10_17 "Vehicle Identification Number Digits 10-17";
BA_ "GenSigSendOnInit" SG_ 2162966528 VehIdNmDig2_9 2;
BA_ "VNSigAllNodes" SG_ 2162966528 VehIdNmDig2_9 1;
BA_ "SignalType" SG_ 2162966528 VehIdNmDig2_9 "ASC";
BA_ "SignalLongName" SG_ 2162966528 VehIdNmDig2_9 "Vehicle Identification Number Digits 2-9";
BA_ "VNSigDiagnostic" SG_ 601 DgnInf 1;
BA_ "GenSigSendType" SG_ 601 DgnInf 12;
BA_ "GenSigDeltaValue" SG_ 601 DgnInf 1;
BA_ "VNSigAllNodes" SG_ 601 DgnInf 1;
BA_ "SignalType" SG_ 601 DgnInf "UNM";
BA_ "SignalLongName" SG_ 601 DgnInf "Diagnostic Information";
BA_ "GenSigSendType" SG_ 2158854144 ODIAI_DaTy 10;
BA_ "GenSigDeltaValue" SG_ 2158854144 ODIAI_DaTy 1;
BA_ "VNSigAllNodes" SG_ 2158854144 ODIAI_DaTy 1;
BA_ "SignalType" SG_ 2158854144 ODIAI_DaTy "ENM";
BA_ "PacketOrder" SG_ 2158854144 ODIAI_DaTy 1;
BA_ "SignalLongName" SG_ 2158854144 ODIAI_DaTy "Open Display Interface Action IPC : DataType";
BA_ "GenSigSendType" SG_ 2158854144 ODIAI_FUCID 12;
BA_ "GenSigDeltaValue" SG_ 2158854144 ODIAI_FUCID 1;
BA_ "VNSigAllNodes" SG_ 2158854144 ODIAI_FUCID 1;
BA_ "SignalType" SG_ 2158854144 ODIAI_FUCID "UNM";
BA_ "PacketOrder" SG_ 2158854144 ODIAI_FUCID 2;
BA_ "SignalLongName" SG_ 2158854144 ODIAI_FUCID "Open Display Interface Action IPC : FU Class ID";
BA_ "GenSigSendType" SG_ 2158854144 ODIAI_DspMID 10;
BA_ "VNSigAllNodes" SG_ 2158854144 ODIAI_DspMID 1;
BA_ "SignalType" SG_ 2158854144 ODIAI_DspMID "ENM";
BA_ "PacketOrder" SG_ 2158854144 ODIAI_DspMID 4;
BA_ "SignalLongName" SG_ 2158854144 ODIAI_DspMID "Open Display Interface Action IPC : Display Mask ID";
BA_ "GenSigSendType" SG_ 2158854144 ODIAI_ActnVal 12;
BA_ "GenSigDeltaValue" SG_ 2158854144 ODIAI_ActnVal 1;
BA_ "VNSigAllNodes" SG_ 2158854144 ODIAI_ActnVal 1;
BA_ "SignalType" SG_ 2158854144 ODIAI_ActnVal "UNM";
BA_ "PacketOrder" SG_ 2158854144 ODIAI_ActnVal 5;
BA_ "SignalLongName" SG_ 2158854144 ODIAI_ActnVal "Open Display Interface Action IPC : Action Value";
BA_ "GenSigSendType" SG_ 2158854144 ODIAI_ActnID 12;
BA_ "GenSigDeltaValue" SG_ 2158854144 ODIAI_ActnID 1;
BA_ "VNSigAllNodes" SG_ 2158854144 ODIAI_ActnID 1;
BA_ "SignalType" SG_ 2158854144 ODIAI_ActnID "UNM";
BA_ "PacketOrder" SG_ 2158854144 ODIAI_ActnID 3;
BA_ "SignalLongName" SG_ 2158854144 ODIAI_ActnID "Open Display Interface Action IPC : Action ID";
BA_ "VNSigParkedVehicle" SG_ 2149629952 RtTrnLmpOn 1;
BA_ "GenSigSendOnInit" SG_ 2149629952 RtTrnLmpOn 1;
BA_ "GenSigSendType" SG_ 2149629952 RtTrnLmpOn 10;
BA_ "VNSigAllNodes" SG_ 2149629952 RtTrnLmpOn 1;
BA_ "SignalType" SG_ 2149629952 RtTrnLmpOn "BLN";
BA_ "SignalLongName" SG_ 2149629952 RtTrnLmpOn "Right Turn Lamp On";
BA_ "VNSigParkedVehicle" SG_ 2149629952 LftTrnLmpOn 1;
BA_ "GenSigSendOnInit" SG_ 2149629952 LftTrnLmpOn 1;
BA_ "GenSigSendType" SG_ 2149629952 LftTrnLmpOn 10;
BA_ "VNSigAllNodes" SG_ 2149629952 LftTrnLmpOn 1;
BA_ "SignalType" SG_ 2149629952 LftTrnLmpOn "BLN";
BA_ "SignalLongName" SG_ 2149629952 LftTrnLmpOn "Left Turn Lamp On";
BA_ "GenSigSendType" SG_ 2149629952 FrFogLmpsAct 10;
BA_ "VNSigAllNodes" SG_ 2149629952 FrFogLmpsAct 1;
BA_ "SignalType" SG_ 2149629952 FrFogLmpsAct "BLN";
BA_ "SignalLongName" SG_ 2149629952 FrFogLmpsAct "Front Fog Lamps Active";
BA_ "GenSigSendType" SG_ 2149629952 HiBmReqd 10;
BA_ "VNSigAllNodes" SG_ 2149629952 HiBmReqd 1;
BA_ "SignalType" SG_ 2149629952 HiBmReqd "BLN";
BA_ "SignalLongName" SG_ 2149629952 HiBmReqd "High Beam Requested";
BA_ "VNSigParkedVehicle" SG_ 2149629952 PrkLtRightOn 1;
BA_ "GenSigSendOnInit" SG_ 2149629952 PrkLtRightOn 2;
BA_ "GenSigSendType" SG_ 2149629952 PrkLtRightOn 10;
BA_ "VNSigAllNodes" SG_ 2149629952 PrkLtRightOn 1;
BA_ "SignalType" SG_ 2149629952 PrkLtRightOn "BLN";
BA_ "SignalLongName" SG_ 2149629952 PrkLtRightOn "Park Light Right On";
BA_ "VNSigParkedVehicle" SG_ 2149629952 PrkLtLeftOn 1;
BA_ "GenSigSendOnInit" SG_ 2149629952 PrkLtLeftOn 2;
BA_ "GenSigSendType" SG_ 2149629952 PrkLtLeftOn 10;
BA_ "VNSigAllNodes" SG_ 2149629952 PrkLtLeftOn 1;
BA_ "SignalType" SG_ 2149629952 PrkLtLeftOn "BLN";
BA_ "SignalLongName" SG_ 2149629952 PrkLtLeftOn "Park Light Left On";
BA_ "VNSigParkedVehicle" SG_ 2149629952 PrkLtRightIO 1;
BA_ "GenSigSendOnInit" SG_ 2149629952 PrkLtRightIO 2;
BA_ "GenSigSendType" SG_ 2149629952 PrkLtRightIO 10;
BA_ "VNSigAllNodes" SG_ 2149629952 PrkLtRightIO 1;
BA_ "SignalType" SG_ 2149629952 PrkLtRightIO "BLN";
BA_ "SignalLongName" SG_ 2149629952 PrkLtRightIO "Park Light Right Indication On";
BA_ "GenSigSendOnInit" SG_ 2149629952 MainLghtSw 1;
BA_ "GenSigSendType" SG_ 2149629952 MainLghtSw 10;
BA_ "VNSigAllNodes" SG_ 2149629952 MainLghtSw 1;
BA_ "SignalType" SG_ 2149629952 MainLghtSw "ENM";
BA_ "SignalLongName" SG_ 2149629952 MainLghtSw "Main Light Switch";
BA_ "VNSigParkedVehicle" SG_ 2149629952 PrkLtLeftIO 1;
BA_ "GenSigSendOnInit" SG_ 2149629952 PrkLtLeftIO 2;
BA_ "GenSigSendType" SG_ 2149629952 PrkLtLeftIO 10;
BA_ "VNSigAllNodes" SG_ 2149629952 PrkLtLeftIO 1;
BA_ "SignalType" SG_ 2149629952 PrkLtLeftIO "BLN";
BA_ "SignalLongName" SG_ 2149629952 PrkLtLeftIO "Park Light Left Indication On";
BA_ "GenSigSendOnInit" SG_ 2149629952 HiBmIO 1;
BA_ "GenSigSendType" SG_ 2149629952 HiBmIO 10;
BA_ "VNSigAllNodes" SG_ 2149629952 HiBmIO 1;
BA_ "SignalType" SG_ 2149629952 HiBmIO "BLN";
BA_ "SignalLongName" SG_ 2149629952 HiBmIO "High Beam Indication On";
BA_ "GenSigSendOnInit" SG_ 2149629952 FrFgLtIO 1;
BA_ "GenSigSendType" SG_ 2149629952 FrFgLtIO 10;
BA_ "VNSigAllNodes" SG_ 2149629952 FrFgLtIO 1;
BA_ "SignalType" SG_ 2149629952 FrFgLtIO "BLN";
BA_ "SignalLongName" SG_ 2149629952 FrFgLtIO "Front Fog Light Indication On";
BA_ "GenSigSendType" SG_ 2149629952 AutoLtsInactIO 10;
BA_ "VNSigAllNodes" SG_ 2149629952 AutoLtsInactIO 1;
BA_ "SignalType" SG_ 2149629952 AutoLtsInactIO "BLN";
BA_ "SignalLongName" SG_ 2149629952 AutoLtsInactIO "Automatic Lights Inactive Indication On";
BA_ "GenSigSendType" SG_ 2149629952 AutoLtsActIO 10;
BA_ "VNSigAllNodes" SG_ 2149629952 AutoLtsActIO 1;
BA_ "SignalType" SG_ 2149629952 AutoLtsActIO "BLN";
BA_ "SignalLongName" SG_ 2149629952 AutoLtsActIO "Automatic Lights Active Indication On";
BA_ "GenSigSendOnInit" SG_ 2149629952 RevLmpAtv 1;
BA_ "GenSigSendType" SG_ 2149629952 RevLmpAtv 10;
BA_ "VNSigAllNodes" SG_ 2149629952 RevLmpAtv 1;
BA_ "SignalType" SG_ 2149629952 RevLmpAtv "BLN";
BA_ "SignalLongName" SG_ 2149629952 RevLmpAtv "Reversing Lamp";
BA_ "GenSigSendOnInit" SG_ 2149629952 HdlmpBmSelectStat 1;
BA_ "GenSigSendType" SG_ 2149629952 HdlmpBmSelectStat 10;
BA_ "VNSigAllNodes" SG_ 2149629952 HdlmpBmSelectStat 1;
BA_ "SignalType" SG_ 2149629952 HdlmpBmSelectStat "ENM";
BA_ "SignalLongName" SG_ 2149629952 HdlmpBmSelectStat "Headlamp Beam Select Status";
BA_ "GenSigSendType" SG_ 2149629952 SrvlnceMdAct 10;
BA_ "VNSigAllNodes" SG_ 2149629952 SrvlnceMdAct 1;
BA_ "SignalType" SG_ 2149629952 SrvlnceMdAct "BLN";
BA_ "SignalLongName" SG_ 2149629952 SrvlnceMdAct "Surveillance Mode Active";
BA_ "GenSigSendType" SG_ 2149629952 RrFgLtIO 10;
BA_ "VNSigAllNodes" SG_ 2149629952 RrFgLtIO 1;
BA_ "SignalType" SG_ 2149629952 RrFgLtIO "BLN";
BA_ "SignalLongName" SG_ 2149629952 RrFgLtIO "Rear Fog Light Indication On";
BA_ "VNSigParkedVehicle" SG_ 2149629952 PrkLtIO 1;
BA_ "GenSigSendOnInit" SG_ 2149629952 PrkLtIO 2;
BA_ "GenSigSendType" SG_ 2149629952 PrkLtIO 10;
BA_ "VNSigAllNodes" SG_ 2149629952 PrkLtIO 1;
BA_ "SignalType" SG_ 2149629952 PrkLtIO "BLN";
BA_ "SignalLongName" SG_ 2149629952 PrkLtIO "Park Light Indication On";
BA_ "GenSigSendOnInit" SG_ 2149629952 RrFogLmpsAct 1;
BA_ "GenSigSendType" SG_ 2149629952 RrFogLmpsAct 10;
BA_ "VNSigAllNodes" SG_ 2149629952 RrFogLmpsAct 1;
BA_ "SignalType" SG_ 2149629952 RrFogLmpsAct "BLN";
BA_ "SignalLongName" SG_ 2149629952 RrFogLmpsAct "Rear Fog Lamps Active";
BA_ "VNSigParkedVehicle" SG_ 2149629952 PrkngLtsAct 1;
BA_ "GenSigSendOnInit" SG_ 2149629952 PrkngLtsAct 1;
BA_ "GenSigSendType" SG_ 2149629952 PrkngLtsAct 10;
BA_ "VNSigAllNodes" SG_ 2149629952 PrkngLtsAct 1;
BA_ "SignalType" SG_ 2149629952 PrkngLtsAct "BLN";
BA_ "SignalLongName" SG_ 2149629952 PrkngLtsAct "Parking Lights Active";
BA_ "GenSigSendOnInit" SG_ 2149629952 BrkLtsAtv 1;
BA_ "GenSigSendType" SG_ 2149629952 BrkLtsAtv 10;
BA_ "VNSigAllNodes" SG_ 2149629952 BrkLtsAtv 1;
BA_ "SignalType" SG_ 2149629952 BrkLtsAtv "BLN";
BA_ "SignalLongName" SG_ 2149629952 BrkLtsAtv "Brake Lights Active";
BA_ "GenSigSendOnInit" SG_ 2149629952 AutoBmSlctAllwd 2;
BA_ "GenSigSendType" SG_ 2149629952 AutoBmSlctAllwd 10;
BA_ "VNSigAllNodes" SG_ 2149629952 AutoBmSlctAllwd 1;
BA_ "SignalType" SG_ 2149629952 AutoBmSlctAllwd "BLN";
BA_ "SignalLongName" SG_ 2149629952 AutoBmSlctAllwd "Automatic Beam Select Allowed";
BA_ "GenSigSendType" SG_ 2149629952 FlToPsSwAtv 10;
BA_ "VNSigAllNodes" SG_ 2149629952 FlToPsSwAtv 1;
BA_ "SignalType" SG_ 2149629952 FlToPsSwAtv "BLN";
BA_ "SignalLongName" SG_ 2149629952 FlToPsSwAtv "Flash To Pass Switch Active";
BA_ "GenSigSendType" SG_ 2149629952 DRLAct 10;
BA_ "VNSigAllNodes" SG_ 2149629952 DRLAct 1;
BA_ "SignalType" SG_ 2149629952 DRLAct "BLN";
BA_ "SignalLongName" SG_ 2149629952 DRLAct "Daytime Running Lamps Active";
BA_ "GenSigSendOnInit" SG_ 2149629952 TrnSwAct 1;
BA_ "GenSigSendType" SG_ 2149629952 TrnSwAct 10;
BA_ "VNSigAllNodes" SG_ 2149629952 TrnSwAct 1;
BA_ "SignalType" SG_ 2149629952 TrnSwAct "ENM";
BA_ "SignalLongName" SG_ 2149629952 TrnSwAct "Turn Switch Activation";
BA_ "VNSigParkedVehicle" SG_ 2149629952 HazSwAtv 1;
BA_ "GenSigSendOnInit" SG_ 2149629952 HazSwAtv 1;
BA_ "GenSigSendType" SG_ 2149629952 HazSwAtv 10;
BA_ "VNSigAllNodes" SG_ 2149629952 HazSwAtv 1;
BA_ "SignalType" SG_ 2149629952 HazSwAtv "BLN";
BA_ "SignalLongName" SG_ 2149629952 HazSwAtv "Hazard Switch Active";
BA_ "VNSigParkedVehicle" SG_ 2149629952 LftTrnLmpAtv 1;
BA_ "GenSigSendOnInit" SG_ 2149629952 LftTrnLmpAtv 1;
BA_ "GenSigSendType" SG_ 2149629952 LftTrnLmpAtv 10;
BA_ "VNSigAllNodes" SG_ 2149629952 LftTrnLmpAtv 1;
BA_ "SignalType" SG_ 2149629952 LftTrnLmpAtv "ENM";
BA_ "SignalLongName" SG_ 2149629952 LftTrnLmpAtv "Left Turn Lamp Active";
BA_ "VNSigParkedVehicle" SG_ 2149629952 RtTrnLmpAtv 1;
BA_ "GenSigSendOnInit" SG_ 2149629952 RtTrnLmpAtv 1;
BA_ "GenSigSendType" SG_ 2149629952 RtTrnLmpAtv 10;
BA_ "VNSigAllNodes" SG_ 2149629952 RtTrnLmpAtv 1;
BA_ "SignalType" SG_ 2149629952 RtTrnLmpAtv "ENM";
BA_ "SignalLongName" SG_ 2149629952 RtTrnLmpAtv "Right Turn Lamp Active";
BA_ "GenSigSendType" SG_ 2149629952 OtsdAmbtLtLvlStatV 10;
BA_ "VNSigAllNodes" SG_ 2149629952 OtsdAmbtLtLvlStatV 1;
BA_ "SignalType" SG_ 2149629952 OtsdAmbtLtLvlStatV "ENM";
BA_ "SignalLongName" SG_ 2149629952 OtsdAmbtLtLvlStatV "Outside Ambient Light Level Status Validity";
BA_ "GenSigSendType" SG_ 2149629952 OtsdAmbtLtLvlStat 10;
BA_ "VNSigAllNodes" SG_ 2149629952 OtsdAmbtLtLvlStat 1;
BA_ "SignalType" SG_ 2149629952 OtsdAmbtLtLvlStat "ENM";
BA_ "SignalLongName" SG_ 2149629952 OtsdAmbtLtLvlStat "Outside Ambient Light Level Status";
BA_ "GenSigSendType" SG_ 2155028480 RtLnChngThrtAprchSpd 12;
BA_ "GenSigDeltaValue" SG_ 2155028480 RtLnChngThrtAprchSpd 1;
BA_ "VNSigAllNodes" SG_ 2155028480 RtLnChngThrtAprchSpd 1;
BA_ "SignalType" SG_ 2155028480 RtLnChngThrtAprchSpd "SNM";
BA_ "SignalLongName" SG_ 2155028480 RtLnChngThrtAprchSpd "Right Lane Change Threat Approach Speed";
BA_ "GenSigSendOnInit" SG_ 2155028480 RgtLnChgThrt 2;
BA_ "GenSigSendType" SG_ 2155028480 RgtLnChgThrt 10;
BA_ "VNSigAllNodes" SG_ 2155028480 RgtLnChgThrt 1;
BA_ "SignalType" SG_ 2155028480 RgtLnChgThrt "BLN";
BA_ "SignalLongName" SG_ 2155028480 RgtLnChgThrt "Right Lane Change Threat";
BA_ "GenSigSendOnInit" SG_ 2149941248 PrkAstRrObjSnsngAct 2;
BA_ "GenSigSendType" SG_ 2149941248 PrkAstRrObjSnsngAct 10;
BA_ "VNSigAllNodes" SG_ 2149941248 PrkAstRrObjSnsngAct 1;
BA_ "SignalType" SG_ 2149941248 PrkAstRrObjSnsngAct "BLN";
BA_ "SignalLongName" SG_ 2149941248 PrkAstRrObjSnsngAct "Park Assistance Rear Object Sensing Active";
BA_ "GenSigSendOnInit" SG_ 2149941248 PrkAstRrSysStatUnfltd 2;
BA_ "GenSigSendType" SG_ 2149941248 PrkAstRrSysStatUnfltd 10;
BA_ "VNSigAllNodes" SG_ 2149941248 PrkAstRrSysStatUnfltd 1;
BA_ "SignalType" SG_ 2149941248 PrkAstRrSysStatUnfltd "ENM";
BA_ "SignalLongName" SG_ 2149941248 PrkAstRrSysStatUnfltd "Parking Assistance Rear System Status Unfiltered";
BA_ "GenSigSendOnInit" SG_ 2149941248 PrkAstRrExtdDstUnfltd 2;
BA_ "GenSigSendType" SG_ 2149941248 PrkAstRrExtdDstUnfltd 12;
BA_ "GenSigDeltaValue" SG_ 2149941248 PrkAstRrExtdDstUnfltd 1;
BA_ "VNSigAllNodes" SG_ 2149941248 PrkAstRrExtdDstUnfltd 1;
BA_ "SignalType" SG_ 2149941248 PrkAstRrExtdDstUnfltd "UNM";
BA_ "SignalLongName" SG_ 2149941248 PrkAstRrExtdDstUnfltd "Parking Assistance Rear Extended Distance Unfiltered";
BA_ "GenSigSendOnInit" SG_ 2149941248 PrkAstFntnSnsDstrbdIO 2;
BA_ "GenSigSendType" SG_ 2149941248 PrkAstFntnSnsDstrbdIO 10;
BA_ "VNSigAllNodes" SG_ 2149941248 PrkAstFntnSnsDstrbdIO 1;
BA_ "SignalType" SG_ 2149941248 PrkAstFntnSnsDstrbdIO "BLN";
BA_ "SignalLongName" SG_ 2149941248 PrkAstFntnSnsDstrbdIO "Parking Assistance Function Sensors Disturbed Indication On";
BA_ "GenSigSendOnInit" SG_ 2149941248 PrkAstFntnSnrsBlkd 2;
BA_ "GenSigSendType" SG_ 2149941248 PrkAstFntnSnrsBlkd 10;
BA_ "VNSigAllNodes" SG_ 2149941248 PrkAstFntnSnrsBlkd 1;
BA_ "SignalType" SG_ 2149941248 PrkAstFntnSnrsBlkd "BLN";
BA_ "SignalLongName" SG_ 2149941248 PrkAstFntnSnrsBlkd "Parking Assistance Function Sensors Blocked";
BA_ "GenSigSendOnInit" SG_ 2149941248 PrkAstFntnFld 2;
BA_ "GenSigSendType" SG_ 2149941248 PrkAstFntnFld 10;
BA_ "VNSigAllNodes" SG_ 2149941248 PrkAstFntnFld 1;
BA_ "SignalType" SG_ 2149941248 PrkAstFntnFld "BLN";
BA_ "SignalLongName" SG_ 2149941248 PrkAstFntnFld "Parking Assistance Function Failed";
BA_ "GenSigSendOnInit" SG_ 2149941248 PrkAstFntnDsbldIO 2;
BA_ "GenSigSendType" SG_ 2149941248 PrkAstFntnDsbldIO 10;
BA_ "VNSigAllNodes" SG_ 2149941248 PrkAstFntnDsbldIO 1;
BA_ "SignalType" SG_ 2149941248 PrkAstFntnDsbldIO "BLN";
BA_ "SignalLongName" SG_ 2149941248 PrkAstFntnDsbldIO "Parking Assistance Function Disabled Indication On";
BA_ "GenSigSendOnInit" SG_ 2149941248 PrkAstFntnClnPrkAstIO 2;
BA_ "GenSigSendType" SG_ 2149941248 PrkAstFntnClnPrkAstIO 10;
BA_ "VNSigAllNodes" SG_ 2149941248 PrkAstFntnClnPrkAstIO 1;
BA_ "SignalType" SG_ 2149941248 PrkAstFntnClnPrkAstIO "BLN";
BA_ "SignalLongName" SG_ 2149941248 PrkAstFntnClnPrkAstIO "Parking Assistance Function Clean Parking Assist Indication On";
BA_ "GenSigSendOnInit" SG_ 2149941248 ClsnMtgtnInhbtReqtd 2;
BA_ "GenSigSendType" SG_ 2149941248 ClsnMtgtnInhbtReqtd 10;
BA_ "VNSigAllNodes" SG_ 2149941248 ClsnMtgtnInhbtReqtd 1;
BA_ "SignalType" SG_ 2149941248 ClsnMtgtnInhbtReqtd "BLN";
BA_ "SignalLongName" SG_ 2149941248 ClsnMtgtnInhbtReqtd "Collision Mitigation Inhibit Requested";
BA_ "GenSigSendOnInit" SG_ 2149941248 PARrRgn4ObjStatUnfltd 2;
BA_ "GenSigSendType" SG_ 2149941248 PARrRgn4ObjStatUnfltd 10;
BA_ "VNSigAllNodes" SG_ 2149941248 PARrRgn4ObjStatUnfltd 1;
BA_ "SignalType" SG_ 2149941248 PARrRgn4ObjStatUnfltd "ENM";
BA_ "SignalLongName" SG_ 2149941248 PARrRgn4ObjStatUnfltd "Parking Assistance Rear Region 4 Object Status Unfiltered";
BA_ "GenSigSendOnInit" SG_ 2149941248 PARrRgn3ObjStatUnfltd 2;
BA_ "GenSigSendType" SG_ 2149941248 PARrRgn3ObjStatUnfltd 10;
BA_ "VNSigAllNodes" SG_ 2149941248 PARrRgn3ObjStatUnfltd 1;
BA_ "SignalType" SG_ 2149941248 PARrRgn3ObjStatUnfltd "ENM";
BA_ "SignalLongName" SG_ 2149941248 PARrRgn3ObjStatUnfltd "Parking Assistance Rear Region 3 Object Status Unfiltered";
BA_ "GenSigSendOnInit" SG_ 2149941248 PARrRgn2ObjStatUnfltd 2;
BA_ "GenSigSendType" SG_ 2149941248 PARrRgn2ObjStatUnfltd 10;
BA_ "VNSigAllNodes" SG_ 2149941248 PARrRgn2ObjStatUnfltd 1;
BA_ "SignalType" SG_ 2149941248 PARrRgn2ObjStatUnfltd "ENM";
BA_ "SignalLongName" SG_ 2149941248 PARrRgn2ObjStatUnfltd "Parking Assistance Rear Region 2 Object Status Unfiltered";
BA_ "GenSigSendOnInit" SG_ 2149941248 PARrRgn1ObjStatUnfltd 2;
BA_ "GenSigSendType" SG_ 2149941248 PARrRgn1ObjStatUnfltd 10;
BA_ "VNSigAllNodes" SG_ 2149941248 PARrRgn1ObjStatUnfltd 1;
BA_ "SignalType" SG_ 2149941248 PARrRgn1ObjStatUnfltd "ENM";
BA_ "SignalLongName" SG_ 2149941248 PARrRgn1ObjStatUnfltd "Parking Assistance Rear Region 1 Object Status Unfiltered";
BA_ "GenSigSendType" SG_ 2151342080 PrkAstRtSysStat 10;
BA_ "VNSigAllNodes" SG_ 2151342080 PrkAstRtSysStat 1;
BA_ "SignalType" SG_ 2151342080 PrkAstRtSysStat "ENM";
BA_ "SignalLongName" SG_ 2151342080 PrkAstRtSysStat "Parking Assistance Right System Status";
BA_ "GenSigSendType" SG_ 2151342080 PARtRgn3ObjStat 10;
BA_ "VNSigAllNodes" SG_ 2151342080 PARtRgn3ObjStat 1;
BA_ "SignalType" SG_ 2151342080 PARtRgn3ObjStat "ENM";
BA_ "SignalLongName" SG_ 2151342080 PARtRgn3ObjStat "Parking Assistance Right Region 3 Object Status";
BA_ "GenSigSendType" SG_ 2151342080 PARtRgn2ObjStat 10;
BA_ "VNSigAllNodes" SG_ 2151342080 PARtRgn2ObjStat 1;
BA_ "SignalType" SG_ 2151342080 PARtRgn2ObjStat "ENM";
BA_ "SignalLongName" SG_ 2151342080 PARtRgn2ObjStat "Parking Assistance Right Region 2 Object Status";
BA_ "GenSigSendType" SG_ 2151342080 PARtRgn1ObjStat 10;
BA_ "VNSigAllNodes" SG_ 2151342080 PARtRgn1ObjStat 1;
BA_ "SignalType" SG_ 2151342080 PARtRgn1ObjStat "ENM";
BA_ "SignalLongName" SG_ 2151342080 PARtRgn1ObjStat "Parking Assistance Right Region 1 Object Status";
BA_ "GenSigSendType" SG_ 2151325696 PrkAstLtSysStat 10;
BA_ "VNSigAllNodes" SG_ 2151325696 PrkAstLtSysStat 1;
BA_ "SignalType" SG_ 2151325696 PrkAstLtSysStat "ENM";
BA_ "SignalLongName" SG_ 2151325696 PrkAstLtSysStat "Parking Assistance Left System Status";
BA_ "GenSigSendType" SG_ 2151325696 PALtRgn3ObjStat 10;
BA_ "VNSigAllNodes" SG_ 2151325696 PALtRgn3ObjStat 1;
BA_ "SignalType" SG_ 2151325696 PALtRgn3ObjStat "ENM";
BA_ "SignalLongName" SG_ 2151325696 PALtRgn3ObjStat "Parking Assistance Left Region 3 Object Status";
BA_ "GenSigSendType" SG_ 2151325696 PALtRgn2ObjStat 10;
BA_ "VNSigAllNodes" SG_ 2151325696 PALtRgn2ObjStat 1;
BA_ "SignalType" SG_ 2151325696 PALtRgn2ObjStat "ENM";
BA_ "SignalLongName" SG_ 2151325696 PALtRgn2ObjStat "Parking Assistance Left Region 2 Object Status";
BA_ "GenSigSendType" SG_ 2151325696 PALtRgn1ObjStat 10;
BA_ "VNSigAllNodes" SG_ 2151325696 PALtRgn1ObjStat 1;
BA_ "SignalType" SG_ 2151325696 PALtRgn1ObjStat "ENM";
BA_ "SignalLongName" SG_ 2151325696 PALtRgn1ObjStat "Parking Assistance Left Region 1 Object Status";
BA_ "GenSigSendType" SG_ 2151350272 APAIconFilPctRq 12;
BA_ "GenSigDeltaValue" SG_ 2151350272 APAIconFilPctRq 1;
BA_ "VNSigAllNodes" SG_ 2151350272 APAIconFilPctRq 1;
BA_ "SignalType" SG_ 2151350272 APAIconFilPctRq "UNM";
BA_ "SignalLongName" SG_ 2151350272 APAIconFilPctRq "Advanced Park Assist Icon Fill Percent Request";
BA_ "GenSigSendType" SG_ 2151350272 APAIconDispRq 10;
BA_ "VNSigAllNodes" SG_ 2151350272 APAIconDispRq 1;
BA_ "SignalType" SG_ 2151350272 APAIconDispRq "ENM";
BA_ "SignalLongName" SG_ 2151350272 APAIconDispRq "Advanced Park Assist Icon Display Request";
BA_ "GenSigSendType" SG_ 2151350272 FPAHptcStVbnRqSeqN 12;
BA_ "GenSigDeltaValue" SG_ 2151350272 FPAHptcStVbnRqSeqN 1;
BA_ "VNSigAllNodes" SG_ 2151350272 FPAHptcStVbnRqSeqN 1;
BA_ "SignalType" SG_ 2151350272 FPAHptcStVbnRqSeqN "UNM";
BA_ "SignalLongName" SG_ 2151350272 FPAHptcStVbnRqSeqN "Front Park Assist Haptic Seat Vibration Request Sequence Number";
BA_ "GenSigSendType" SG_ 2151350272 FPAHptcStVbnReq 12;
BA_ "GenSigDeltaValue" SG_ 2151350272 FPAHptcStVbnReq 1;
BA_ "VNSigAllNodes" SG_ 2151350272 FPAHptcStVbnReq 1;
BA_ "SignalType" SG_ 2151350272 FPAHptcStVbnReq "UNM";
BA_ "SignalLongName" SG_ 2151350272 FPAHptcStVbnReq "Front Park Assist Haptic Seat Vibration Request";
BA_ "GenSigSendType" SG_ 2151333888 RPAHptcStVbRqSeqN 12;
BA_ "GenSigDeltaValue" SG_ 2151333888 RPAHptcStVbRqSeqN 1;
BA_ "VNSigAllNodes" SG_ 2151333888 RPAHptcStVbRqSeqN 1;
BA_ "SignalType" SG_ 2151333888 RPAHptcStVbRqSeqN "UNM";
BA_ "SignalLongName" SG_ 2151333888 RPAHptcStVbRqSeqN "Rear Parking Assist Haptic Seat Vibration Request Sequence Number";
BA_ "GenSigSendType" SG_ 2151333888 RPAHptcStVbnReq 12;
BA_ "GenSigDeltaValue" SG_ 2151333888 RPAHptcStVbnReq 1;
BA_ "VNSigAllNodes" SG_ 2151333888 RPAHptcStVbnReq 1;
BA_ "SignalType" SG_ 2151333888 RPAHptcStVbnReq "UNM";
BA_ "SignalLongName" SG_ 2151333888 RPAHptcStVbnReq "Rear Parking Assist Haptic Seat Vibration Request";
BA_ "GenSigSendOnInit" SG_ 2158796800 ODII_ODIInd55 1;
BA_ "GenSigSendType" SG_ 2158796800 ODII_ODIInd55 10;
BA_ "VNSigAllNodes" SG_ 2158796800 ODII_ODIInd55 1;
BA_ "SignalType" SG_ 2158796800 ODII_ODIInd55 "BLN";
BA_ "PacketOrder" SG_ 2158796800 ODII_ODIInd55 56;
BA_ "SignalLongName" SG_ 2158796800 ODII_ODIInd55 "Open Display Interface Indication : Open Display Interface Indication 55";
BA_ "GenSigSendOnInit" SG_ 2158796800 ODII_ODIInd54 1;
BA_ "GenSigSendType" SG_ 2158796800 ODII_ODIInd54 10;
BA_ "VNSigAllNodes" SG_ 2158796800 ODII_ODIInd54 1;
BA_ "SignalType" SG_ 2158796800 ODII_ODIInd54 "BLN";
BA_ "PacketOrder" SG_ 2158796800 ODII_ODIInd54 55;
BA_ "SignalLongName" SG_ 2158796800 ODII_ODIInd54 "Open Display Interface Indication : Open Display Interface Indication 54";
BA_ "GenSigSendOnInit" SG_ 2158796800 ODII_ODIInd53 1;
BA_ "GenSigSendType" SG_ 2158796800 ODII_ODIInd53 10;
BA_ "VNSigAllNodes" SG_ 2158796800 ODII_ODIInd53 1;
BA_ "SignalType" SG_ 2158796800 ODII_ODIInd53 "BLN";
BA_ "PacketOrder" SG_ 2158796800 ODII_ODIInd53 54;
BA_ "SignalLongName" SG_ 2158796800 ODII_ODIInd53 "Open Display Interface Indication : Open Display Interface Indication 53";
BA_ "GenSigSendOnInit" SG_ 2158796800 ODII_ODIInd52 1;
BA_ "GenSigSendType" SG_ 2158796800 ODII_ODIInd52 10;
BA_ "VNSigAllNodes" SG_ 2158796800 ODII_ODIInd52 1;
BA_ "SignalType" SG_ 2158796800 ODII_ODIInd52 "BLN";
BA_ "PacketOrder" SG_ 2158796800 ODII_ODIInd52 53;
BA_ "SignalLongName" SG_ 2158796800 ODII_ODIInd52 "Open Display Interface Indication : Open Display Interface Indication 52";
BA_ "GenSigSendOnInit" SG_ 2158796800 ODII_ODIInd51 1;
BA_ "GenSigSendType" SG_ 2158796800 ODII_ODIInd51 10;
BA_ "VNSigAllNodes" SG_ 2158796800 ODII_ODIInd51 1;
BA_ "SignalType" SG_ 2158796800 ODII_ODIInd51 "BLN";
BA_ "PacketOrder" SG_ 2158796800 ODII_ODIInd51 52;
BA_ "SignalLongName" SG_ 2158796800 ODII_ODIInd51 "Open Display Interface Indication : Open Display Interface Indication 51";
BA_ "GenSigSendOnInit" SG_ 2158796800 ODII_ODIInd50 1;
BA_ "GenSigSendType" SG_ 2158796800 ODII_ODIInd50 10;
BA_ "VNSigAllNodes" SG_ 2158796800 ODII_ODIInd50 1;
BA_ "SignalType" SG_ 2158796800 ODII_ODIInd50 "BLN";
BA_ "PacketOrder" SG_ 2158796800 ODII_ODIInd50 51;
BA_ "SignalLongName" SG_ 2158796800 ODII_ODIInd50 "Open Display Interface Indication : Open Display Interface Indication 50";
BA_ "GenSigSendOnInit" SG_ 2158796800 ODII_ODIInd27 1;
BA_ "GenSigSendType" SG_ 2158796800 ODII_ODIInd27 10;
BA_ "VNSigAllNodes" SG_ 2158796800 ODII_ODIInd27 1;
BA_ "SignalType" SG_ 2158796800 ODII_ODIInd27 "BLN";
BA_ "PacketOrder" SG_ 2158796800 ODII_ODIInd27 28;
BA_ "SignalLongName" SG_ 2158796800 ODII_ODIInd27 "Open Display Interface Indication : Open Display Interface Indication 27";
BA_ "GenSigSendOnInit" SG_ 2158796800 ODII_ODIInd26 1;
BA_ "GenSigSendType" SG_ 2158796800 ODII_ODIInd26 10;
BA_ "VNSigAllNodes" SG_ 2158796800 ODII_ODIInd26 1;
BA_ "SignalType" SG_ 2158796800 ODII_ODIInd26 "BLN";
BA_ "PacketOrder" SG_ 2158796800 ODII_ODIInd26 27;
BA_ "SignalLongName" SG_ 2158796800 ODII_ODIInd26 "Open Display Interface Indication : Open Display Interface Indication 26";
BA_ "GenSigSendOnInit" SG_ 2158796800 ODII_ODIInd25 1;
BA_ "GenSigSendType" SG_ 2158796800 ODII_ODIInd25 10;
BA_ "VNSigAllNodes" SG_ 2158796800 ODII_ODIInd25 1;
BA_ "SignalType" SG_ 2158796800 ODII_ODIInd25 "BLN";
BA_ "PacketOrder" SG_ 2158796800 ODII_ODIInd25 26;
BA_ "SignalLongName" SG_ 2158796800 ODII_ODIInd25 "Open Display Interface Indication : Open Display Interface Indication 25";
BA_ "GenSigSendOnInit" SG_ 2158796800 ODII_ODIInd24 1;
BA_ "GenSigSendType" SG_ 2158796800 ODII_ODIInd24 10;
BA_ "VNSigAllNodes" SG_ 2158796800 ODII_ODIInd24 1;
BA_ "SignalType" SG_ 2158796800 ODII_ODIInd24 "BLN";
BA_ "PacketOrder" SG_ 2158796800 ODII_ODIInd24 25;
BA_ "SignalLongName" SG_ 2158796800 ODII_ODIInd24 "Open Display Interface Indication : Open Display Interface Indication 24";
BA_ "GenSigSendOnInit" SG_ 2158796800 ODII_ODIInd23 1;
BA_ "GenSigSendType" SG_ 2158796800 ODII_ODIInd23 10;
BA_ "VNSigAllNodes" SG_ 2158796800 ODII_ODIInd23 1;
BA_ "SignalType" SG_ 2158796800 ODII_ODIInd23 "BLN";
BA_ "PacketOrder" SG_ 2158796800 ODII_ODIInd23 24;
BA_ "SignalLongName" SG_ 2158796800 ODII_ODIInd23 "Open Display Interface Indication : Open Display Interface Indication 23";
BA_ "GenSigSendOnInit" SG_ 2158796800 ODII_ODIInd22 1;
BA_ "GenSigSendType" SG_ 2158796800 ODII_ODIInd22 10;
BA_ "VNSigAllNodes" SG_ 2158796800 ODII_ODIInd22 1;
BA_ "SignalType" SG_ 2158796800 ODII_ODIInd22 "BLN";
BA_ "PacketOrder" SG_ 2158796800 ODII_ODIInd22 23;
BA_ "SignalLongName" SG_ 2158796800 ODII_ODIInd22 "Open Display Interface Indication : Open Display Interface Indication 22";
BA_ "GenSigSendOnInit" SG_ 2158796800 ODII_ODIInd21 1;
BA_ "GenSigSendType" SG_ 2158796800 ODII_ODIInd21 10;
BA_ "VNSigAllNodes" SG_ 2158796800 ODII_ODIInd21 1;
BA_ "SignalType" SG_ 2158796800 ODII_ODIInd21 "BLN";
BA_ "PacketOrder" SG_ 2158796800 ODII_ODIInd21 22;
BA_ "SignalLongName" SG_ 2158796800 ODII_ODIInd21 "Open Display Interface Indication : Open Display Interface Indication 21";
BA_ "GenSigSendOnInit" SG_ 2158796800 ODII_ODIInd20 1;
BA_ "GenSigSendType" SG_ 2158796800 ODII_ODIInd20 10;
BA_ "VNSigAllNodes" SG_ 2158796800 ODII_ODIInd20 1;
BA_ "SignalType" SG_ 2158796800 ODII_ODIInd20 "BLN";
BA_ "PacketOrder" SG_ 2158796800 ODII_ODIInd20 21;
BA_ "SignalLongName" SG_ 2158796800 ODII_ODIInd20 "Open Display Interface Indication : Open Display Interface Indication 20";
BA_ "GenSigSendOnInit" SG_ 2158796800 ODII_ODIInd19 1;
BA_ "GenSigSendType" SG_ 2158796800 ODII_ODIInd19 10;
BA_ "VNSigAllNodes" SG_ 2158796800 ODII_ODIInd19 1;
BA_ "SignalType" SG_ 2158796800 ODII_ODIInd19 "BLN";
BA_ "PacketOrder" SG_ 2158796800 ODII_ODIInd19 20;
BA_ "SignalLongName" SG_ 2158796800 ODII_ODIInd19 "Open Display Interface Indication : Open Display Interface Indication 19";
BA_ "GenSigSendOnInit" SG_ 2158796800 ODII_ODIInd18 1;
BA_ "GenSigSendType" SG_ 2158796800 ODII_ODIInd18 10;
BA_ "VNSigAllNodes" SG_ 2158796800 ODII_ODIInd18 1;
BA_ "SignalType" SG_ 2158796800 ODII_ODIInd18 "BLN";
BA_ "PacketOrder" SG_ 2158796800 ODII_ODIInd18 19;
BA_ "SignalLongName" SG_ 2158796800 ODII_ODIInd18 "Open Display Interface Indication : Open Display Interface Indication 18";
BA_ "GenSigSendOnInit" SG_ 2158796800 ODII_ODIInd17 1;
BA_ "GenSigSendType" SG_ 2158796800 ODII_ODIInd17 10;
BA_ "VNSigAllNodes" SG_ 2158796800 ODII_ODIInd17 1;
BA_ "SignalType" SG_ 2158796800 ODII_ODIInd17 "BLN";
BA_ "PacketOrder" SG_ 2158796800 ODII_ODIInd17 18;
BA_ "SignalLongName" SG_ 2158796800 ODII_ODIInd17 "Open Display Interface Indication : Open Display Interface Indication 17";
BA_ "GenSigSendOnInit" SG_ 2158796800 ODII_ODIInd16 1;
BA_ "GenSigSendType" SG_ 2158796800 ODII_ODIInd16 10;
BA_ "VNSigAllNodes" SG_ 2158796800 ODII_ODIInd16 1;
BA_ "SignalType" SG_ 2158796800 ODII_ODIInd16 "BLN";
BA_ "PacketOrder" SG_ 2158796800 ODII_ODIInd16 17;
BA_ "SignalLongName" SG_ 2158796800 ODII_ODIInd16 "Open Display Interface Indication : Open Display Interface Indication 16";
BA_ "GenSigSendOnInit" SG_ 2158796800 ODII_ODIInd15 1;
BA_ "GenSigSendType" SG_ 2158796800 ODII_ODIInd15 10;
BA_ "VNSigAllNodes" SG_ 2158796800 ODII_ODIInd15 1;
BA_ "SignalType" SG_ 2158796800 ODII_ODIInd15 "BLN";
BA_ "PacketOrder" SG_ 2158796800 ODII_ODIInd15 16;
BA_ "SignalLongName" SG_ 2158796800 ODII_ODIInd15 "Open Display Interface Indication : Open Display Interface Indication 15";
BA_ "GenSigSendOnInit" SG_ 2158796800 ODII_ODIInd14 1;
BA_ "GenSigSendType" SG_ 2158796800 ODII_ODIInd14 10;
BA_ "VNSigAllNodes" SG_ 2158796800 ODII_ODIInd14 1;
BA_ "SignalType" SG_ 2158796800 ODII_ODIInd14 "BLN";
BA_ "PacketOrder" SG_ 2158796800 ODII_ODIInd14 15;
BA_ "SignalLongName" SG_ 2158796800 ODII_ODIInd14 "Open Display Interface Indication : Open Display Interface Indication 14";
BA_ "GenSigSendOnInit" SG_ 2158796800 ODII_ODIInd13 1;
BA_ "GenSigSendType" SG_ 2158796800 ODII_ODIInd13 10;
BA_ "VNSigAllNodes" SG_ 2158796800 ODII_ODIInd13 1;
BA_ "SignalType" SG_ 2158796800 ODII_ODIInd13 "BLN";
BA_ "PacketOrder" SG_ 2158796800 ODII_ODIInd13 14;
BA_ "SignalLongName" SG_ 2158796800 ODII_ODIInd13 "Open Display Interface Indication : Open Display Interface Indication 13";
BA_ "GenSigSendOnInit" SG_ 2158796800 ODII_ODIInd12 1;
BA_ "GenSigSendType" SG_ 2158796800 ODII_ODIInd12 10;
BA_ "VNSigAllNodes" SG_ 2158796800 ODII_ODIInd12 1;
BA_ "SignalType" SG_ 2158796800 ODII_ODIInd12 "BLN";
BA_ "PacketOrder" SG_ 2158796800 ODII_ODIInd12 13;
BA_ "SignalLongName" SG_ 2158796800 ODII_ODIInd12 "Open Display Interface Indication : Open Display Interface Indication 12";
BA_ "GenSigSendOnInit" SG_ 2158796800 ODII_ODIInd11 1;
BA_ "GenSigSendType" SG_ 2158796800 ODII_ODIInd11 10;
BA_ "VNSigAllNodes" SG_ 2158796800 ODII_ODIInd11 1;
BA_ "SignalType" SG_ 2158796800 ODII_ODIInd11 "BLN";
BA_ "PacketOrder" SG_ 2158796800 ODII_ODIInd11 12;
BA_ "SignalLongName" SG_ 2158796800 ODII_ODIInd11 "Open Display Interface Indication : Open Display Interface Indication 11";
BA_ "GenSigSendOnInit" SG_ 2158796800 ODII_ODIInd10 1;
BA_ "GenSigSendType" SG_ 2158796800 ODII_ODIInd10 10;
BA_ "VNSigAllNodes" SG_ 2158796800 ODII_ODIInd10 1;
BA_ "SignalType" SG_ 2158796800 ODII_ODIInd10 "BLN";
BA_ "PacketOrder" SG_ 2158796800 ODII_ODIInd10 11;
BA_ "SignalLongName" SG_ 2158796800 ODII_ODIInd10 "Open Display Interface Indication : Open Display Interface Indication 10";
BA_ "GenSigSendOnInit" SG_ 2158796800 ODII_ODIInd9 1;
BA_ "GenSigSendType" SG_ 2158796800 ODII_ODIInd9 10;
BA_ "VNSigAllNodes" SG_ 2158796800 ODII_ODIInd9 1;
BA_ "SignalType" SG_ 2158796800 ODII_ODIInd9 "BLN";
BA_ "PacketOrder" SG_ 2158796800 ODII_ODIInd9 10;
BA_ "SignalLongName" SG_ 2158796800 ODII_ODIInd9 "Open Display Interface Indication : Open Display Interface Indication 9";
BA_ "GenSigSendOnInit" SG_ 2158796800 ODII_ODIInd8 1;
BA_ "GenSigSendType" SG_ 2158796800 ODII_ODIInd8 10;
BA_ "VNSigAllNodes" SG_ 2158796800 ODII_ODIInd8 1;
BA_ "SignalType" SG_ 2158796800 ODII_ODIInd8 "BLN";
BA_ "PacketOrder" SG_ 2158796800 ODII_ODIInd8 9;
BA_ "SignalLongName" SG_ 2158796800 ODII_ODIInd8 "Open Display Interface Indication : Open Display Interface Indication 8";
BA_ "GenSigSendOnInit" SG_ 2158796800 ODII_ODIInd7 1;
BA_ "GenSigSendType" SG_ 2158796800 ODII_ODIInd7 10;
BA_ "VNSigAllNodes" SG_ 2158796800 ODII_ODIInd7 1;
BA_ "SignalType" SG_ 2158796800 ODII_ODIInd7 "BLN";
BA_ "PacketOrder" SG_ 2158796800 ODII_ODIInd7 8;
BA_ "SignalLongName" SG_ 2158796800 ODII_ODIInd7 "Open Display Interface Indication : Open Display Interface Indication 7";
BA_ "GenSigSendOnInit" SG_ 2158796800 ODII_ODIInd6 1;
BA_ "GenSigSendType" SG_ 2158796800 ODII_ODIInd6 10;
BA_ "VNSigAllNodes" SG_ 2158796800 ODII_ODIInd6 1;
BA_ "SignalType" SG_ 2158796800 ODII_ODIInd6 "BLN";
BA_ "PacketOrder" SG_ 2158796800 ODII_ODIInd6 7;
BA_ "SignalLongName" SG_ 2158796800 ODII_ODIInd6 "Open Display Interface Indication : Open Display Interface Indication 6";
BA_ "GenSigSendOnInit" SG_ 2158796800 ODII_ODIInd5 1;
BA_ "GenSigSendType" SG_ 2158796800 ODII_ODIInd5 10;
BA_ "VNSigAllNodes" SG_ 2158796800 ODII_ODIInd5 1;
BA_ "SignalType" SG_ 2158796800 ODII_ODIInd5 "BLN";
BA_ "PacketOrder" SG_ 2158796800 ODII_ODIInd5 6;
BA_ "SignalLongName" SG_ 2158796800 ODII_ODIInd5 "Open Display Interface Indication : Open Display Interface Indication 5";
BA_ "GenSigSendOnInit" SG_ 2158796800 ODII_ODIInd4 1;
BA_ "GenSigSendType" SG_ 2158796800 ODII_ODIInd4 10;
BA_ "VNSigAllNodes" SG_ 2158796800 ODII_ODIInd4 1;
BA_ "SignalType" SG_ 2158796800 ODII_ODIInd4 "BLN";
BA_ "PacketOrder" SG_ 2158796800 ODII_ODIInd4 5;
BA_ "SignalLongName" SG_ 2158796800 ODII_ODIInd4 "Open Display Interface Indication : Open Display Interface Indication 4";
BA_ "GenSigSendOnInit" SG_ 2158796800 ODII_ODIInd3 1;
BA_ "GenSigSendType" SG_ 2158796800 ODII_ODIInd3 10;
BA_ "VNSigAllNodes" SG_ 2158796800 ODII_ODIInd3 1;
BA_ "SignalType" SG_ 2158796800 ODII_ODIInd3 "BLN";
BA_ "PacketOrder" SG_ 2158796800 ODII_ODIInd3 4;
BA_ "SignalLongName" SG_ 2158796800 ODII_ODIInd3 "Open Display Interface Indication : Open Display Interface Indication 3";
BA_ "GenSigSendOnInit" SG_ 2158796800 ODII_ODIInd2 1;
BA_ "GenSigSendType" SG_ 2158796800 ODII_ODIInd2 10;
BA_ "VNSigAllNodes" SG_ 2158796800 ODII_ODIInd2 1;
BA_ "SignalType" SG_ 2158796800 ODII_ODIInd2 "BLN";
BA_ "PacketOrder" SG_ 2158796800 ODII_ODIInd2 3;
BA_ "SignalLongName" SG_ 2158796800 ODII_ODIInd2 "Open Display Interface Indication : Open Display Interface Indication 2";
BA_ "GenSigSendOnInit" SG_ 2158796800 ODII_ODIInd1 1;
BA_ "GenSigSendType" SG_ 2158796800 ODII_ODIInd1 10;
BA_ "VNSigAllNodes" SG_ 2158796800 ODII_ODIInd1 1;
BA_ "SignalType" SG_ 2158796800 ODII_ODIInd1 "BLN";
BA_ "PacketOrder" SG_ 2158796800 ODII_ODIInd1 2;
BA_ "SignalLongName" SG_ 2158796800 ODII_ODIInd1 "Open Display Interface Indication : Open Display Interface Indication 1";
BA_ "GenSigSendOnInit" SG_ 2158796800 ODII_ODIInd56 1;
BA_ "GenSigSendType" SG_ 2158796800 ODII_ODIInd56 10;
BA_ "VNSigAllNodes" SG_ 2158796800 ODII_ODIInd56 1;
BA_ "SignalType" SG_ 2158796800 ODII_ODIInd56 "BLN";
BA_ "PacketOrder" SG_ 2158796800 ODII_ODIInd56 57;
BA_ "SignalLongName" SG_ 2158796800 ODII_ODIInd56 "Open Display Interface Indication : Open Display Interface Indication 56";
BA_ "GenSigSendOnInit" SG_ 2158796800 ODII_ODIInd49 1;
BA_ "GenSigSendType" SG_ 2158796800 ODII_ODIInd49 10;
BA_ "VNSigAllNodes" SG_ 2158796800 ODII_ODIInd49 1;
BA_ "SignalType" SG_ 2158796800 ODII_ODIInd49 "BLN";
BA_ "PacketOrder" SG_ 2158796800 ODII_ODIInd49 50;
BA_ "SignalLongName" SG_ 2158796800 ODII_ODIInd49 "Open Display Interface Indication : Open Display Interface Indication 49";
BA_ "GenSigSendOnInit" SG_ 2158796800 ODII_ODIInd48 1;
BA_ "GenSigSendType" SG_ 2158796800 ODII_ODIInd48 10;
BA_ "VNSigAllNodes" SG_ 2158796800 ODII_ODIInd48 1;
BA_ "SignalType" SG_ 2158796800 ODII_ODIInd48 "BLN";
BA_ "PacketOrder" SG_ 2158796800 ODII_ODIInd48 49;
BA_ "SignalLongName" SG_ 2158796800 ODII_ODIInd48 "Open Display Interface Indication : Open Display Interface Indication 48";
BA_ "GenSigSendOnInit" SG_ 2158796800 ODII_ODIInd47 1;
BA_ "GenSigSendType" SG_ 2158796800 ODII_ODIInd47 10;
BA_ "VNSigAllNodes" SG_ 2158796800 ODII_ODIInd47 1;
BA_ "SignalType" SG_ 2158796800 ODII_ODIInd47 "BLN";
BA_ "PacketOrder" SG_ 2158796800 ODII_ODIInd47 48;
BA_ "SignalLongName" SG_ 2158796800 ODII_ODIInd47 "Open Display Interface Indication : Open Display Interface Indication 47";
BA_ "GenSigSendOnInit" SG_ 2158796800 ODII_ODIInd46 1;
BA_ "GenSigSendType" SG_ 2158796800 ODII_ODIInd46 10;
BA_ "VNSigAllNodes" SG_ 2158796800 ODII_ODIInd46 1;
BA_ "SignalType" SG_ 2158796800 ODII_ODIInd46 "BLN";
BA_ "PacketOrder" SG_ 2158796800 ODII_ODIInd46 47;
BA_ "SignalLongName" SG_ 2158796800 ODII_ODIInd46 "Open Display Interface Indication : Open Display Interface Indication 46";
BA_ "GenSigSendOnInit" SG_ 2158796800 ODII_ODIInd45 1;
BA_ "GenSigSendType" SG_ 2158796800 ODII_ODIInd45 10;
BA_ "VNSigAllNodes" SG_ 2158796800 ODII_ODIInd45 1;
BA_ "SignalType" SG_ 2158796800 ODII_ODIInd45 "BLN";
BA_ "PacketOrder" SG_ 2158796800 ODII_ODIInd45 46;
BA_ "SignalLongName" SG_ 2158796800 ODII_ODIInd45 "Open Display Interface Indication : Open Display Interface Indication 45";
BA_ "GenSigSendOnInit" SG_ 2158796800 ODII_ODIInd44 1;
BA_ "GenSigSendType" SG_ 2158796800 ODII_ODIInd44 10;
BA_ "VNSigAllNodes" SG_ 2158796800 ODII_ODIInd44 1;
BA_ "SignalType" SG_ 2158796800 ODII_ODIInd44 "BLN";
BA_ "PacketOrder" SG_ 2158796800 ODII_ODIInd44 45;
BA_ "SignalLongName" SG_ 2158796800 ODII_ODIInd44 "Open Display Interface Indication : Open Display Interface Indication 44";
BA_ "GenSigSendOnInit" SG_ 2158796800 ODII_ODIInd43 1;
BA_ "GenSigSendType" SG_ 2158796800 ODII_ODIInd43 10;
BA_ "VNSigAllNodes" SG_ 2158796800 ODII_ODIInd43 1;
BA_ "SignalType" SG_ 2158796800 ODII_ODIInd43 "BLN";
BA_ "PacketOrder" SG_ 2158796800 ODII_ODIInd43 44;
BA_ "SignalLongName" SG_ 2158796800 ODII_ODIInd43 "Open Display Interface Indication : Open Display Interface Indication 43";
BA_ "GenSigSendOnInit" SG_ 2158796800 ODII_ODIInd42 1;
BA_ "GenSigSendType" SG_ 2158796800 ODII_ODIInd42 10;
BA_ "VNSigAllNodes" SG_ 2158796800 ODII_ODIInd42 1;
BA_ "SignalType" SG_ 2158796800 ODII_ODIInd42 "BLN";
BA_ "PacketOrder" SG_ 2158796800 ODII_ODIInd42 43;
BA_ "SignalLongName" SG_ 2158796800 ODII_ODIInd42 "Open Display Interface Indication : Open Display Interface Indication 42";
BA_ "GenSigSendOnInit" SG_ 2158796800 ODII_ODIInd41 1;
BA_ "GenSigSendType" SG_ 2158796800 ODII_ODIInd41 10;
BA_ "VNSigAllNodes" SG_ 2158796800 ODII_ODIInd41 1;
BA_ "SignalType" SG_ 2158796800 ODII_ODIInd41 "BLN";
BA_ "PacketOrder" SG_ 2158796800 ODII_ODIInd41 42;
BA_ "SignalLongName" SG_ 2158796800 ODII_ODIInd41 "Open Display Interface Indication : Open Display Interface Indication 41";
BA_ "GenSigSendOnInit" SG_ 2158796800 ODII_ODIInd40 1;
BA_ "GenSigSendType" SG_ 2158796800 ODII_ODIInd40 10;
BA_ "VNSigAllNodes" SG_ 2158796800 ODII_ODIInd40 1;
BA_ "SignalType" SG_ 2158796800 ODII_ODIInd40 "BLN";
BA_ "PacketOrder" SG_ 2158796800 ODII_ODIInd40 41;
BA_ "SignalLongName" SG_ 2158796800 ODII_ODIInd40 "Open Display Interface Indication : Open Display Interface Indication 40";
BA_ "GenSigSendOnInit" SG_ 2158796800 ODII_ODIInd39 1;
BA_ "GenSigSendType" SG_ 2158796800 ODII_ODIInd39 10;
BA_ "VNSigAllNodes" SG_ 2158796800 ODII_ODIInd39 1;
BA_ "SignalType" SG_ 2158796800 ODII_ODIInd39 "BLN";
BA_ "PacketOrder" SG_ 2158796800 ODII_ODIInd39 40;
BA_ "SignalLongName" SG_ 2158796800 ODII_ODIInd39 "Open Display Interface Indication : Open Display Interface Indication 39";
BA_ "GenSigSendOnInit" SG_ 2158796800 ODII_ODIInd38 1;
BA_ "GenSigSendType" SG_ 2158796800 ODII_ODIInd38 10;
BA_ "VNSigAllNodes" SG_ 2158796800 ODII_ODIInd38 1;
BA_ "SignalType" SG_ 2158796800 ODII_ODIInd38 "BLN";
BA_ "PacketOrder" SG_ 2158796800 ODII_ODIInd38 39;
BA_ "SignalLongName" SG_ 2158796800 ODII_ODIInd38 "Open Display Interface Indication : Open Display Interface Indication 38";
BA_ "GenSigSendOnInit" SG_ 2158796800 ODII_ODIInd37 1;
BA_ "GenSigSendType" SG_ 2158796800 ODII_ODIInd37 10;
BA_ "VNSigAllNodes" SG_ 2158796800 ODII_ODIInd37 1;
BA_ "SignalType" SG_ 2158796800 ODII_ODIInd37 "BLN";
BA_ "PacketOrder" SG_ 2158796800 ODII_ODIInd37 38;
BA_ "SignalLongName" SG_ 2158796800 ODII_ODIInd37 "Open Display Interface Indication : Open Display Interface Indication 37";
BA_ "GenSigSendOnInit" SG_ 2158796800 ODII_ODIInd36 1;
BA_ "GenSigSendType" SG_ 2158796800 ODII_ODIInd36 10;
BA_ "VNSigAllNodes" SG_ 2158796800 ODII_ODIInd36 1;
BA_ "SignalType" SG_ 2158796800 ODII_ODIInd36 "BLN";
BA_ "PacketOrder" SG_ 2158796800 ODII_ODIInd36 37;
BA_ "SignalLongName" SG_ 2158796800 ODII_ODIInd36 "Open Display Interface Indication : Open Display Interface Indication 36";
BA_ "GenSigSendOnInit" SG_ 2158796800 ODII_ODIInd35 1;
BA_ "GenSigSendType" SG_ 2158796800 ODII_ODIInd35 10;
BA_ "VNSigAllNodes" SG_ 2158796800 ODII_ODIInd35 1;
BA_ "SignalType" SG_ 2158796800 ODII_ODIInd35 "BLN";
BA_ "PacketOrder" SG_ 2158796800 ODII_ODIInd35 36;
BA_ "SignalLongName" SG_ 2158796800 ODII_ODIInd35 "Open Display Interface Indication : Open Display Interface Indication 35";
BA_ "GenSigSendOnInit" SG_ 2158796800 ODII_ODIInd34 1;
BA_ "GenSigSendType" SG_ 2158796800 ODII_ODIInd34 10;
BA_ "VNSigAllNodes" SG_ 2158796800 ODII_ODIInd34 1;
BA_ "SignalType" SG_ 2158796800 ODII_ODIInd34 "BLN";
BA_ "PacketOrder" SG_ 2158796800 ODII_ODIInd34 35;
BA_ "SignalLongName" SG_ 2158796800 ODII_ODIInd34 "Open Display Interface Indication : Open Display Interface Indication 34";
BA_ "GenSigSendOnInit" SG_ 2158796800 ODII_ODIInd33 1;
BA_ "GenSigSendType" SG_ 2158796800 ODII_ODIInd33 10;
BA_ "VNSigAllNodes" SG_ 2158796800 ODII_ODIInd33 1;
BA_ "SignalType" SG_ 2158796800 ODII_ODIInd33 "BLN";
BA_ "PacketOrder" SG_ 2158796800 ODII_ODIInd33 34;
BA_ "SignalLongName" SG_ 2158796800 ODII_ODIInd33 "Open Display Interface Indication : Open Display Interface Indication 33";
BA_ "GenSigSendOnInit" SG_ 2158796800 ODII_ODIInd32 1;
BA_ "GenSigSendType" SG_ 2158796800 ODII_ODIInd32 10;
BA_ "VNSigAllNodes" SG_ 2158796800 ODII_ODIInd32 1;
BA_ "SignalType" SG_ 2158796800 ODII_ODIInd32 "BLN";
BA_ "PacketOrder" SG_ 2158796800 ODII_ODIInd32 33;
BA_ "SignalLongName" SG_ 2158796800 ODII_ODIInd32 "Open Display Interface Indication : Open Display Interface Indication 32";
BA_ "GenSigSendOnInit" SG_ 2158796800 ODII_ODIInd31 1;
BA_ "GenSigSendType" SG_ 2158796800 ODII_ODIInd31 10;
BA_ "VNSigAllNodes" SG_ 2158796800 ODII_ODIInd31 1;
BA_ "SignalType" SG_ 2158796800 ODII_ODIInd31 "BLN";
BA_ "PacketOrder" SG_ 2158796800 ODII_ODIInd31 32;
BA_ "SignalLongName" SG_ 2158796800 ODII_ODIInd31 "Open Display Interface Indication : Open Display Interface Indication 31";
BA_ "GenSigSendOnInit" SG_ 2158796800 ODII_ODIInd30 1;
BA_ "GenSigSendType" SG_ 2158796800 ODII_ODIInd30 10;
BA_ "VNSigAllNodes" SG_ 2158796800 ODII_ODIInd30 1;
BA_ "SignalType" SG_ 2158796800 ODII_ODIInd30 "BLN";
BA_ "PacketOrder" SG_ 2158796800 ODII_ODIInd30 31;
BA_ "SignalLongName" SG_ 2158796800 ODII_ODIInd30 "Open Display Interface Indication : Open Display Interface Indication 30";
BA_ "GenSigSendOnInit" SG_ 2158796800 ODII_ODIInd29 1;
BA_ "GenSigSendType" SG_ 2158796800 ODII_ODIInd29 10;
BA_ "VNSigAllNodes" SG_ 2158796800 ODII_ODIInd29 1;
BA_ "SignalType" SG_ 2158796800 ODII_ODIInd29 "BLN";
BA_ "PacketOrder" SG_ 2158796800 ODII_ODIInd29 30;
BA_ "SignalLongName" SG_ 2158796800 ODII_ODIInd29 "Open Display Interface Indication : Open Display Interface Indication 29";
BA_ "GenSigSendOnInit" SG_ 2158796800 ODII_ODIInd28 1;
BA_ "GenSigSendType" SG_ 2158796800 ODII_ODIInd28 10;
BA_ "VNSigAllNodes" SG_ 2158796800 ODII_ODIInd28 1;
BA_ "SignalType" SG_ 2158796800 ODII_ODIInd28 "BLN";
BA_ "PacketOrder" SG_ 2158796800 ODII_ODIInd28 29;
BA_ "SignalLongName" SG_ 2158796800 ODII_ODIInd28 "Open Display Interface Indication : Open Display Interface Indication 28";
BA_ "GenSigSendOnInit" SG_ 2158796800 ODII_FUCID 1;
BA_ "GenSigSendType" SG_ 2158796800 ODII_FUCID 12;
BA_ "GenSigDeltaValue" SG_ 2158796800 ODII_FUCID 1;
BA_ "VNSigAllNodes" SG_ 2158796800 ODII_FUCID 1;
BA_ "SignalType" SG_ 2158796800 ODII_FUCID "UNM";
BA_ "PacketOrder" SG_ 2158796800 ODII_FUCID 1;
BA_ "SignalLongName" SG_ 2158796800 ODII_FUCID "Open Display Interface Indication : Functional Unit Class ID";
BA_REL_ "GenSigSuprvResp" BU_SG_REL_ BCM_LS SG_ 2149826560 SpdLmtVsnFsdSpdUnt 1;
BA_REL_ "GenSigSuprvResp" BU_SG_REL_ BCM_LS SG_ 2149826560 SpdLmtVnFsSpdNwDet 1;
BA_REL_ "GenSigSuprvResp" BU_SG_REL_ BCM_LS SG_ 2149826560 SpdLmtVsnFsdSpd 1;
BA_REL_ "GenSigSuprvResp" BU_SG_REL_ BCM_LS SG_ 2149826560 FOAI_VehAhdIndRq11E 1;
BA_REL_ "GenSigSuprvResp" BU_SG_REL_ BCM_LS SG_ 2149826560 FOAI_AlrtWrnIndRq11E 1;
BA_REL_ "GenSigSuprvResp" BU_SG_REL_ BCM_LS SG_ 2149826560 FOAI_AlrtChmIhbRq11E 1;
BA_REL_ "GenSigSuprvResp" BU_SG_REL_ MSM_LS SG_ 2151997440 DrvDrsnHptcStRqSeqN 1;
BA_REL_ "GenSigSuprvResp" BU_SG_REL_ BCM_LS SG_ 2151997440 DrvDrowSysIndRq 1;
BA_REL_ "GenSigSuprvResp" BU_SG_REL_ MSM_LS SG_ 2151997440 DrDrwSysHptcStVbnRq 1;
BA_REL_ "GenSigSuprvResp" BU_SG_REL_ BCM_LS SG_ 2151997440 DrDrwSysHptcStVbnRq 1;
BA_REL_ "GenSigSuprvResp" BU_SG_REL_ BCM_LS SG_ 2156331008 LwRngLVLdShdRq 1;
BA_REL_ "GenSigSuprvResp" BU_SG_REL_ BCM_LS SG_ 2150375424 USBProgInPrgrs 1;
BA_REL_ "GenSigSuprvResp" BU_SG_REL_ BCM_LS SG_ 2150375424 DsplTrnsShftLvrLckRqd 1;
BA_REL_ "GenSigSuprvResp" BU_SG_REL_ BCM_LS SG_ 2158149632 HVBatTmBsChrgStRsp 1;
BA_REL_ "GenSigSuprvResp" BU_SG_REL_ BCM_LS SG_ 2150547456 HVBatChrgCrdConnIO 1;
BA_REL_ "GenSigSuprvResp" BU_SG_REL_ BCM_LS SG_ 2149728256 PrtyChrgStPnt 1;
BA_REL_ "GenSigSuprvResp" BU_SG_REL_ BCM_LS SG_ 2149728256 PrtyChrgActIO 1;
BA_REL_ "GenSigSuprvResp" BU_SG_REL_ BCM_LS SG_ 2149728256 PrtyChrgAct 1;
BA_REL_ "GenSigSuprvResp" BU_SG_REL_ BCM_LS SG_ 2149728256 HVChrgPwrLvl 1;
BA_REL_ "GenSigSuprvResp" BU_SG_REL_ VIS2_LS SG_ 2150891520 DgtlMapEffSpdLmt 1;
BA_REL_ "GenSigSuprvResp" BU_SG_REL_ VIS2_LS SG_ 2150891520 DgtlMapEffSpdLmtTyp 1;
BA_REL_ "GenSigSuprvResp" BU_SG_REL_ VIS2_LS SG_ 2150891520 DgtlMapSpdCat 1;
BA_REL_ "GenSigSuprvResp" BU_SG_REL_ VIS2_LS SG_ 2150891520 DgtlMapVerQtr 1;
BA_REL_ "GenSigSuprvResp" BU_SG_REL_ VIS2_LS SG_ 2150891520 DgtlMapVerYr 1;
BA_REL_ "GenSigSuprvResp" BU_SG_REL_ VIS2_LS SG_ 2150891520 DgtlMapDrvngSd 1;
BA_REL_ "GenSigSuprvResp" BU_SG_REL_ BCM_LS SG_ 2155536384 RevClnMtgnBrkReqAct 1;
BA_REL_ "GenSigSuprvResp" BU_SG_REL_ MSM_LS SG_ 2151415808 RgtLnChgThrtHptStRqSN 1;
BA_REL_ "GenSigSuprvResp" BU_SG_REL_ MSM_LS SG_ 2151415808 RgtLnChgThrtHptStRq 1;
BA_REL_ "GenSigSuprvResp" BU_SG_REL_ MSM_LS SG_ 2151415808 LftLnChgThrtHptStRqSN 1;
BA_REL_ "GenSigSuprvResp" BU_SG_REL_ MSM_LS SG_ 2151415808 LftLnChgThrtHptStRq 1;
BA_REL_ "GenSigSuprvResp" BU_SG_REL_ MSM_LS SG_ 2151415808 LDWRghtHptcStRqSN 1;
BA_REL_ "GenSigSuprvResp" BU_SG_REL_ MSM_LS SG_ 2151415808 LDWLftHptcStRqSN 1;
BA_REL_ "GenSigSuprvResp" BU_SG_REL_ MSM_LS SG_ 2151415808 LDWRghtHptcStRq 1;
BA_REL_ "GenSigSuprvResp" BU_SG_REL_ BCM_LS SG_ 2151415808 LDWRghtHptcStRq 1;
BA_REL_ "GenSigSuprvResp" BU_SG_REL_ MSM_LS SG_ 2151415808 LDWLftHptcStRq 1;
BA_REL_ "GenSigSuprvResp" BU_SG_REL_ BCM_LS SG_ 2151415808 LDWLftHptcStRq 1;
BA_REL_ "GenSigSuprvResp" BU_SG_REL_ BSM_LS SG_ 2151522304 ElEngyEconAvgRstRq 1;
BA_REL_ "GenSigSuprvResp" BU_SG_REL_ BCM_LS SG_ 2151505920 AutoMdSpdLmtCnfrmd 1;
BA_REL_ "GenSigSuprvResp" BU_SG_REL_ VIS2_LS SG_ 2151505920 ACCSettingType 1;
BA_REL_ "GenSigSuprvResp" BU_SG_REL_ BCM_LS SG_ 2151505920 ACCSettingType 1;
BA_REL_ "GenSigSuprvResp" BU_SG_REL_ BCM_LS SG_ 2151505920 TrlrBrkDsplyAct 1;
BA_REL_ "GenSigSuprvResp" BU_SG_REL_ BCM_LS SG_ 2150006784 SysPwrMdPshbtnAct 1;
BA_REL_ "GenSigSuprvResp" BU_SG_REL_ UPA_LS SG_ 2158911488 ODDMC_ReqType 1;
BA_REL_ "GenSigSuprvResp" BU_SG_REL_ EOCM_F_LS SG_ 2158911488 ODDMC_ReqType 1;
BA_REL_ "GenSigSuprvResp" BU_SG_REL_ UPA_LS SG_ 2158911488 ODDMC_DispMID 1;
BA_REL_ "GenSigSuprvResp" BU_SG_REL_ EOCM_F_LS SG_ 2158911488 ODDMC_DispMID 1;
BA_REL_ "GenSigSuprvResp" BU_SG_REL_ UPA_LS SG_ 2158911488 ODDMC_DataID2Vld 1;
BA_REL_ "GenSigSuprvResp" BU_SG_REL_ EOCM_F_LS SG_ 2158911488 ODDMC_DataID2Vld 1;
BA_REL_ "GenSigSuprvResp" BU_SG_REL_ UPA_LS SG_ 2158911488 ODDMC_DataID2 1;
BA_REL_ "GenSigSuprvResp" BU_SG_REL_ EOCM_F_LS SG_ 2158911488 ODDMC_DataID2 1;
BA_REL_ "GenSigSuprvResp" BU_SG_REL_ UPA_LS SG_ 2158911488 ODDMC_DataID3Vld 1;
BA_REL_ "GenSigSuprvResp" BU_SG_REL_ EOCM_F_LS SG_ 2158911488 ODDMC_DataID3Vld 1;
BA_REL_ "GenSigSuprvResp" BU_SG_REL_ UPA_LS SG_ 2158911488 ODDMC_DataID3 1;
BA_REL_ "GenSigSuprvResp" BU_SG_REL_ EOCM_F_LS SG_ 2158911488 ODDMC_DataID3 1;
BA_REL_ "GenSigSuprvResp" BU_SG_REL_ UPA_LS SG_ 2158911488 ODDMC_DataID1 1;
BA_REL_ "GenSigSuprvResp" BU_SG_REL_ EOCM_F_LS SG_ 2158911488 ODDMC_DataID1 1;
BA_REL_ "GenSigSuprvResp" BU_SG_REL_ UPA_LS SG_ 2158911488 ODDMC_DataID4Vld 1;
BA_REL_ "GenSigSuprvResp" BU_SG_REL_ EOCM_F_LS SG_ 2158911488 ODDMC_DataID4Vld 1;
BA_REL_ "GenSigSuprvResp" BU_SG_REL_ UPA_LS SG_ 2158911488 ODDMC_DataID4 1;
BA_REL_ "GenSigSuprvResp" BU_SG_REL_ EOCM_F_LS SG_ 2158911488 ODDMC_DataID4 1;
BA_REL_ "GenSigSuprvResp" BU_SG_REL_ UPA_LS SG_ 2158911488 ODDMC_DataID5Vld 1;
BA_REL_ "GenSigSuprvResp" BU_SG_REL_ EOCM_F_LS SG_ 2158911488 ODDMC_DataID5Vld 1;
BA_REL_ "GenSigSuprvResp" BU_SG_REL_ UPA_LS SG_ 2158911488 ODDMC_DataID5 1;
BA_REL_ "GenSigSuprvResp" BU_SG_REL_ EOCM_F_LS SG_ 2158911488 ODDMC_DataID5 1;
BA_REL_ "GenSigSuprvResp" BU_SG_REL_ UPA_LS SG_ 2158911488 ODDMC_FUCID 1;
BA_REL_ "GenSigSuprvResp" BU_SG_REL_ EOCM_F_LS SG_ 2158911488 ODDMC_FUCID 1;
BA_REL_ "GenSigSuprvResp" BU_SG_REL_ UPA_LS SG_ 2158919680 ODDMI_ReqType 1;
BA_REL_ "GenSigSuprvResp" BU_SG_REL_ EOCM_F_LS SG_ 2158919680 ODDMI_ReqType 1;
BA_REL_ "GenSigSuprvResp" BU_SG_REL_ UPA_LS SG_ 2158919680 ODDMI_FUCID 1;
BA_REL_ "GenSigSuprvResp" BU_SG_REL_ EOCM_F_LS SG_ 2158919680 ODDMI_FUCID 1;
BA_REL_ "GenSigSuprvResp" BU_SG_REL_ UPA_LS SG_ 2158919680 ODDMI_DispMID 1;
BA_REL_ "GenSigSuprvResp" BU_SG_REL_ EOCM_F_LS SG_ 2158919680 ODDMI_DispMID 1;
BA_REL_ "GenSigSuprvResp" BU_SG_REL_ UPA_LS SG_ 2158919680 ODDMI_DataID2Vld 1;
BA_REL_ "GenSigSuprvResp" BU_SG_REL_ EOCM_F_LS SG_ 2158919680 ODDMI_DataID2Vld 1;
BA_REL_ "GenSigSuprvResp" BU_SG_REL_ UPA_LS SG_ 2158919680 ODDMI_DataID2 1;
BA_REL_ "GenSigSuprvResp" BU_SG_REL_ EOCM_F_LS SG_ 2158919680 ODDMI_DataID2 1;
BA_REL_ "GenSigSuprvResp" BU_SG_REL_ UPA_LS SG_ 2158919680 ODDMI_DataID3Vld 1;
BA_REL_ "GenSigSuprvResp" BU_SG_REL_ EOCM_F_LS SG_ 2158919680 ODDMI_DataID3Vld 1;
BA_REL_ "GenSigSuprvResp" BU_SG_REL_ UPA_LS SG_ 2158919680 ODDMI_DataID3 1;
BA_REL_ "GenSigSuprvResp" BU_SG_REL_ EOCM_F_LS SG_ 2158919680 ODDMI_DataID3 1;
BA_REL_ "GenSigSuprvResp" BU_SG_REL_ UPA_LS SG_ 2158919680 ODDMI_DataID1 1;
BA_REL_ "GenSigSuprvResp" BU_SG_REL_ EOCM_F_LS SG_ 2158919680 ODDMI_DataID1 1;
BA_REL_ "GenSigSuprvResp" BU_SG_REL_ UPA_LS SG_ 2158919680 ODDMI_DataID4Vld 1;
BA_REL_ "GenSigSuprvResp" BU_SG_REL_ EOCM_F_LS SG_ 2158919680 ODDMI_DataID4Vld 1;
BA_REL_ "GenSigSuprvResp" BU_SG_REL_ UPA_LS SG_ 2158919680 ODDMI_DataID4 1;
BA_REL_ "GenSigSuprvResp" BU_SG_REL_ EOCM_F_LS SG_ 2158919680 ODDMI_DataID4 1;
BA_REL_ "GenSigSuprvResp" BU_SG_REL_ UPA_LS SG_ 2158919680 ODDMI_DataID5Vld 1;
BA_REL_ "GenSigSuprvResp" BU_SG_REL_ EOCM_F_LS SG_ 2158919680 ODDMI_DataID5Vld 1;
BA_REL_ "GenSigSuprvResp" BU_SG_REL_ UPA_LS SG_ 2158919680 ODDMI_DataID5 1;
BA_REL_ "GenSigSuprvResp" BU_SG_REL_ EOCM_F_LS SG_ 2158919680 ODDMI_DataID5 1;
BA_REL_ "GenSigSuprvResp" BU_SG_REL_ UPA_LS SG_ 2151825408 OtsAirTmp 1;
BA_REL_ "GenSigVBitResp" BU_SG_REL_ UPA_LS SG_ 2151825408 OtsAirTmp 1;
BA_REL_ "GenSigSuprvResp" BU_SG_REL_ HFP_LS SG_ 2151825408 OtsAirTmp 1;
BA_REL_ "GenSigSuprvResp" BU_SG_REL_ UPA_LS SG_ 2151825408 OtsAirTmpCrVal 1;
BA_REL_ "GenSigSuprvResp" BU_SG_REL_ VIS2_LS SG_ 2151825408 OtsAirTmpCrVal 1;
BA_REL_ "GenSigSuprvResp" BU_SG_REL_ SDM_LS SG_ 2151825408 OtsAirTmpCrVal 1;
BA_REL_ "GenSigSuprvResp" BU_SG_REL_ EOCM_F_LS SG_ 2151825408 OtsAirTmpCrVal 1;
BA_REL_ "GenSigSuprvResp" BU_SG_REL_ BCM_LS SG_ 2151825408 OtsAirTmpCrVal 1;
BA_REL_ "GenSigVBitResp" BU_SG_REL_ BCM_LS SG_ 2151825408 OtsAirTmpCrVal 1;
BA_REL_ "GenSigSuprvResp" BU_SG_REL_ VIS2_LS SG_ 2149711872 AutoMdSpdLmtStat 1;
BA_REL_ "GenSigSuprvResp" BU_SG_REL_ VIS2_LS SG_ 2149711872 ACCAutoSetSpdStat 1;
BA_REL_ "GenSigSuprvResp" BU_SG_REL_ SBZA_R_LS SG_ 2149711872 VehDynYawRate 1;
BA_REL_ "GenSigSuprvResp" BU_SG_REL_ SBZA_L_LS SG_ 2149711872 VehDynYawRate 1;
BA_REL_ "GenSigSuprvResp" BU_SG_REL_ UPA_LS SG_ 2149711872 VehDynYawRate 1;
BA_REL_ "GenSigVDAFailResp" BU_SG_REL_ UPA_LS SG_ 2149711872 VehDynYawRate 1;
BA_REL_ "GenSigVDAFailComment" BU_SG_REL_ UPA_LS SG_ 2149711872 VehDynYawRate "Brake System Virtual Device Availability";
BA_REL_ "GenSigVBitResp" BU_SG_REL_ UPA_LS SG_ 2149711872 VehDynYawRate 1;
BA_REL_ "GenSigSuprvResp" BU_SG_REL_ VIS2_LS SG_ 2149711872 ACCAct370 1;
BA_REL_ "GenSigSuprvResp" BU_SG_REL_ UPA_LS SG_ 2162982912 VehIdNmDig10_17 1;
BA_REL_ "GenSigSuprvResp" BU_SG_REL_ SDM_LS SG_ 2162982912 VehIdNmDig10_17 1;
BA_REL_ "GenSigSuprvResp" BU_SG_REL_ EOCM_F_LS SG_ 2162982912 VehIdNmDig10_17 1;
BA_REL_ "GenSigSuprvResp" BU_SG_REL_ UPA_LS SG_ 2162966528 VehIdNmDig2_9 1;
BA_REL_ "GenSigSuprvResp" BU_SG_REL_ SDM_LS SG_ 2162966528 VehIdNmDig2_9 1;
BA_REL_ "GenSigSuprvResp" BU_SG_REL_ EOCM_F_LS SG_ 2162966528 VehIdNmDig2_9 1;
BA_REL_ "GenSigSuprvResp" BU_SG_REL_ UPA_LS SG_ 2158854144 ODIAI_DaTy 1;
BA_REL_ "GenSigSuprvResp" BU_SG_REL_ EOCM_F_LS SG_ 2158854144 ODIAI_DaTy 1;
BA_REL_ "GenSigSuprvResp" BU_SG_REL_ UPA_LS SG_ 2158854144 ODIAI_FUCID 1;
BA_REL_ "GenSigSuprvResp" BU_SG_REL_ EOCM_F_LS SG_ 2158854144 ODIAI_FUCID 1;
BA_REL_ "GenSigSuprvResp" BU_SG_REL_ UPA_LS SG_ 2158854144 ODIAI_DspMID 1;
BA_REL_ "GenSigSuprvResp" BU_SG_REL_ EOCM_F_LS SG_ 2158854144 ODIAI_DspMID 1;
BA_REL_ "GenSigSuprvResp" BU_SG_REL_ UPA_LS SG_ 2158854144 ODIAI_ActnVal 1;
BA_REL_ "GenSigSuprvResp" BU_SG_REL_ EOCM_F_LS SG_ 2158854144 ODIAI_ActnVal 1;
BA_REL_ "GenSigSuprvResp" BU_SG_REL_ UPA_LS SG_ 2158854144 ODIAI_ActnID 1;
BA_REL_ "GenSigSuprvResp" BU_SG_REL_ EOCM_F_LS SG_ 2158854144 ODIAI_ActnID 1;
BA_REL_ "GenSigSuprvResp" BU_SG_REL_ CGM_LS SG_ 2149629952 RtTrnLmpOn 1;
BA_REL_ "GenSigSuprvResp" BU_SG_REL_ CGM_LS SG_ 2149629952 LftTrnLmpOn 1;
BA_REL_ "GenSigSuprvResp" BU_SG_REL_ EOCM_F_LS SG_ 2149629952 FrFogLmpsAct 1;
BA_REL_ "GenSigSuprvResp" BU_SG_REL_ EOCM_F_LS SG_ 2149629952 HiBmReqd 1;
BA_REL_ "GenSigSuprvResp" BU_SG_REL_ EOCM_F_LS SG_ 2149629952 MainLghtSw 1;
BA_REL_ "GenSigSuprvResp" BU_SG_REL_ EOCM_F_LS SG_ 2149629952 HdlmpBmSelectStat 1;
BA_REL_ "GenSigSuprvResp" BU_SG_REL_ VIS2_LS SG_ 2149629952 HdlmpBmSelectStat 1;
BA_REL_ "GenSigSuprvResp" BU_SG_REL_ EOCM_F_LS SG_ 2149629952 SrvlnceMdAct 1;
BA_REL_ "GenSigSuprvResp" BU_SG_REL_ EOCM_F_LS SG_ 2149629952 RrFogLmpsAct 1;
BA_REL_ "GenSigSuprvResp" BU_SG_REL_ EOCM_F_LS SG_ 2149629952 AutoBmSlctAllwd 1;
BA_REL_ "GenSigSuprvResp" BU_SG_REL_ VIS2_LS SG_ 2149629952 AutoBmSlctAllwd 1;
BA_REL_ "GenSigSuprvResp" BU_SG_REL_ EOCM_F_LS SG_ 2149629952 FlToPsSwAtv 1;
BA_REL_ "GenSigSuprvResp" BU_SG_REL_ VIS2_LS SG_ 2149629952 TrnSwAct 1;
BA_REL_ "GenSigSuprvResp" BU_SG_REL_ UPA_LS SG_ 2149629952 LftTrnLmpAtv 1;
BA_REL_ "GenSigSuprvResp" BU_SG_REL_ EOCM_F_LS SG_ 2149629952 LftTrnLmpAtv 1;
BA_REL_ "GenSigSuprvResp" BU_SG_REL_ UPA_LS SG_ 2149629952 RtTrnLmpAtv 1;
BA_REL_ "GenSigSuprvResp" BU_SG_REL_ EOCM_F_LS SG_ 2149629952 RtTrnLmpAtv 1;
BA_REL_ "GenSigSuprvResp" BU_SG_REL_ EOCM_F_LS SG_ 2149629952 OtsdAmbtLtLvlStat 1;
BA_REL_ "GenSigSuprvResp" BU_SG_REL_ VIS2_LS SG_ 2155028480 RgtLnChgThrt 1;
BA_REL_ "GenSigSuprvResp" BU_SG_REL_ EOCM_F_LS SG_ 2155028480 RgtLnChgThrt 1;
BA_REL_ "GenSigSuprvResp" BU_SG_REL_ EOCM_F_LS SG_ 2149941248 PrkAstRrObjSnsngAct 1;
BA_REL_ "GenSigSuprvResp" BU_SG_REL_ EOCM_F_LS SG_ 2149941248 PrkAstRrSysStatUnfltd 1;
BA_REL_ "GenSigSuprvResp" BU_SG_REL_ EOCM_F_LS SG_ 2149941248 PrkAstRrExtdDstUnfltd 1;
BA_REL_ "GenSigSuprvResp" BU_SG_REL_ EOCM_F_LS SG_ 2149941248 PrkAstFntnSnsDstrbdIO 1;
BA_REL_ "GenSigSuprvResp" BU_SG_REL_ EOCM_F_LS SG_ 2149941248 PrkAstFntnSnrsBlkd 1;
BA_REL_ "GenSigSuprvResp" BU_SG_REL_ EOCM_F_LS SG_ 2149941248 PrkAstFntnFld 1;
BA_REL_ "GenSigSuprvResp" BU_SG_REL_ EOCM_F_LS SG_ 2149941248 PrkAstFntnDsbldIO 1;
BA_REL_ "GenSigSuprvResp" BU_SG_REL_ EOCM_F_LS SG_ 2149941248 PrkAstFntnClnPrkAstIO 1;
BA_REL_ "GenSigSuprvResp" BU_SG_REL_ EOCM_F_LS SG_ 2149941248 ClsnMtgtnInhbtReqtd 1;
BA_REL_ "GenSigSuprvResp" BU_SG_REL_ EOCM_F_LS SG_ 2149941248 PARrRgn4ObjStatUnfltd 1;
BA_REL_ "GenSigSuprvResp" BU_SG_REL_ EOCM_F_LS SG_ 2149941248 PARrRgn3ObjStatUnfltd 1;
BA_REL_ "GenSigSuprvResp" BU_SG_REL_ EOCM_F_LS SG_ 2149941248 PARrRgn2ObjStatUnfltd 1;
BA_REL_ "GenSigSuprvResp" BU_SG_REL_ EOCM_F_LS SG_ 2149941248 PARrRgn1ObjStatUnfltd 1;
BA_REL_ "GenSigSuprvResp" BU_SG_REL_ MSM_LS SG_ 2151350272 FPAHptcStVbnRqSeqN 1;
BA_REL_ "GenSigSuprvResp" BU_SG_REL_ MSM_LS SG_ 2151350272 FPAHptcStVbnReq 1;
BA_REL_ "GenSigSuprvResp" BU_SG_REL_ MSM_LS SG_ 2151333888 RPAHptcStVbRqSeqN 1;
BA_REL_ "GenSigSuprvResp" BU_SG_REL_ MSM_LS SG_ 2151333888 RPAHptcStVbnReq 1;
VAL_ 2149826560 TrfcSgnMmryIcePosIO 1 "true" 0 "false" ;
VAL_ 2149826560 FwdClnAlrtOffIO11E 1 "true" 0 "false" ;
VAL_ 2149826560 FwdClnAlrtPr11E 1 "true" 0 "false" ;
VAL_ 2149826560 FCAHdwyStngIO 1 "true" 0 "false" ;
VAL_ 2149826560 FCAGpStng 0 "Off" 1 "Near" 2 "Medium" 3 "Reserved3" 4 "Reserved4" 5 "Reserved5" 6 "Reserved6" 7 "Far" ;
VAL_ 2149826560 SpdLmtVsnFsdSpdUnt 0 "km/h" 1 "mph" ;
VAL_ 2149826560 SpdLmtVnFsSpdNwDet 1 "true" 0 "false" ;
VAL_ 2149826560 SpdLmtVsnFsdSpdM 0 "Don't Use Data" 1 "Use Data" ;
VAL_ 2149826560 FOAI_VehAhdIndRq11E 0 "No Alert" 1 "Alert Level 1" 2 "Alert Level 2" 3 "Alert Level 3" ;
VAL_ 2149826560 FOAI_AlrtWrnIndRq11E 0 "No Alert" 1 "Alert Level 1" 2 "Alert Level 2" 3 "Alert Level 3" ;
VAL_ 2149826560 FOAI_AlrtChmIhbRq11E 0 "Allow Chime" 1 "Inhibit Chime" ;
VAL_ 2149826560 FCABrkPrflReq 1 "true" 0 "false" ;
VAL_ 2149826560 FCACrusCtrlCnclReqd 1 "true" 0 "false" ;
VAL_ 2151997440 DrvDrwDetCsCrStVal 0 "No Action" 1 "Off" 2 "On" 3 "Reserved1" 4 "Reserved2" 5 "Reserved3" 6 "Reserved4" 7 "Reserved5" ;
VAL_ 2151997440 DrvDrowDetCstStAvl 1 "true" 0 "false" ;
VAL_ 2151997440 DrvDrowSysIndRq 0 "No Indication" 1 "Continuous Indication" 2 "Flashing Indication With Chime" 3 "Flashing Indication Without Chime" 4 "Reserved1" 5 "Reserved2" 6 "Reserved3" 7 "Reserved4" ;
VAL_ 2156331008 EUSD_MsrmntUnit 3 "Unused and Reserved 1" 2 "Unitless Score" 1 "km" 0 "No Action" ;
VAL_ 2156331008 LwRngLVLdShdRq 0 "No Load Shedding" 1 "Load Shed Level1" 2 "Load Shed Level2" 3 "Load Shed Level3" ;
VAL_ 2150375424 HVBChrgOvrdBtnDspReq 2 "Do Not Display Charge Override Button" 1 "Display Charge Override Button" 0 "No Action" ;
VAL_ 2150375424 HVBChrgLmtBtnDspReq 2 "Do Not Display Charge Limit Button" 1 "Display Charge Limit Button" 0 "No Action" ;
VAL_ 2150375424 HVBHmChrgTmDspReq 4 "Display Master Setting" 3 "Display Both Cord and Station" 2 "Display Charge Station Charge Value" 1 "Display Portable Cord Charge Value" 0 "No Action" ;
VAL_ 2150375424 HVBChrgTmDspReq 3 "Display Both Cord and Station" 2 "Display Charge Station Charge Value" 1 "Display Portable Cord Charge Value" 0 "No Action" ;
VAL_ 2150375424 LBCCsStReq 2 "On" 1 "Off" 0 "No Action" ;
VAL_ 2150375424 LBCPosMdfcReq 4 "Store Position 4" 3 "Store Position 3" 2 "Store Position 2" 1 "Store Position 1" 0 "No Action" ;
VAL_ 2150375424 LBCCDRR_ClrStrdPosReq 2 "Confirmation to Clear Position" 1 "Request to Clear Position" 0 "No Action" ;
VAL_ 2150375424 LBCCDRR_PosNum 4 "Position Number 4" 3 "Position Number 3" 2 "Position Number 2" 1 "Position Number 1" 0 "No Action" ;
VAL_ 2150375424 EngyCnsHistGrphRstRq 1 "true" 0 "false" ;
VAL_ 2150375424 EngAstHtPlgInCstStRq 0 "No Action" 1 "Off" 2 "On" ;
VAL_ 2150375424 EngAstHtCstStRq 3 "Off" 0 "No Action" 1 "On" 2 "Deferred" ;
VAL_ 2150375424 MntnceMdStEngRq 1 "true" 0 "false" ;
VAL_ 2150375424 USBProgInPrgrs 1 "true" 0 "false" ;
VAL_ 2150375424 DsplTrnsShftLvrLckRqd 1 "true" 0 "false" ;
VAL_ 2158149632 ECHGCD_XAxTkMrkInterv 7 "100" 6 "80" 5 "50" 4 "20" 3 "10" 2 "5" 1 "1" 0 "0.5" ;
VAL_ 2158149632 ECHGCD_MeasUt 15 "Unused and Reserved 7" 14 "Unused and Reserved 6" 13 "Unused and Reserved 5" 12 "Unused and Reserved 4" 11 "Unused and Reserved 3" 10 "Unused and Reserved 2" 9 "Unused and  Reserved 1" 8 "km per L e Combined" 7 "L per 100km e Combined" 6 "MPGe Combined" 5 "L per 100km" 4 "mi per gal" 3 "km per L" 2 "kWh per 100km" 1 "mi per kWh" 0 "km per kWh" ;
VAL_ 2158149632 HVBTBSCR_SsnStat 3 "Yearly" 0 "No Action" 1 "Summer" 2 "Winter" ;
VAL_ 2158149632 HVBTBSCR_SsnSlctStat 0 "No Action" 1 "Selected Season" 2 "Start Season" 3 "End Season" ;
VAL_ 2158149632 HVBTBSCR_SsnMthStat 0 "No Action" 1 "January" 2 "February" 3 "Mars" 4 "April" 5 "May" 6 "June" 7 "July" 8 "August" 9 "September" 10 "October" 11 "November" 12 "December" ;
VAL_ 2158149632 HVBTBCRS_ChRtDStat 0 "No Action" 1 "Sunday" 2 "Monday" 3 "Tuesday" 4 "Wednsday" 5 "Thursday" 6 "Friday" 7 "Saturday" 8 "All Days Same" 9 "Mon - Fri Same" 10 "Sat & Sun Same" ;
VAL_ 2158149632 HVBTBCRS_ChRtSlctStat 0 "No Action" 1 "Low Rate" 2 "Medium Rate" 3 "High Rate" ;
VAL_ 2158149632 HVBTBCRS_ChRtEnblStat 0 "No Action" 1 "Enabled" 2 "Disabled" ;
VAL_ 2158149632 HVBatTmBsChrgStRsp 0 "No Action" 1 "Charge Now" 2 "Delayed Charge" 3 "Rate Based Charge" ;
VAL_ 2158149632 HVBatCrgDspStat 0 "Inactive" 1 "Pending" 2 "Active Charging" 3 "Complete" 4 "Faulted" ;
VAL_ 2150113280 HVChrgInhbRsn 3 "See Charging Station" 2 "Charge Cord Lock Not Engaged" 1 "Charge Cord Not Fully Inserted" 0 "No Action" ;
VAL_ 2150113280 EngyStgSysActCoolEnb 1 "true" 0 "false" ;
VAL_ 2150547456 OffBrdHVCVehPwrLvl 0 "None" 1 "Low" 2 "Medium" 3 "High" ;
VAL_ 2150547456 OffBrdHVCVehPwrDrtd 1 "true" 0 "false" ;
VAL_ 2150547456 OffBrdHVCVehCplrLkd 1 "true" 0 "false" ;
VAL_ 2150547456 OffBrdHVBlkChrgCmp 1 "true" 0 "false" ;
VAL_ 2150547456 ElecPrplsnMtrOvrSpdIO 1 "true" 0 "false" ;
VAL_ 2150547456 HVBatOutOfEnrgyInd 0 "No Action" 1 "Charge Vehicle Soon" 2 "Charge Vehicle Now" 3 "Out of Energy" ;
VAL_ 2150547456 CntrsOpnUndrTmpIO 1 "true" 0 "false" ;
VAL_ 2150547456 HVBatCntctrsOpnIO 1 "true" 0 "false" ;
VAL_ 2150547456 GrnAudQueReq 1 "true" 0 "false" ;
VAL_ 2150547456 SvcHybChrgSysIO 1 "true" 0 "false" ;
VAL_ 2150547456 HVChrgrSysStat 0 "Default" 1 "Idle" 2 "Initializing" 3 "Active" 4 "Complete" 5 "Aborted" ;
VAL_ 2150547456 HVChrgrCplrStat 0 "No Action" 1 "Disconnected" 2 "Connected" ;
VAL_ 2150547456 HVBatLimDTmpInd 0 "Normal" 1 "Cold" 2 "Hot" ;
VAL_ 2150547456 VehChrgMdSt 0 "Charge Depletion" 1 "Hold Charge Sustaining" 2 "Low SOC Charge Sustaining" ;
VAL_ 2150547456 HVBatChrgCrdConnIO 1 "true" 0 "false" ;
VAL_ 2150547456 ChgrSysAdblIndReq 0 "Inactive" 1 "Sequence 1" 2 "Sequence 2" 3 "Sequence 3" ;
VAL_ 2149728256 EngAstHtPlgInCsStAvl 1 "true" 0 "false" ;
VAL_ 2149728256 EngAstHtPlgInCsCrStVl 0 "No Action" 1 "Off" 2 "On" ;
VAL_ 2149728256 EngAstHtCsStAvl 1 "true" 0 "false" ;
VAL_ 2149728256 EngAstHtCsCrStVal 3 "Off" 0 "No Action" 1 "On" 2 "Deferred" ;
VAL_ 2149728256 HghVltgPropState 0 "Generator Available" 1 "Generator Unavailable and Electric Propulsion OK" 2 "Generator Unavailable and Electric Propulsion Low" 3 "Generator Unavailable and No Electric Propulsion" ;
VAL_ 2149728256 ChrgPrtDrStat 0 "Inactive" 1 "Open Park" 2 "Open Moving" 3 "Fault" ;
VAL_ 2149728256 ChgCdTfAlCzStAvbl 1 "true" 0 "false" ;
VAL_ 2149728256 ChgCdTfAlCzCrStVal 0 "No Action" 1 "Off" 2 "On" 3 "Reserved 1" 4 "Reserved 2" 5 "Reserved 3" 6 "Reserved 4" 7 "Reserved 5" ;
VAL_ 2149728256 ChgPwLsAlCzStAvbl 1 "true" 0 "false" ;
VAL_ 2149728256 ChgPwLsAlCzCrStVal 0 "No Action" 1 "Off" 2 "On" 3 "Reserved 1" 4 "Reserved 2" 5 "Reserved 3" 6 "Reserved 4" 7 "Reserved 5" ;
VAL_ 2149728256 ChgSysAudInCsStAvl 1 "true" 0 "false" ;
VAL_ 2149728256 ChgSyAudInCsCrStVa 0 "No Action" 1 "Off" 2 "On" ;
VAL_ 2149728256 PrtyChrgActIO 1 "true" 0 "false" ;
VAL_ 2149728256 PrtyChrgAct 1 "true" 0 "false" ;
VAL_ 2149728256 HVChrgPwrLvl 1 "AC Level1" 2 "AC Level2" 3 "DC" 0 "Unavailable" ;
VAL_ 2149728256 ChrgSysTrnsShftLckRq 1 "true" 0 "false" ;
VAL_ 2155945984 VehStbEnhmntCurStRq 2 "On" 1 "Off" 0 "No Action" ;
VAL_ 2155945984 VehStbCmptvMdCurStRq 2 "On" 1 "Off" 0 "No Action" ;
VAL_ 2155945984 TCSysCurStReq 2 "On" 1 "Off" 0 "No Action" ;
VAL_ 2155945984 JmpStrtReq 1 "true" 0 "false" ;
VAL_ 2155585536 StBltTgtCSRq 0 "No Action" 1 "Low" 2 "Normal" 3 "Performance" 4 "Locked" ;
VAL_ 2155569152 HLOCCstSetReq 3 "On Open Only" 2 "On" 1 "Off" 0 "No Action" ;
VAL_ 2155569152 SmPhRmFunCstStReq 7 "Unused and Reserved 5" 6 "Unused and Reserved 4" 5 "Unused and Reserved 3" 4 "Unused and Reserved 2" 3 "Unused and Reserved 1" 2 "On" 1 "Off" 0 "No Action" ;
VAL_ 2155569152 IntDimSeldClrTypStReq 31 "Color Type 30" 30 "Color Type 29" 29 "Color Type 28" 28 "Color Type 27" 27 "Color Type 26" 26 "Color Type 25" 25 "Color Type 24" 24 "Color Type 23" 23 "Color Type 22" 22 "Color Type 21" 21 "Color Type 20" 20 "Color Type 19" 19 "Color Type 18" 18 "Color Type 17" 17 "Color Type 16" 16 "Color Type 15" 15 "Color Type 14" 14 "Color Type 13" 13 "Color Type 12" 12 "Color Type 11" 11 "Color Type 10" 10 "Color Type 9" 9 "Color Type 8" 8 "Color Type 7" 7 "Color Type 6" 6 "Color Type 5" 5 "Color Type 4" 4 "Color Type 3" 3 "Color Type 2" 2 "Color Type 1" 1 "Off" 0 "No Action" ;
VAL_ 2155569152 IntDimSeldAnmTypStReq 15 "Animation Type 14" 14 "Animation Type 13" 13 "Animation Type 12" 12 "Animation Type 11" 11 "Animation Type 10" 10 "Animation Type 9" 9 "Animation Type 8" 8 "Animation Type 7" 7 "Animation Type 6" 6 "Animation Type 5" 5 "Animation Type 4" 4 "Animation Type 3" 3 "Animation Type 2" 2 "Animation Type 1" 1 "Off" 0 "No Action" ;
VAL_ 2155569152 ExtHlStrAssCsStRq 2 "Standard Hold" 1 "Extended Hold" 0 "No Action" ;
VAL_ 2155569152 ColPrSysCustReq 4 "Alert and Brake and Steer" 0 "No Action" 1 "Off" 2 "Alert" 3 "Alert and Brake" ;
VAL_ 2150891520 DgtlMapPsgRstrctn 7 "Unknown Condition" 6 "Conditional When Snow" 5 "Conditional When Wet" 4 "Condtnl Tractors Allowed  Overtake" 3 "Condtnl Passenger Car With Trailer" 2 "LED Signs" 1 "General No Overtake" 0 "No Passing Restrictions" ;
VAL_ 2150891520 DgtlMapCndlSpdLmt 31 "Not Available" 30 "Unlimited" 29 "160 kmh_mph" 28 "150 kmh_mph" 27 "140 kmh_mph" 26 "130 kmh_mph" 25 "120 kmh_mph" 24 "115 kmh_mph" 23 "110 kmh_mph" 22 "105 kmh_mph" 21 "100 kmh_mph" 20 "95 kmh_mph" 19 "90 kmh_mph" 18 "85 kmh_mph" 17 "80 kmh_mph" 16 "75 kmh_mph" 15 "70 kmh_mph" 14 "65 kmh_mph" 13 "60 kmh_mph" 12 "55 kmh_mph" 11 "50 kmh_mph" 10 "45 kmh_mph" 9 "40 kmh_mph" 8 "35 kmh_mph" 7 "30 kmh_mph" 6 "25 kmh_mph" 5 "20 kmh_mph" 4 "15 kmh_mph" 3 "10 kmh_mph" 2 "7 kmh_mph" 1 "Less Than Or Equal To 5 km/h [mph]" 0 "Unknown" ;
VAL_ 2150891520 DgtlMapCndlSpdLmtTyp 5 "Condtnl Speed Limit Only By Rain" 4 "Condtnl Speed Limit By Time Of Day" 3 "Conditional Speed Limit Only By Day" 2 "Condtnl Speed Limit Only By Night" 1 "Conditional Speed Limit Only By Fog" 0 "Condtnl Speed Limit Lane Dependent" 7 "Unknown Conditional Speed Limit" 6 "Condtnl Speed Limit Only By Snow" ;
VAL_ 2150891520 DgtlMapEffSpdLmt 0 "Unknown" 1 "<= 5 km/h [mph]" 2 "7 km/h [mph]" 3 "10 km/h [mph]" 4 "15 km/h [mph]" 5 "20 km/h [mph]" 6 "25 km/h [mph]" 7 "30 km/h [mph]" 8 "35 km/h [mph]" 9 "40 km/h [mph]" 10 "45 km/h [mph]" 11 "50 km/h [mph]" 12 "55 km/h [mph]" 13 "60 km/h [mph]" 14 "65 km/h [mph]" 15 "70 km/h [mph]" 16 "75 km/h [mph]" 17 "80 km/h [mph]" 18 "85 km/h [mph]" 19 "90 km/h [mph]" 20 "95 km/h [mph]" 21 "100 km/h [mph]" 22 "105 km/h [mph]" 23 "110 km/h [mph]" 24 "115 km/h [mph]" 25 "120 km/h [mph]" 26 "130 km/h [mph]" 27 "140 km/h [mph]" 28 "150 km/h [mph]" 29 "160 km/h [mph]" 30 "Unlimited" 31 "Not Available" ;
VAL_ 2150891520 DgtlMapEffSpdLmtTyp 0 "Implicit" 1 "Explicit on Traffic Sign" 2 "Explicit Only by Night" 3 "Explicit Only by Day" 4 "Explicit Time of Day" 5 "Explicit Only by Rain" 6 "Explicit Only by Snow" 7 "Unknown" ;
VAL_ 2150891520 DgtlMapSpdCat 0 ">130 km/h" 1 "101-130 km/h" 2 "91-100 km/h" 3 "71-90  km/h" 4 "51-70 km/h" 5 "31-50 km/h" 6 "11-30 km/h" 7 "<11 km/h" ;
VAL_ 2150891520 DgtlMapVerQtr 0 "Quarter 1" 1 "Quarter 2" 2 "Quarter 3" 3 "Quarter 4" ;
VAL_ 2150891520 DgtlMapVerYr 0 "2000" 1 "2001" 2 "2002" 3 "2003" 4 "2004" 5 "2005" 6 "2006" 7 "2007" 8 "2008" 9 "2009" 10 "2010" 11 "2011" 12 "2012" 13 "2013" 14 "2014" 15 "2015" 16 "2016" 17 "2017" 18 "2018" 19 "2019" 20 "2020" 21 "2021" 22 "2022" 23 "2023" 24 "2024" 25 "2025" 26 "2026" 27 "2027" 28 "2028" 29 "2029" 30 "2030" 31 "2031" 32 "2032" 33 "2033" 34 "2034" 35 "2035" 36 "2036" 37 "2037" 38 "2038" 39 "2039" 40 "2040" 41 "2041" 42 "2042" 43 "2043" 44 "2044" 45 "2045" 46 "2046" 47 "2047" 48 "2048" 49 "2049" 50 "2050" 51 "2051" 52 "2052" 53 "2053" 54 "2054" 55 "2055" 56 "2056" 57 "2057" 58 "2058" 59 "2059" 60 "2060" 61 "2061" 62 "2062" 63 "N/A" ;
VAL_ 2150891520 DgtlMapDrvngSd 0 "Driving Side Left" 1 "Driving Side Right" ;
VAL_ 2150891520 RrStRmndrCstSetReq 2 "On" 1 "Off" 0 "No Action" ;
VAL_ 2150891520 FwdClnAlrtCustStngReq 0 "No Action" 1 "Off" 2 "On" ;
VAL_ 2150891520 GNCustStngReq 0 "No Action" 1 "Off" 2 "On" ;
VAL_ 2155536384 TnDrvRIMOffUnbIO 1 "true" 0 "false" ;
VAL_ 2155536384 RVBUnblIO 1 "true" 0 "false" ;
VAL_ 2155536384 RVBFldIO 1 "true" 0 "false" ;
VAL_ 2155536384 RVBEnbldIO 1 "true" 0 "false" ;
VAL_ 2155536384 RVBDsbldIO 1 "true" 0 "false" ;
VAL_ 2155536384 RevClnMtgnBrkReqAct 1 "true" 0 "false" ;
VAL_ 2151415808 FrPedDetCsCrStVal 3 "Alert and Brake" 2 "Alert" 1 "Off" 0 "No Action" ;
VAL_ 2151522304 ElEngyEconAvgRstRq 1 "true" 0 "false" ;
VAL_ 2151522304 BrkPdLfSysDrvrRq 4 "Reset Rear" 3 "Reset Front" 2 "Enable" 1 "Disable" 0 "No Action" ;
VAL_ 2151522304 LnchCtrlRelLnLockReqd 1 "true" 0 "false" ;
VAL_ 2151522304 TCSTmpDsblReqConf 2 "Yes" 1 "No" 0 "No Action" ;
VAL_ 2151522304 FuelFltLfRstRqd 1 "true" 0 "false" ;
VAL_ 2154979328 FrntStVoltBstModReq 1 "4 Wheel Vehicle (car, small trk)" 0 "Unknown" ;
VAL_ 2151505920 Trp2OdomtrV 1 "Invalid" 0 "Valid" ;
VAL_ 2151505920 Trp1OdomtrV 1 "Invalid" 0 "Valid" ;
VAL_ 2151505920 SpdCurvAdvSysEnbld 1 "true" 0 "false" ;
VAL_ 2151505920 PTExPrtclFltManRgnRqd 1 "true" 0 "false" ;
VAL_ 2151505920 AutoMdSpdLmtCnfrmd 1 "true" 0 "false" ;
VAL_ 2151505920 ACCSettingType 0 "Manual" 1 "Auto" ;
VAL_ 2151505920 TrlrBrkDsplyAct 1 "true" 0 "false" ;
VAL_ 2155552768 PsvEntCmftWndRq 3 "Measured this cycle" 2 "Latent track not detctd this cyc" 1 "New Object" 0 "No Object" ;
VAL_ 2150006784 SysPwrMdPshbtnActV 1 "Invalid" 0 "Valid" ;
VAL_ 2150006784 SysPwrMdPshbtnAct 1 "true" 0 "false" ;
VAL_ 2150006784 PEPSRunCrnkRlyDctd 1 "true" 0 "false" ;
VAL_ 2158911488 ODDMC_ReqType 0 "Subscribe: FU sends DynData back and then on change) " 1 "Unsubscribe: cancel previous Subscribe" ;
VAL_ 2158911488 ODDMC_DispMID 128 "Reserved" 64 "Reserved" 32 "OTIM" 16 "RearDisplayTwo" 8 "RearDisplayOne" 4 "AuxIP" 2 "CenterStack" 1 "IPC" ;
VAL_ 2158911488 ODDMC_DataID2Vld 1 "true" 0 "false" ;
VAL_ 2158911488 ODDMC_DataID3Vld 1 "true" 0 "false" ;
VAL_ 2158911488 ODDMC_DataID4Vld 1 "true" 0 "false" ;
VAL_ 2158911488 ODDMC_DataID5Vld 1 "true" 0 "false" ;
VAL_ 2158919680 ODDMI_ReqType 0 "Subscribe: FU sends DynData back and then on change) " 1 "Unsubscribe: cancel previous Subscribe" ;
VAL_ 2158919680 ODDMI_DispMID 64 "Reserved" 32 "OTIM" 16 "RearDisplayTwo" 8 "RearDisplayOne" 4 "AuxIP" 2 "CenterStack" 1 "IPC" 128 "Reserved" ;
VAL_ 2158919680 ODDMI_DataID2Vld 1 "true" 0 "false" ;
VAL_ 2158919680 ODDMI_DataID3Vld 1 "true" 0 "false" ;
VAL_ 2158919680 ODDMI_DataID4Vld 1 "true" 0 "false" ;
VAL_ 2158919680 ODDMI_DataID5Vld 1 "true" 0 "false" ;
VAL_ 2151825408 OtsAirTmpV 1 "Invalid" 0 "Valid" ;
VAL_ 2151825408 OtsAirTmpCrValV 1 "Invalid" 0 "Valid" ;
VAL_ 2151825408 OtsAirTmpCrValMsk 0 "Don't Use Data" 1 "Use Data" ;
VAL_ 2149711872 SetSpdLmtRchd 3 "Reserved" 2 "Low limit reached" 1 "High limit reached" 0 "No limit reached" ;
VAL_ 2149711872 FOAI_VehAhdIndRq 0 "No Alert" 1 "Alert Level 1" 2 "Alert Level 2" 3 "Alert Level 3" ;
VAL_ 2149711872 FOAI_AlrtWrnIndRq 0 "No Alert" 1 "Alert Level 1" 2 "Alert Level 2" 3 "Alert Level 3" ;
VAL_ 2149711872 FOAI_AlrtChmIhbRq 0 "Allow Chime" 1 "Inhibit Chime" ;
VAL_ 2149711872 FwdClnAlrtOffIO 1 "true" 0 "false" ;
VAL_ 2149711872 FwdClnAlrtPr 1 "true" 0 "false" ;
VAL_ 2149711872 ACCHdwyStg 7 "Headway Setting 7" 6 "Headway Setting 6" 5 "Headway Setting 5" 4 "Headway Setting 4" 3 "Headway Setting 3" 2 "Headway Setting 2" 1 "Headway Setting 1" 0 "Minimum Headway Setting" ;
VAL_ 2149711872 AdapCrsCntVDA 1 "VirtualDeviceAvailable" 0 "VirtualDeviceUnavailable" ;
VAL_ 2149711872 SpdLmtrSpdWrngEnbld 1 "true" 0 "false" ;
VAL_ 2149711872 CrsCntlDrSelSpdAct 1 "true" 0 "false" ;
VAL_ 2149711872 SpdLmtrSpdWrngAct 1 "true" 0 "false" ;
VAL_ 2149711872 AutoMdSpdLmtStat 0 "No Speed Limit Change" 1 "Proposed Speed Limit Change" 2 "Accepted Speed Limit Change" 3 "Declined Speed Limit Change" ;
VAL_ 2149711872 ACCAutoSetSpdStat 0 "No Set Speed Change" 1 "Proposed Speed Limit Change" 2 "Accepted Speed Limit Change" 3 "Declined Speed Limit Change" ;
VAL_ 2149711872 VehDynYawRateV 1 "Invalid" 0 "Valid" ;
VAL_ 2149711872 ACCAct370 1 "true" 0 "false" ;
VAL_ 2158854144 ODIAI_DaTy 21 "Bitmap" 20 "DecimalShort" 19 "HoursOfDay" 18 "Character" 17 "Fuel Consumption Inverted" 16 "Fuel Consumption" 15 "Pressure" 14 "Temperature" 13 "Volume" 12 "DistanceShort" 11 "DistanceLong" 10 "BitmapId" 9 "TextId" 8 "Pictogram" 7 "List " 6 "Date" 5 "Time " 4 "Decimal" 3 "EnumerationValue" 2 "Integer" 1 "String" 0 "Speed" ;
VAL_ 2158854144 ODIAI_DspMID 128 "Reserved" 64 "Reserved" 32 "OTIM" 16 "RearDisplayTwo" 8 "RearDisplayOne" 4 "AuxIP" 2 "CenterStack" 1 "IPC" ;
VAL_ 2149629952 RtTrnLmpOn 1 "true" 0 "false" ;
VAL_ 2149629952 LftTrnLmpOn 1 "true" 0 "false" ;
VAL_ 2149629952 FrFogLmpsAct 1 "true" 0 "false" ;
VAL_ 2149629952 HiBmReqd 1 "true" 0 "false" ;
VAL_ 2149629952 PrkLtRightOn 1 "true" 0 "false" ;
VAL_ 2149629952 PrkLtLeftOn 1 "true" 0 "false" ;
VAL_ 2149629952 PrkLtRightIO 1 "true" 0 "false" ;
VAL_ 2149629952 MainLghtSw 3 "HEADLAMP" 2 "PARKLAMP" 1 "OFF" 0 "AUTO" ;
VAL_ 2149629952 PrkLtLeftIO 1 "true" 0 "false" ;
VAL_ 2149629952 HiBmIO 1 "true" 0 "false" ;
VAL_ 2149629952 FrFgLtIO 1 "true" 0 "false" ;
VAL_ 2149629952 AutoLtsInactIO 1 "true" 0 "false" ;
VAL_ 2149629952 AutoLtsActIO 1 "true" 0 "false" ;
VAL_ 2149629952 RevLmpAtv 1 "true" 0 "false" ;
VAL_ 2149629952 HdlmpBmSelectStat 2 "High Beams" 1 "Low Beams" 0 "Unknown" ;
VAL_ 2149629952 SrvlnceMdAct 1 "true" 0 "false" ;
VAL_ 2149629952 RrFgLtIO 1 "true" 0 "false" ;
VAL_ 2149629952 PrkLtIO 1 "true" 0 "false" ;
VAL_ 2149629952 RrFogLmpsAct 1 "true" 0 "false" ;
VAL_ 2149629952 PrkngLtsAct 1 "true" 0 "false" ;
VAL_ 2149629952 BrkLtsAtv 1 "true" 0 "false" ;
VAL_ 2149629952 AutoBmSlctAllwd 1 "true" 0 "false" ;
VAL_ 2149629952 FlToPsSwAtv 1 "true" 0 "false" ;
VAL_ 2149629952 DRLAct 1 "true" 0 "false" ;
VAL_ 2149629952 TrnSwAct 2 "Right" 1 "Left" 0 "No Activation" ;
VAL_ 2149629952 HazSwAtv 1 "true" 0 "false" ;
VAL_ 2149629952 LftTrnLmpAtv 2 "On with telltale" 1 "On without telltale" 0 "Off" ;
VAL_ 2149629952 RtTrnLmpAtv 1 "On without telltale" 0 "Off" 2 "On with telltale" ;
VAL_ 2149629952 OtsdAmbtLtLvlStatV 1 "Invalid" 0 "Valid" ;
VAL_ 2149629952 OtsdAmbtLtLvlStat 2 "Day" 1 "Night" 0 "Unknown" ;
VAL_ 2155028480 RgtLnChgThrt 1 "true" 0 "false" ;
VAL_ 2149941248 PrkAstRrObjSnsngAct 1 "true" 0 "false" ;
VAL_ 2149941248 PrkAstRrSysStatUnfltd 0 "Disabled" 1 "Enabled" 2 "Inhibited" 3 "Failed" ;
VAL_ 2149941248 PrkAstFntnSnsDstrbdIO 1 "true" 0 "false" ;
VAL_ 2149941248 PrkAstFntnSnrsBlkd 1 "true" 0 "false" ;
VAL_ 2149941248 PrkAstFntnFld 1 "true" 0 "false" ;
VAL_ 2149941248 PrkAstFntnDsbldIO 1 "true" 0 "false" ;
VAL_ 2149941248 PrkAstFntnClnPrkAstIO 1 "true" 0 "false" ;
VAL_ 2149941248 ClsnMtgtnInhbtReqtd 1 "true" 0 "false" ;
VAL_ 2149941248 PARrRgn4ObjStatUnfltd 0 "No Object" 1 "Zone 1" 2 "Zone 2" 3 "Zone 3" 4 "Zone 4" 5 "Zone 5" 6 "Zone 6" 7 "Zone 7" 8 "Zone 8" 9 "Zone 9" 10 "Zone 10" 11 "Zone 11" 12 "Zone 12" 13 "Zone 13" 14 "Zone 14" 15 "Zone 15" ;
VAL_ 2149941248 PARrRgn3ObjStatUnfltd 0 "No Object" 1 "Zone 1" 2 "Zone 2" 3 "Zone 3" 4 "Zone 4" 5 "Zone 5" 6 "Zone 6" 7 "Zone 7" 8 "Zone 8" 9 "Zone 9" 10 "Zone 10" 11 "Zone 11" 12 "Zone 12" 13 "Zone 13" 14 "Zone 14" 15 "Zone 15" ;
VAL_ 2149941248 PARrRgn2ObjStatUnfltd 0 "No Object" 1 "Zone 1" 2 "Zone 2" 3 "Zone 3" 4 "Zone 4" 5 "Zone 5" 6 "Zone 6" 7 "Zone 7" 8 "Zone 8" 9 "Zone 9" 10 "Zone 10" 11 "Zone 11" 12 "Zone 12" 13 "Zone 13" 14 "Zone 14" 15 "Zone 15" ;
VAL_ 2149941248 PARrRgn1ObjStatUnfltd 0 "No Object" 1 "Zone 1" 2 "Zone 2" 3 "Zone 3" 4 "Zone 4" 5 "Zone 5" 6 "Zone 6" 7 "Zone 7" 8 "Zone 8" 9 "Zone 9" 10 "Zone 10" 11 "Zone 11" 12 "Zone 12" 13 "Zone 13" 14 "Zone 14" 15 "Zone 15" ;
VAL_ 2151342080 PrkAstRtSysStat 0 "Disabled" 1 "Enabled" 2 "Inhibited" 3 "Failed" ;
VAL_ 2151342080 PARtRgn3ObjStat 0 "No Object" 1 "Zone 1" 2 "Zone 2" 3 "Zone 3" 4 "Zone 4" 5 "Zone 5" 6 "Zone 6" 7 "Zone 7" 8 "Zone 8" 9 "Zone 9" 10 "Zone 10" 11 "Zone 11" 12 "Zone 12" 13 "Zone 13" 14 "Zone 14" 15 "Zone 15" ;
VAL_ 2151342080 PARtRgn2ObjStat 0 "No Object" 1 "Zone 1" 2 "Zone 2" 3 "Zone 3" 4 "Zone 4" 5 "Zone 5" 6 "Zone 6" 7 "Zone 7" 8 "Zone 8" 9 "Zone 9" 10 "Zone 10" 11 "Zone 11" 12 "Zone 12" 13 "Zone 13" 14 "Zone 14" 15 "Zone 15" ;
VAL_ 2151342080 PARtRgn1ObjStat 0 "No Object" 1 "Zone 1" 2 "Zone 2" 3 "Zone 3" 4 "Zone 4" 5 "Zone 5" 6 "Zone 6" 7 "Zone 7" 8 "Zone 8" 9 "Zone 9" 10 "Zone 10" 11 "Zone 11" 12 "Zone 12" 13 "Zone 13" 14 "Zone 14" 15 "Zone 15" ;
VAL_ 2151325696 PrkAstLtSysStat 0 "Disabled" 1 "Enabled" 2 "Inhibited" 3 "Failed" ;
VAL_ 2151325696 PALtRgn3ObjStat 0 "No Object" 1 "Zone 1" 2 "Zone 2" 3 "Zone 3" 4 "Zone 4" 5 "Zone 5" 6 "Zone 6" 7 "Zone 7" 8 "Zone 8" 9 "Zone 9" 10 "Zone 10" 11 "Zone 11" 12 "Zone 12" 13 "Zone 13" 14 "Zone 14" 15 "Zone 15" ;
VAL_ 2151325696 PALtRgn2ObjStat 0 "No Object" 1 "Zone 1" 2 "Zone 2" 3 "Zone 3" 4 "Zone 4" 5 "Zone 5" 6 "Zone 6" 7 "Zone 7" 8 "Zone 8" 9 "Zone 9" 10 "Zone 10" 11 "Zone 11" 12 "Zone 12" 13 "Zone 13" 14 "Zone 14" 15 "Zone 15" ;
VAL_ 2151325696 PALtRgn1ObjStat 0 "No Object" 1 "Zone 1" 2 "Zone 2" 3 "Zone 3" 4 "Zone 4" 5 "Zone 5" 6 "Zone 6" 7 "Zone 7" 8 "Zone 8" 9 "Zone 9" 10 "Zone 10" 11 "Zone 11" 12 "Zone 12" 13 "Zone 13" 14 "Zone 14" 15 "Zone 15" ;
VAL_ 2151350272 APAIconDispRq 7 "Unused & Reserved" 6 "Unused & Reserved" 5 "Unused & Reserved" 4 "Complete" 3 "Stop" 2 "Reverse" 1 "Forward" 0 "No Icon" ;
VAL_ 2158796800 ODII_ODIInd55 1 "true" 0 "false" ;
VAL_ 2158796800 ODII_ODIInd54 1 "true" 0 "false" ;
VAL_ 2158796800 ODII_ODIInd53 1 "true" 0 "false" ;
VAL_ 2158796800 ODII_ODIInd52 1 "true" 0 "false" ;
VAL_ 2158796800 ODII_ODIInd51 1 "true" 0 "false" ;
VAL_ 2158796800 ODII_ODIInd50 1 "true" 0 "false" ;
VAL_ 2158796800 ODII_ODIInd27 1 "true" 0 "false" ;
VAL_ 2158796800 ODII_ODIInd26 1 "true" 0 "false" ;
VAL_ 2158796800 ODII_ODIInd25 1 "true" 0 "false" ;
VAL_ 2158796800 ODII_ODIInd24 1 "true" 0 "false" ;
VAL_ 2158796800 ODII_ODIInd23 1 "true" 0 "false" ;
VAL_ 2158796800 ODII_ODIInd22 1 "true" 0 "false" ;
VAL_ 2158796800 ODII_ODIInd21 1 "true" 0 "false" ;
VAL_ 2158796800 ODII_ODIInd20 1 "true" 0 "false" ;
VAL_ 2158796800 ODII_ODIInd19 1 "true" 0 "false" ;
VAL_ 2158796800 ODII_ODIInd18 1 "true" 0 "false" ;
VAL_ 2158796800 ODII_ODIInd17 1 "true" 0 "false" ;
VAL_ 2158796800 ODII_ODIInd16 1 "true" 0 "false" ;
VAL_ 2158796800 ODII_ODIInd15 1 "true" 0 "false" ;
VAL_ 2158796800 ODII_ODIInd14 1 "true" 0 "false" ;
VAL_ 2158796800 ODII_ODIInd13 1 "true" 0 "false" ;
VAL_ 2158796800 ODII_ODIInd12 1 "true" 0 "false" ;
VAL_ 2158796800 ODII_ODIInd11 1 "true" 0 "false" ;
VAL_ 2158796800 ODII_ODIInd10 1 "true" 0 "false" ;
VAL_ 2158796800 ODII_ODIInd9 1 "true" 0 "false" ;
VAL_ 2158796800 ODII_ODIInd8 1 "true" 0 "false" ;
VAL_ 2158796800 ODII_ODIInd7 1 "true" 0 "false" ;
VAL_ 2158796800 ODII_ODIInd6 1 "true" 0 "false" ;
VAL_ 2158796800 ODII_ODIInd5 1 "true" 0 "false" ;
VAL_ 2158796800 ODII_ODIInd4 1 "true" 0 "false" ;
VAL_ 2158796800 ODII_ODIInd3 1 "true" 0 "false" ;
VAL_ 2158796800 ODII_ODIInd2 1 "true" 0 "false" ;
VAL_ 2158796800 ODII_ODIInd1 1 "true" 0 "false" ;
VAL_ 2158796800 ODII_ODIInd56 1 "true" 0 "false" ;
VAL_ 2158796800 ODII_ODIInd49 1 "true" 0 "false" ;
VAL_ 2158796800 ODII_ODIInd48 1 "true" 0 "false" ;
VAL_ 2158796800 ODII_ODIInd47 1 "true" 0 "false" ;
VAL_ 2158796800 ODII_ODIInd46 1 "true" 0 "false" ;
VAL_ 2158796800 ODII_ODIInd45 1 "true" 0 "false" ;
VAL_ 2158796800 ODII_ODIInd44 1 "true" 0 "false" ;
VAL_ 2158796800 ODII_ODIInd43 1 "true" 0 "false" ;
VAL_ 2158796800 ODII_ODIInd42 1 "true" 0 "false" ;
VAL_ 2158796800 ODII_ODIInd41 1 "true" 0 "false" ;
VAL_ 2158796800 ODII_ODIInd40 1 "true" 0 "false" ;
VAL_ 2158796800 ODII_ODIInd39 1 "true" 0 "false" ;
VAL_ 2158796800 ODII_ODIInd38 1 "true" 0 "false" ;
VAL_ 2158796800 ODII_ODIInd37 1 "true" 0 "false" ;
VAL_ 2158796800 ODII_ODIInd36 1 "true" 0 "false" ;
VAL_ 2158796800 ODII_ODIInd35 1 "true" 0 "false" ;
VAL_ 2158796800 ODII_ODIInd34 1 "true" 0 "false" ;
VAL_ 2158796800 ODII_ODIInd33 1 "true" 0 "false" ;
VAL_ 2158796800 ODII_ODIInd32 1 "true" 0 "false" ;
VAL_ 2158796800 ODII_ODIInd31 1 "true" 0 "false" ;
VAL_ 2158796800 ODII_ODIInd30 1 "true" 0 "false" ;
VAL_ 2158796800 ODII_ODIInd29 1 "true" 0 "false" ;
VAL_ 2158796800 ODII_ODIInd28 1 "true" 0 "false" ;
SIG_GROUP_ 2149826560 FwdObjAlrtInd11E 1 : FOAI_VehAhdIndRq11E FOAI_AlrtWrnIndRq11E FOAI_AlrtChmIhbRq11E;
SIG_GROUP_ 2156331008 EngyUsgScrDsp 1 : EUSD_MsrmntUnit EUSD_MsrmntVal;
SIG_GROUP_ 2150375424 LBCCstmrDaRstReq 1 : LBCCDRR_ClrStrdPosReq LBCCDRR_PosNum;
SIG_GROUP_ 2158149632 EngyCnsHsGrphCnfgDt 1 : ECHGCD_XAxTkMrkInterv ECHGCD_YAxMaxVal ECHGCD_MeasUt;
SIG_GROUP_ 2158149632 HVBatTmBsSsnChRsp 1 : HVBTBSCR_SsnDyStat HVBTBSCR_SsnStat HVBTBSCR_SsnSlctStat HVBTBSCR_SsnMthStat;
SIG_GROUP_ 2158149632 HVBatTmBsChrgRtRsp 1 : HVBTBCRS_ChRtDStat HVBTBCRS_ChRtSlctStat HVBTBCRS_ChRtEnblStat;
SIG_GROUP_ 2150547456 OffBrdHVBlkChgCpltTm 1 : OBHVBCCT_MinofHr OBHVBCCT_HrofDay OBHVBCCT_DayofWk;
SIG_GROUP_ 2158911488 ODIDynDataMltRq_CntrStck 1 : ODDMC_ReqType ODDMC_DispMID ODDMC_DataID2Vld ODDMC_DataID2 ODDMC_DataID3Vld ODDMC_DataID3 ODDMC_DataID1 ODDMC_DataID4Vld ODDMC_DataID4 ODDMC_DataID5Vld ODDMC_DataID5 ODDMC_FUCID;
SIG_GROUP_ 2158919680 ODIDynDataMltRq_IPC 1 : ODDMI_ReqType ODDMI_FUCID ODDMI_DispMID ODDMI_DataID2Vld ODDMI_DataID2 ODDMI_DataID3Vld ODDMI_DataID3 ODDMI_DataID1 ODDMI_DataID4Vld ODDMI_DataID4 ODDMI_DataID5Vld ODDMI_DataID5;
SIG_GROUP_ 2149711872 FwdObjAlrtInd 1 : FOAI_VehAhdIndRq FOAI_AlrtWrnIndRq FOAI_AlrtChmIhbRq;
SIG_GROUP_ 2158854144 ODIActn_IPC 1 : ODIAI_DaTy ODIAI_FUCID ODIAI_DspMID ODIAI_ActnVal ODIAI_ActnID;
SIG_GROUP_ 2158796800 ODIInd 1 : ODII_ODIInd55 ODII_ODIInd54 ODII_ODIInd53 ODII_ODIInd52 ODII_ODIInd51 ODII_ODIInd50 ODII_ODIInd27 ODII_ODIInd26 ODII_ODIInd25 ODII_ODIInd24 ODII_ODIInd23 ODII_ODIInd22 ODII_ODIInd21 ODII_ODIInd20 ODII_ODIInd19 ODII_ODIInd18 ODII_ODIInd17 ODII_ODIInd16 ODII_ODIInd15 ODII_ODIInd14 ODII_ODIInd13 ODII_ODIInd12 ODII_ODIInd11 ODII_ODIInd10 ODII_ODIInd9 ODII_ODIInd8 ODII_ODIInd7 ODII_ODIInd6 ODII_ODIInd5 ODII_ODIInd4 ODII_ODIInd3 ODII_ODIInd2 ODII_ODIInd1 ODII_ODIInd56 ODII_ODIInd49 ODII_ODIInd48 ODII_ODIInd47 ODII_ODIInd46 ODII_ODIInd45 ODII_ODIInd44 ODII_ODIInd43 ODII_ODIInd42 ODII_ODIInd41 ODII_ODIInd40 ODII_ODIInd39 ODII_ODIInd38 ODII_ODIInd37 ODII_ODIInd36 ODII_ODIInd35 ODII_ODIInd34 ODII_ODIInd33 ODII_ODIInd32 ODII_ODIInd31 ODII_ODIInd30 ODII_ODIInd29 ODII_ODIInd28 ODII_FUCID;
